VERSION ""

NS_ :

BS_:

BU_: VCU_LE CHUD_LE VKM_LE RCRM_LE VPM_LE EDI_LE V2V_LE TCP_LE CSM_LE UHP_Low_LE TouchPad_LE RSE_LE RSC_LE RSA_LE PDIM_LE OTIM_LE ICS_LE LVMPC_LE LVMNav_LE DVB_T_LE ONSTAR_LE HUD_LE IPC_LE RadioHead_LE CHM_LE Dummy_LE CGM_LE AMP_LE

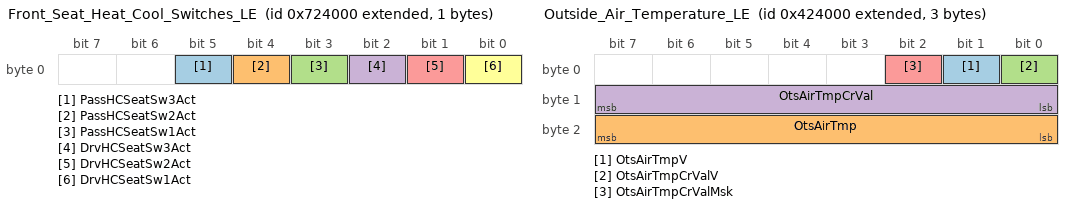
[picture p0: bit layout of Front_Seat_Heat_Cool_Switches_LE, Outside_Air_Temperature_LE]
BO_ 2154971136 Front_Seat_Heat_Cool_Switches_LE: 1 ICS_LE
 SG_ PassHCSeatSw3Act : 5|1@0+ (1,0) [0|1] ""  CGM_LE
 SG_ PassHCSeatSw2Act : 4|1@0+ (1,0) [0|1] ""  CGM_LE
 SG_ PassHCSeatSw1Act : 3|1@0+ (1,0) [0|1] ""  CGM_LE
 SG_ DrvHCSeatSw3Act : 2|1@0+ (1,0) [0|1] ""  CGM_LE
 SG_ DrvHCSeatSw2Act : 1|1@0+ (1,0) [0|1] ""  CGM_LE
 SG_ DrvHCSeatSw1Act : 0|1@0+ (1,0) [0|1] ""  CGM_LE

BO_ 2154962944 Front_Seat_Heat_Cool_Control_LE: 4 CGM_LE
 SG_ PassHCSMInd3 : 8|1@0+ (1,0) [0|1] ""  CSM_LE,ONSTAR_LE,ICS_LE
 SG_ PassHCSMInd2 : 9|1@0+ (1,0) [0|1] ""  CSM_LE,ONSTAR_LE,ICS_LE
 SG_ PassHCSMInd1 : 10|1@0+ (1,0) [0|1] ""  CSM_LE,ONSTAR_LE,ICS_LE
 SG_ PassHCSMIndReq : 12|2@0+ (1,0) [0|3] ""  CSM_LE,ONSTAR_LE,ICS_LE
 SG_ PassHCSLSeatLev5 : 24|1@0+ (1,0) [0|1] ""  CSM_LE,ONSTAR_LE,VCU_LE,IPC_LE,ICS_LE
 SG_ PassHCSLSeatLev4 : 25|1@0+ (1,0) [0|1] ""  CSM_LE,ONSTAR_LE,VCU_LE,IPC_LE,ICS_LE
 SG_ PassHCSLSeatLev3 : 26|1@0+ (1,0) [0|1] ""  CSM_LE,ONSTAR_LE,VCU_LE,IPC_LE,ICS_LE
 SG_ PassHCSLSeatLev2 : 27|1@0+ (1,0) [0|1] ""  CSM_LE,ONSTAR_LE,VCU_LE,IPC_LE,ICS_LE
 SG_ PassHCSLSeatLev1 : 28|1@0+ (1,0) [0|1] ""  CSM_LE,ONSTAR_LE,VCU_LE,IPC_LE,ICS_LE
 SG_ PassHCSLIndReq : 30|2@0+ (1,0) [0|3] ""  CSM_LE,ONSTAR_LE,VCU_LE,IPC_LE,ICS_LE
 SG_ DrvHCSMInd1 : 2|1@0+ (1,0) [0|1] ""  CSM_LE,ONSTAR_LE,ICS_LE
 SG_ DrvHCSMIndReq : 4|2@0+ (1,0) [0|3] ""  CSM_LE,ONSTAR_LE,ICS_LE
 SG_ DrvHCSMInd3 : 0|1@0+ (1,0) [0|1] ""  CSM_LE,ONSTAR_LE,ICS_LE
 SG_ DrvHCSMInd2 : 1|1@0+ (1,0) [0|1] ""  CSM_LE,ONSTAR_LE,ICS_LE
 SG_ DrvHCSLSeatLev5 : 16|1@0+ (1,0) [0|1] ""  CSM_LE,ONSTAR_LE,VCU_LE,IPC_LE,ICS_LE
 SG_ DrvHCSLSeatLev4 : 17|1@0+ (1,0) [0|1] ""  CSM_LE,ONSTAR_LE,VCU_LE,IPC_LE,ICS_LE
 SG_ DrvHCSLSeatLev3 : 18|1@0+ (1,0) [0|1] ""  CSM_LE,ONSTAR_LE,VCU_LE,IPC_LE,ICS_LE
 SG_ DrvHCSLSeatLev2 : 19|1@0+ (1,0) [0|1] ""  CSM_LE,ONSTAR_LE,VCU_LE,IPC_LE,ICS_LE
 SG_ DrvHCSLSeatLev1 : 20|1@0+ (1,0) [0|1] ""  CSM_LE,ONSTAR_LE,VCU_LE,IPC_LE,ICS_LE
 SG_ DrvHCSLIndReq : 22|2@0+ (1,0) [0|3] ""  CSM_LE,ONSTAR_LE,VCU_LE,IPC_LE,ICS_LE

BO_ 2151825408 Outside_Air_Temperature_LE: 3 IPC_LE
 SG_ OtsAirTmpV : 1|1@0+ (1,0) [0|1] ""  LVMPC_LE,RSE_LE,CSM_LE,EDI_LE,LVMNav_LE,VCU_LE,RadioHead_LE,CGM_LE
 SG_ OtsAirTmp : 23|8@0+ (0.5,-40) [-40|87.5] "deg C"  LVMPC_LE,RSE_LE,CSM_LE,EDI_LE,LVMNav_LE,VCU_LE,RadioHead_LE,ICS_LE,CGM_LE
 SG_ OtsAirTmpCrValV : 0|1@0+ (1,0) [0|1] ""  EDI_LE,CSM_LE,LVMNav_LE,RadioHead_LE,VCU_LE,IPC_LE,CGM_LE
 SG_ OtsAirTmpCrVal : 15|8@0+ (0.5,-40) [-40|87.5] "deg C"  TCP_LE,ONSTAR_LE,EDI_LE,CSM_LE,LVMNav_LE,RadioHead_LE,VCU_LE,IPC_LE,CGM_LE
 SG_ OtsAirTmpCrValMsk : 2|1@0+ (1,0) [0|1] ""  EDI_LE,CSM_LE,LVMNav_LE,RadioHead_LE,VCU_LE,IPC_LE,CGM_LE

BO_ 2150760448 Airbag_Impact_Data_LE: 8 CGM_LE
 SG_ NotSndRwRtSeatStat : 13|2@0+ (1,0) [0|3] ""  TCP_LE,ONSTAR_LE
 SG_ NotSndRwMdlSeatStat : 11|2@0+ (1,0) [0|3] ""  TCP_LE,ONSTAR_LE
 SG_ NotSndRwLtSeatStat : 15|2@0+ (1,0) [0|3] ""  TCP_LE,ONSTAR_LE
 SG_ NotPsSeatStat : 5|2@0+ (1,0) [0|3] ""  TCP_LE,ONSTAR_LE
 SG_ NotDrvSeatStat : 7|2@0+ (1,0) [0|3] ""  TCP_LE,ONSTAR_LE
 SG_ NotSecRowRtSeaOccStat : 9|2@0+ (1,0) [0|3] ""  TCP_LE,ONSTAR_LE
 SG_ NotSecRowLeSeaOccStat : 25|2@0+ (1,0) [0|3] ""  TCP_LE,ONSTAR_LE
 SG_ NotSecRowCtSeaOccStat : 27|2@0+ (1,0) [0|3] ""  TCP_LE,ONSTAR_LE
 SG_ NotiFrntPasSeatOccSta : 34|3@0+ (1,0) [0|7] ""  TCP_LE,ONSTAR_LE
 SG_ NotEventStat : 17|2@0+ (1,0) [0|3] ""  VPM_LE,TCP_LE,ONSTAR_LE
 SG_ NotiEventCount : 63|8@0+ (1,0) [0|255] ""  TCP_LE,ONSTAR_LE
 SG_ NESSRoSevSt : 48|1@0+ (1,0) [0|1] ""  TCP_LE,ONSTAR_LE
 SG_ NESSRiSiSevSt : 49|1@0+ (1,0) [0|1] ""  TCP_LE,ONSTAR_LE
 SG_ NESSReImpSevSt : 50|1@0+ (1,0) [0|1] ""  TCP_LE,ONSTAR_LE
 SG_ NESSLeSiSevSt : 51|1@0+ (1,0) [0|1] ""  TCP_LE,ONSTAR_LE
 SG_ NESSFrImpSt2SevSt : 52|1@0+ (1,0) [0|1] ""  TCP_LE,ONSTAR_LE
 SG_ NESSFrImpSt1SevSt : 53|1@0+ (1,0) [0|1] ""  TCP_LE,ONSTAR_LE
 SG_ NESSFrImpPreSevSt : 54|1@0+ (1,0) [0|1] ""  TCP_LE,ONSTAR_LE
 SG_ NEDLSRtSdArbgDld : 41|1@0+ (1,0) [0|1] ""  VCU_LE,CSM_LE,RadioHead_LE,TCP_LE,ONSTAR_LE
 SG_ NEDLSLtSdArbgDld : 42|1@0+ (1,0) [0|1] ""  VCU_LE,CSM_LE,RadioHead_LE,TCP_LE,ONSTAR_LE
 SG_ NEDLSSdCrtnArbgDpld : 40|1@0+ (1,0) [0|1] ""  VCU_LE,CSM_LE,RadioHead_LE,TCP_LE,ONSTAR_LE
 SG_ NEDLSPaFrSt2De : 43|1@0+ (1,0) [0|1] ""  VCU_LE,CSM_LE,RadioHead_LE,TCP_LE,ONSTAR_LE
 SG_ NEDLSPaFrSt1De : 44|1@0+ (1,0) [0|1] ""  VCU_LE,CSM_LE,RadioHead_LE,TCP_LE,ONSTAR_LE
 SG_ NEDLSDrFrSt2De : 45|1@0+ (1,0) [0|1] ""  VCU_LE,CSM_LE,RadioHead_LE,TCP_LE,ONSTAR_LE
 SG_ NEDLSDrFrSt1De : 46|1@0+ (1,0) [0|1] ""  VCU_LE,CSM_LE,RadioHead_LE,TCP_LE,ONSTAR_LE
 SG_ SIRDpl : 1|1@0+ (1,0) [0|1] ""  V2V_LE,TCP_LE,CSM_LE,OTIM_LE,ONSTAR_LE,VCU_LE,RadioHead_LE,ICS_LE

BO_ 1609 USDT_Resp_From_OTIM_LE: 8 OTIM_LE
 SG_ DgnInf : 7|64@0+ (1,0) [0|1.84467440737096E+019] ""  CSM_LE,CGM_LE,TCP_LE,ONSTAR_LE

BO_ 1577 VNMF_LE_629_OTIM: 8 OTIM_LE
 SG_ VectraSpcNWMgtD : 7|64@0+ (1,0) [0|1.84467440737096E+019] ""  RCRM_LE,V2V_LE,TCP_LE,UHP_Low_LE,LVMNav_LE,ONSTAR_LE,VKM_LE,RSC_LE,RSE_LE,RSA_LE,PDIM_LE,CHUD_LE,LVMPC_LE,IPC_LE,ICS_LE,VPM_LE,HUD_LE,TouchPad_LE,DVB_T_LE,VCU_LE,CSM_LE,RadioHead_LE,CHM_LE,AMP_LE,CGM_LE

BO_ 1353 UUDT_Resp_From_OTIM_LE: 8 OTIM_LE
 SG_ DgnInf_LS549 : 7|64@0+ (1,0) [0|1.84467440737096E+019] ""  CSM_LE,CGM_LE,TCP_LE,ONSTAR_LE

BO_ 2159239168 ODI_TEL_2_OTIM_LE: 8 ONSTAR_LE
 SG_ ODI_TEL2OTIM : 7|64@0+ (1,0) [0|1.84467440737096E+019] ""  OTIM_LE

BO_ 2159230976 ODI_OTIM_2_TEL_LE: 8 OTIM_LE
 SG_ ODI_OTIM2TEL : 7|64@0+ (1,0) [0|1.84467440737096E+019] ""  TCP_LE,ONSTAR_LE

BO_ 2159149056 ODI_TEL_2_CenterStack_LE: 8 ONSTAR_LE
 SG_ ODI_TEL2CntrStck : 7|64@0+ (1,0) [0|1.84467440737096E+019] ""  CSM_LE,VCU_LE,RadioHead_LE

BO_ 2159083520 ODI_TEL_2_IPC_LE: 8 ONSTAR_LE
 SG_ ODI_TEL2IPC : 7|64@0+ (1,0) [0|1.84467440737096E+019] ""  VCU_LE,IPC_LE

BO_ 2150227968 Phone_Speech_Rec_Status_LE: 1 ONSTAR_LE
 SG_ PhnSpRcgnApSt : 1|2@0+ (1,0) [0|3] ""  CSM_LE,OTIM_LE,VCU_LE,RadioHead_LE

BO_ 2150219776 Voice_Recognition_Status_LE: 1 RadioHead_LE
 SG_ PhnSpRcgnRq : 1|2@0+ (1,0) [0|3] ""  UHP_Low_LE,ONSTAR_LE
 SG_ VcRecVcFdbckSt : 3|2@0+ (1,0) [0|3] ""  UHP_Low_LE

BO_ 1358 UUDT_Resp_From_RSC_LE: 8 RSC_LE
 SG_ DgnInf_LS54E : 7|64@0+ (1,0) [0|1.84467440737096E+019] ""  CSM_LE,CGM_LE,TCP_LE,ONSTAR_LE

BO_ 1582 VNMF_LE_62E_RSC: 8 RSC_LE
 SG_ VectraSpcNWMgtD : 7|64@0+ (1,0) [0|1.84467440737096E+019] ""  RCRM_LE,V2V_LE,TCP_LE,UHP_Low_LE,LVMNav_LE,ONSTAR_LE,RSE_LE,RSA_LE,PDIM_LE,OTIM_LE,CHUD_LE,LVMPC_LE,IPC_LE,ICS_LE,VPM_LE,HUD_LE,TouchPad_LE,DVB_T_LE,VCU_LE,CSM_LE,RadioHead_LE,CHM_LE,AMP_LE,CGM_LE

BO_ 1614 USDT_Resp_From_RSC_LE: 8 RSC_LE
 SG_ DgnInf : 7|64@0+ (1,0) [0|1.84467440737096E+019] ""  CSM_LE,CGM_LE,TCP_LE,ONSTAR_LE

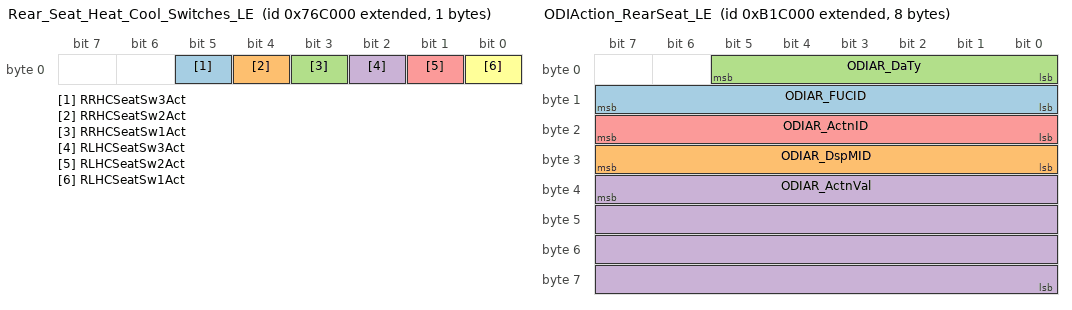
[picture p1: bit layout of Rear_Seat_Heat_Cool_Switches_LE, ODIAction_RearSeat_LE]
BO_ 2155266048 Rear_Seat_Heat_Cool_Switches_LE: 1 RSA_LE
 SG_ RRHCSeatSw3Act : 5|1@0+ (1,0) [0|1] ""  CGM_LE
 SG_ RRHCSeatSw2Act : 4|1@0+ (1,0) [0|1] ""  CGM_LE
 SG_ RRHCSeatSw1Act : 3|1@0+ (1,0) [0|1] ""  CGM_LE
 SG_ RLHCSeatSw3Act : 2|1@0+ (1,0) [0|1] ""  CGM_LE
 SG_ RLHCSeatSw2Act : 1|1@0+ (1,0) [0|1] ""  CGM_LE
 SG_ RLHCSeatSw1Act : 0|1@0+ (1,0) [0|1] ""  CGM_LE

BO_ 2155249664 Rear_Seat_Heat_Cool_Control_LE: 4 CGM_LE
 SG_ RRHCSMInd3 : 8|1@0+ (1,0) [0|1] ""  RSC_LE,RSA_LE
 SG_ RRHCSMInd2 : 9|1@0+ (1,0) [0|1] ""  RSC_LE,RSA_LE
 SG_ RRHCSMInd1 : 10|1@0+ (1,0) [0|1] ""  RSC_LE,RSA_LE
 SG_ RRHCSMIndReq : 12|2@0+ (1,0) [0|3] ""  RSC_LE,RSA_LE
 SG_ RRHCSLSeatLev5 : 24|1@0+ (1,0) [0|1] ""  VCU_LE,IPC_LE,RSC_LE,RSA_LE
 SG_ RRHCSLSeatLev4 : 25|1@0+ (1,0) [0|1] ""  VCU_LE,IPC_LE,RSC_LE,RSA_LE
 SG_ RRHCSLSeatLev3 : 26|1@0+ (1,0) [0|1] ""  VCU_LE,IPC_LE,RSC_LE,RSA_LE
 SG_ RRHCSLSeatLev2 : 27|1@0+ (1,0) [0|1] ""  VCU_LE,IPC_LE,RSC_LE,RSA_LE
 SG_ RRHCSLSeatLev1 : 28|1@0+ (1,0) [0|1] ""  VCU_LE,IPC_LE,RSC_LE,RSA_LE
 SG_ RRHCSLIndReq : 30|2@0+ (1,0) [0|3] ""  VCU_LE,IPC_LE,RSC_LE,RSA_LE
 SG_ RLHCSMInd3 : 0|1@0+ (1,0) [0|1] ""  RSC_LE,RSA_LE
 SG_ RLHCSMInd2 : 1|1@0+ (1,0) [0|1] ""  RSC_LE,RSA_LE
 SG_ RLHCSMInd1 : 2|1@0+ (1,0) [0|1] ""  RSC_LE,RSA_LE
 SG_ RLHCSMIndReq : 4|2@0+ (1,0) [0|3] ""  RSC_LE,RSA_LE
 SG_ RLHCSLSeatLev5 : 16|1@0+ (1,0) [0|1] ""  VCU_LE,IPC_LE,RSC_LE,RSA_LE
 SG_ RLHCSLSeatLev4 : 17|1@0+ (1,0) [0|1] ""  VCU_LE,IPC_LE,RSC_LE,RSA_LE
 SG_ RLHCSLSeatLev3 : 18|1@0+ (1,0) [0|1] ""  VCU_LE,IPC_LE,RSC_LE,RSA_LE
 SG_ RLHCSLSeatLev2 : 19|1@0+ (1,0) [0|1] ""  VCU_LE,IPC_LE,RSC_LE,RSA_LE
 SG_ RLHCSLSeatLev1 : 20|1@0+ (1,0) [0|1] ""  VCU_LE,IPC_LE,RSC_LE,RSA_LE
 SG_ RLHCSLIndReq : 22|2@0+ (1,0) [0|3] ""  VCU_LE,IPC_LE,RSC_LE,RSA_LE

BO_ 2154741760 RSA_Status_LE: 1 RSC_LE
 SG_ RSAPrsnt : 0|1@0+ (1,0) [0|1] ""  CSM_LE,VCU_LE,RadioHead_LE

BO_ 2159132672 ODIAction_RearSeat_LE: 8 RSA_LE
 SG_ ODIAR_FUCID : 15|8@0+ (1,0) [0|255] ""  CGM_LE,VCU_LE,CSM_LE,RadioHead_LE
 SG_ ODIAR_DspMID : 31|8@0+ (1,0) [0|255] ""  CGM_LE,VCU_LE,CSM_LE,RadioHead_LE
 SG_ ODIAR_DaTy : 5|6@0+ (1,0) [0|63] ""  CGM_LE,VCU_LE,CSM_LE,RadioHead_LE
 SG_ ODIAR_ActnVal : 39|32@0+ (1,0) [0|4294967295] ""  CGM_LE,VCU_LE,CSM_LE,RadioHead_LE
 SG_ ODIAR_ActnID : 23|8@0+ (1,0) [0|255] ""  CGM_LE,VCU_LE,CSM_LE,RadioHead_LE

BO_ 2158968832 ODI_RearSeat_2_Centerstack_LE: 8 RSA_LE
 SG_ ODI_RSD2CntrStck : 7|64@0+ (1,0) [0|1.84467440737096E+019] ""  CSM_LE,VCU_LE,RadioHead_LE

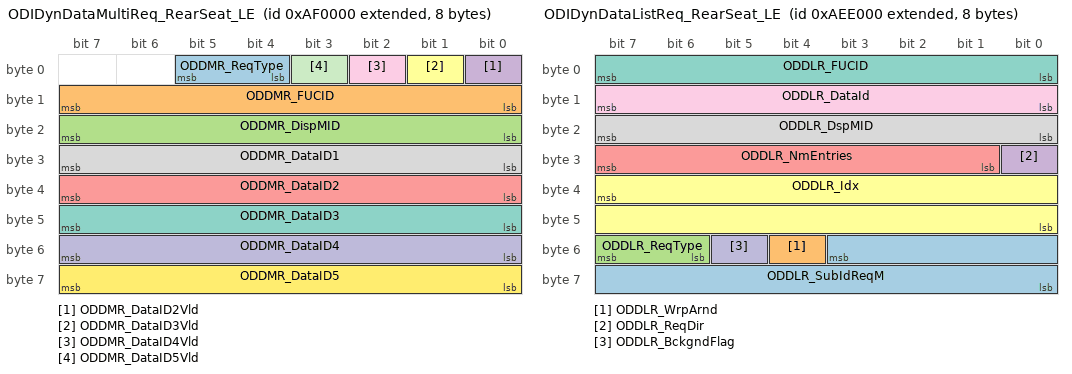
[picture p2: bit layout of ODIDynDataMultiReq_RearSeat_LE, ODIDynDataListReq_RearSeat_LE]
BO_ 2158952448 ODIDynDataMultiReq_RearSeat_LE: 8 RSA_LE
 SG_ ODDMR_ReqType : 5|2@0+ (1,0) [0|3] ""  CGM_LE,VCU_LE,CSM_LE,RadioHead_LE
 SG_ ODDMR_FUCID : 15|8@0+ (1,0) [0|255] ""  CGM_LE,VCU_LE,CSM_LE,RadioHead_LE
 SG_ ODDMR_DispMID : 23|8@0+ (1,0) [0|255] ""  CGM_LE,VCU_LE,CSM_LE,RadioHead_LE
 SG_ ODDMR_DataID2Vld : 0|1@0+ (1,0) [0|1] ""  CGM_LE,VCU_LE,CSM_LE,RadioHead_LE
 SG_ ODDMR_DataID2 : 39|8@0+ (1,0) [0|255] ""  CGM_LE,VCU_LE,CSM_LE,RadioHead_LE
 SG_ ODDMR_DataID3Vld : 1|1@0+ (1,0) [0|1] ""  CGM_LE,VCU_LE,CSM_LE,RadioHead_LE
 SG_ ODDMR_DataID3 : 47|8@0+ (1,0) [0|255] ""  CGM_LE,VCU_LE,CSM_LE,RadioHead_LE
 SG_ ODDMR_DataID1 : 31|8@0+ (1,0) [0|255] ""  CGM_LE,VCU_LE,CSM_LE,RadioHead_LE
 SG_ ODDMR_DataID4Vld : 2|1@0+ (1,0) [0|1] ""  CGM_LE,VCU_LE,CSM_LE,RadioHead_LE
 SG_ ODDMR_DataID4 : 55|8@0+ (1,0) [0|255] ""  CGM_LE,VCU_LE,CSM_LE,RadioHead_LE
 SG_ ODDMR_DataID5Vld : 3|1@0+ (1,0) [0|1] ""  CGM_LE,VCU_LE,CSM_LE,RadioHead_LE
 SG_ ODDMR_DataID5 : 63|8@0+ (1,0) [0|255] ""  CGM_LE,VCU_LE,CSM_LE,RadioHead_LE

BO_ 2158944256 ODIDynDataListReq_RearSeat_LE: 8 RSA_LE
 SG_ ODDLR_SubIdReqM : 51|12@0+ (1,0) [0|4095] ""  VCU_LE,CSM_LE,RadioHead_LE
 SG_ ODDLR_WrpArnd : 52|1@0+ (1,0) [0|1] ""  VCU_LE,CSM_LE,RadioHead_LE
 SG_ ODDLR_ReqType : 55|2@0+ (1,0) [0|3] ""  VCU_LE,CSM_LE,RadioHead_LE
 SG_ ODDLR_ReqDir : 24|1@0+ (1,0) [0|1] ""  VCU_LE,CSM_LE,RadioHead_LE
 SG_ ODDLR_NmEntries : 31|7@0+ (1,0) [0|127] ""  VCU_LE,CSM_LE,RadioHead_LE
 SG_ ODDLR_Idx : 39|16@0+ (1,0) [0|65535] ""  VCU_LE,CSM_LE,RadioHead_LE
 SG_ ODDLR_FUCID : 7|8@0+ (1,0) [0|255] ""  VCU_LE,CSM_LE,RadioHead_LE
 SG_ ODDLR_DspMID : 23|8@0+ (1,0) [0|255] ""  VCU_LE,CSM_LE,RadioHead_LE
 SG_ ODDLR_DataId : 15|8@0+ (1,0) [0|255] ""  VCU_LE,CSM_LE,RadioHead_LE
 SG_ ODDLR_BckgndFlag : 53|1@0+ (1,0) [0|1] ""  VCU_LE,CSM_LE,RadioHead_LE

BO_ 1616 USDT_Resp_From_HUD_LE: 8 HUD_LE
 SG_ DgnInf : 7|64@0+ (1,0) [0|1.84467440737096E+019] ""  CSM_LE,CGM_LE,TCP_LE,ONSTAR_LE

BO_ 1584 VNMF_LE_630_HUD: 8 HUD_LE
 SG_ VectraSpcNWMgtD : 7|64@0+ (1,0) [0|1.84467440737096E+019] ""  RCRM_LE,V2V_LE,TCP_LE,UHP_Low_LE,LVMNav_LE,ONSTAR_LE,VKM_LE,RSC_LE,RSE_LE,RSA_LE,PDIM_LE,OTIM_LE,CHUD_LE,LVMPC_LE,IPC_LE,ICS_LE,TouchPad_LE,DVB_T_LE,VCU_LE,CSM_LE,RadioHead_LE,CHM_LE,AMP_LE,CGM_LE

BO_ 1360 UUDT_Resp_From_HUD_LE: 8 HUD_LE
 SG_ DgnInf_LS550 : 7|64@0+ (1,0) [0|1.84467440737096E+019] ""  CSM_LE,CGM_LE,TCP_LE,ONSTAR_LE

BO_ 2159206400 ODI_AuxIP_2_IPC_LE: 8 HUD_LE
 SG_ ODI_AxIP2IPC : 7|64@0+ (1,0) [0|1.84467440737096E+019] ""  VCU_LE,IPC_LE

BO_ 2159190016 ODI_AuxIP_2_CenterStack_LE: 8 HUD_LE
 SG_ ODI_AxIP2CntrStck : 7|64@0+ (1,0) [0|1.84467440737096E+019] ""  VCU_LE,RadioHead_LE

BO_ 2159124480 ODI_AuxIP_2_TEL_LE: 8 HUD_LE
 SG_ ODI_AxIP2TEL : 7|64@0+ (1,0) [0|1.84467440737096E+019] ""  VCU_LE,RadioHead_LE,UHP_Low_LE,ONSTAR_LE

BO_ 2159108096 ODI_AuxIP_2_DAB_LE: 8 HUD_LE
 SG_ ODI_AxIP2DAB : 7|64@0+ (1,0) [0|1.84467440737096E+019] ""  VCU_LE,RadioHead_LE

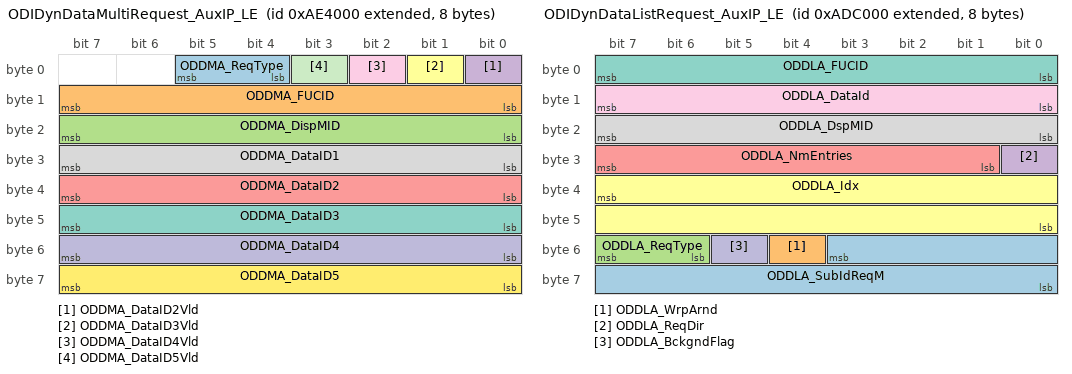
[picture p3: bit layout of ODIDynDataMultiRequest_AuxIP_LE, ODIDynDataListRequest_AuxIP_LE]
BO_ 2158903296 ODIDynDataMultiRequest_AuxIP_LE: 8 HUD_LE
 SG_ ODDMA_ReqType : 5|2@0+ (1,0) [0|3] ""  CGM_LE,IPC_LE,UHP_Low_LE,ONSTAR_LE,VCU_LE,RadioHead_LE
 SG_ ODDMA_FUCID : 15|8@0+ (1,0) [0|255] ""  CGM_LE,IPC_LE,UHP_Low_LE,ONSTAR_LE,VCU_LE,RadioHead_LE
 SG_ ODDMA_DispMID : 23|8@0+ (1,0) [0|255] ""  CGM_LE,IPC_LE,UHP_Low_LE,ONSTAR_LE,VCU_LE,RadioHead_LE
 SG_ ODDMA_DataID2Vld : 0|1@0+ (1,0) [0|1] ""  CGM_LE,IPC_LE,UHP_Low_LE,ONSTAR_LE,VCU_LE,RadioHead_LE
 SG_ ODDMA_DataID2 : 39|8@0+ (1,0) [0|255] ""  CGM_LE,IPC_LE,UHP_Low_LE,ONSTAR_LE,VCU_LE,RadioHead_LE
 SG_ ODDMA_DataID3Vld : 1|1@0+ (1,0) [0|1] ""  CGM_LE,IPC_LE,UHP_Low_LE,ONSTAR_LE,VCU_LE,RadioHead_LE
 SG_ ODDMA_DataID3 : 47|8@0+ (1,0) [0|255] ""  CGM_LE,IPC_LE,UHP_Low_LE,ONSTAR_LE,VCU_LE,RadioHead_LE
 SG_ ODDMA_DataID1 : 31|8@0+ (1,0) [0|255] ""  CGM_LE,IPC_LE,UHP_Low_LE,ONSTAR_LE,VCU_LE,RadioHead_LE
 SG_ ODDMA_DataID4Vld : 2|1@0+ (1,0) [0|1] ""  CGM_LE,IPC_LE,UHP_Low_LE,ONSTAR_LE,VCU_LE,RadioHead_LE
 SG_ ODDMA_DataID4 : 55|8@0+ (1,0) [0|255] ""  CGM_LE,IPC_LE,UHP_Low_LE,ONSTAR_LE,VCU_LE,RadioHead_LE
 SG_ ODDMA_DataID5Vld : 3|1@0+ (1,0) [0|1] ""  CGM_LE,IPC_LE,UHP_Low_LE,ONSTAR_LE,VCU_LE,RadioHead_LE
 SG_ ODDMA_DataID5 : 63|8@0+ (1,0) [0|255] ""  CGM_LE,IPC_LE,UHP_Low_LE,ONSTAR_LE,VCU_LE,RadioHead_LE

BO_ 2158870528 ODIDynDataListRequest_AuxIP_LE: 8 HUD_LE
 SG_ ODDLA_SubIdReqM : 51|12@0+ (1,0) [0|4095] ""  CGM_LE,IPC_LE,UHP_Low_LE,ONSTAR_LE,VCU_LE,RadioHead_LE
 SG_ ODDLA_WrpArnd : 52|1@0+ (1,0) [0|1] ""  CGM_LE,IPC_LE,UHP_Low_LE,ONSTAR_LE,VCU_LE,RadioHead_LE
 SG_ ODDLA_ReqType : 55|2@0+ (1,0) [0|3] ""  CGM_LE,IPC_LE,UHP_Low_LE,ONSTAR_LE,VCU_LE,RadioHead_LE
 SG_ ODDLA_ReqDir : 24|1@0+ (1,0) [0|1] ""  CGM_LE,IPC_LE,UHP_Low_LE,ONSTAR_LE,VCU_LE,RadioHead_LE
 SG_ ODDLA_NmEntries : 31|7@0+ (1,0) [0|127] ""  CGM_LE,IPC_LE,UHP_Low_LE,ONSTAR_LE,VCU_LE,RadioHead_LE
 SG_ ODDLA_Idx : 39|16@0+ (1,0) [0|65535] ""  CGM_LE,IPC_LE,UHP_Low_LE,ONSTAR_LE,VCU_LE,RadioHead_LE
 SG_ ODDLA_FUCID : 7|8@0+ (1,0) [0|255] ""  CGM_LE,IPC_LE,UHP_Low_LE,ONSTAR_LE,VCU_LE,RadioHead_LE
 SG_ ODDLA_DspMID : 23|8@0+ (1,0) [0|255] ""  CGM_LE,IPC_LE,UHP_Low_LE,ONSTAR_LE,VCU_LE,RadioHead_LE
 SG_ ODDLA_DataId : 15|8@0+ (1,0) [0|255] ""  CGM_LE,IPC_LE,UHP_Low_LE,ONSTAR_LE,VCU_LE,RadioHead_LE
 SG_ ODDLA_BckgndFlag : 53|1@0+ (1,0) [0|1] ""  CGM_LE,IPC_LE,UHP_Low_LE,ONSTAR_LE,VCU_LE,RadioHead_LE

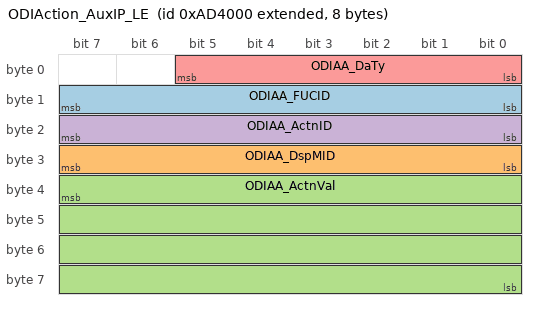
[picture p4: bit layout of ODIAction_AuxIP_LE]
BO_ 2158837760 ODIAction_AuxIP_LE: 8 HUD_LE
 SG_ ODIAA_FUCID : 15|8@0+ (1,0) [0|255] ""  CGM_LE,IPC_LE,UHP_Low_LE,ONSTAR_LE,VCU_LE,RadioHead_LE
 SG_ ODIAA_DspMID : 31|8@0+ (1,0) [0|255] ""  CGM_LE,IPC_LE,UHP_Low_LE,ONSTAR_LE,VCU_LE,RadioHead_LE
 SG_ ODIAA_ActnVal : 39|32@0+ (1,0) [0|4294967295] ""  CGM_LE,IPC_LE,UHP_Low_LE,ONSTAR_LE,VCU_LE,RadioHead_LE
 SG_ ODIAA_ActnID : 23|8@0+ (1,0) [0|255] ""  CGM_LE,IPC_LE,UHP_Low_LE,ONSTAR_LE,VCU_LE,RadioHead_LE
 SG_ ODIAA_DaTy : 5|6@0+ (1,0) [0|63] ""  CGM_LE,IPC_LE,UHP_Low_LE,ONSTAR_LE,VCU_LE,RadioHead_LE

BO_ 2158796800 ODIIndication_LE: 8 ONSTAR_LE
 SG_ ODII_ODIInd55 : 57|1@0+ (1,0) [0|1] ""  CSM_LE,RSC_LE,RSA_LE,TCP_LE,ONSTAR_LE,OTIM_LE,IPC_LE,CHUD_LE,HUD_LE,VCU_LE,RadioHead_LE
 SG_ ODII_ODIInd54 : 58|1@0+ (1,0) [0|1] ""  CSM_LE,RSC_LE,RSA_LE,TCP_LE,ONSTAR_LE,OTIM_LE,IPC_LE,CHUD_LE,HUD_LE,VCU_LE,RadioHead_LE
 SG_ ODII_ODIInd53 : 59|1@0+ (1,0) [0|1] ""  CSM_LE,RSC_LE,RSA_LE,TCP_LE,ONSTAR_LE,OTIM_LE,IPC_LE,CHUD_LE,HUD_LE,VCU_LE,RadioHead_LE
 SG_ ODII_ODIInd52 : 60|1@0+ (1,0) [0|1] ""  CSM_LE,RSC_LE,RSA_LE,TCP_LE,ONSTAR_LE,OTIM_LE,IPC_LE,CHUD_LE,HUD_LE,VCU_LE,RadioHead_LE
 SG_ ODII_ODIInd51 : 61|1@0+ (1,0) [0|1] ""  CSM_LE,RSC_LE,RSA_LE,TCP_LE,ONSTAR_LE,OTIM_LE,IPC_LE,CHUD_LE,HUD_LE,VCU_LE,RadioHead_LE
 SG_ ODII_ODIInd50 : 62|1@0+ (1,0) [0|1] ""  CSM_LE,RSC_LE,RSA_LE,TCP_LE,ONSTAR_LE,OTIM_LE,IPC_LE,CHUD_LE,HUD_LE,VCU_LE,RadioHead_LE
 SG_ ODII_ODIInd27 : 37|1@0+ (1,0) [0|1] ""  CSM_LE,RSC_LE,RSA_LE,TCP_LE,ONSTAR_LE,OTIM_LE,IPC_LE,CHUD_LE,HUD_LE,VCU_LE,RadioHead_LE
 SG_ ODII_ODIInd26 : 38|1@0+ (1,0) [0|1] ""  CSM_LE,RSC_LE,RSA_LE,TCP_LE,ONSTAR_LE,OTIM_LE,IPC_LE,CHUD_LE,HUD_LE,VCU_LE,RadioHead_LE
 SG_ ODII_ODIInd25 : 39|1@0+ (1,0) [0|1] ""  CSM_LE,RSC_LE,RSA_LE,TCP_LE,ONSTAR_LE,OTIM_LE,IPC_LE,CHUD_LE,HUD_LE,VCU_LE,RadioHead_LE
 SG_ ODII_ODIInd24 : 24|1@0+ (1,0) [0|1] ""  CSM_LE,RSC_LE,RSA_LE,TCP_LE,ONSTAR_LE,OTIM_LE,IPC_LE,CHUD_LE,HUD_LE,VCU_LE,RadioHead_LE
 SG_ ODII_ODIInd23 : 25|1@0+ (1,0) [0|1] ""  CSM_LE,RSC_LE,RSA_LE,TCP_LE,ONSTAR_LE,OTIM_LE,IPC_LE,CHUD_LE,HUD_LE,VCU_LE,RadioHead_LE
 SG_ ODII_ODIInd22 : 26|1@0+ (1,0) [0|1] ""  CSM_LE,RSC_LE,RSA_LE,TCP_LE,ONSTAR_LE,OTIM_LE,IPC_LE,CHUD_LE,HUD_LE,VCU_LE,RadioHead_LE
 SG_ ODII_ODIInd21 : 27|1@0+ (1,0) [0|1] ""  CSM_LE,RSC_LE,RSA_LE,TCP_LE,ONSTAR_LE,OTIM_LE,IPC_LE,CHUD_LE,HUD_LE,VCU_LE,RadioHead_LE
 SG_ ODII_ODIInd20 : 28|1@0+ (1,0) [0|1] ""  CSM_LE,RSC_LE,RSA_LE,TCP_LE,ONSTAR_LE,OTIM_LE,IPC_LE,CHUD_LE,HUD_LE,VCU_LE,RadioHead_LE
 SG_ ODII_ODIInd19 : 29|1@0+ (1,0) [0|1] ""  CSM_LE,RSC_LE,RSA_LE,TCP_LE,ONSTAR_LE,OTIM_LE,IPC_LE,CHUD_LE,HUD_LE,VCU_LE,RadioHead_LE
 SG_ ODII_ODIInd18 : 30|1@0+ (1,0) [0|1] ""  CSM_LE,RSC_LE,RSA_LE,TCP_LE,ONSTAR_LE,OTIM_LE,IPC_LE,CHUD_LE,HUD_LE,VCU_LE,RadioHead_LE
 SG_ ODII_ODIInd17 : 31|1@0+ (1,0) [0|1] ""  CSM_LE,RSC_LE,RSA_LE,TCP_LE,ONSTAR_LE,OTIM_LE,IPC_LE,CHUD_LE,HUD_LE,VCU_LE,RadioHead_LE
 SG_ ODII_ODIInd16 : 16|1@0+ (1,0) [0|1] ""  CSM_LE,RSC_LE,RSA_LE,TCP_LE,ONSTAR_LE,OTIM_LE,IPC_LE,CHUD_LE,HUD_LE,VCU_LE,RadioHead_LE
 SG_ ODII_ODIInd15 : 17|1@0+ (1,0) [0|1] ""  CSM_LE,RSC_LE,RSA_LE,TCP_LE,ONSTAR_LE,OTIM_LE,IPC_LE,CHUD_LE,HUD_LE,VCU_LE,RadioHead_LE
 SG_ ODII_ODIInd14 : 18|1@0+ (1,0) [0|1] ""  CSM_LE,RSC_LE,RSA_LE,TCP_LE,ONSTAR_LE,OTIM_LE,IPC_LE,CHUD_LE,HUD_LE,VCU_LE,RadioHead_LE
 SG_ ODII_ODIInd13 : 19|1@0+ (1,0) [0|1] ""  CSM_LE,RSC_LE,RSA_LE,TCP_LE,ONSTAR_LE,OTIM_LE,IPC_LE,CHUD_LE,HUD_LE,VCU_LE,RadioHead_LE
 SG_ ODII_ODIInd12 : 20|1@0+ (1,0) [0|1] ""  CSM_LE,RSC_LE,RSA_LE,TCP_LE,ONSTAR_LE,OTIM_LE,IPC_LE,CHUD_LE,HUD_LE,VCU_LE,RadioHead_LE
 SG_ ODII_ODIInd11 : 21|1@0+ (1,0) [0|1] ""  CSM_LE,RSC_LE,RSA_LE,TCP_LE,ONSTAR_LE,OTIM_LE,IPC_LE,CHUD_LE,HUD_LE,VCU_LE,RadioHead_LE
 SG_ ODII_ODIInd10 : 22|1@0+ (1,0) [0|1] ""  CSM_LE,RSC_LE,RSA_LE,TCP_LE,ONSTAR_LE,OTIM_LE,IPC_LE,CHUD_LE,HUD_LE,VCU_LE,RadioHead_LE
 SG_ ODII_ODIInd9 : 23|1@0+ (1,0) [0|1] ""  CSM_LE,RSC_LE,RSA_LE,TCP_LE,ONSTAR_LE,OTIM_LE,IPC_LE,CHUD_LE,HUD_LE,VCU_LE,RadioHead_LE
 SG_ ODII_ODIInd8 : 8|1@0+ (1,0) [0|1] ""  CSM_LE,RSC_LE,RSA_LE,TCP_LE,ONSTAR_LE,OTIM_LE,IPC_LE,CHUD_LE,HUD_LE,VCU_LE,RadioHead_LE
 SG_ ODII_ODIInd7 : 9|1@0+ (1,0) [0|1] ""  CSM_LE,RSC_LE,RSA_LE,TCP_LE,ONSTAR_LE,OTIM_LE,IPC_LE,CHUD_LE,HUD_LE,VCU_LE,RadioHead_LE
 SG_ ODII_ODIInd6 : 10|1@0+ (1,0) [0|1] ""  CSM_LE,RSC_LE,RSA_LE,TCP_LE,ONSTAR_LE,OTIM_LE,IPC_LE,CHUD_LE,HUD_LE,VCU_LE,RadioHead_LE
 SG_ ODII_ODIInd5 : 11|1@0+ (1,0) [0|1] ""  CSM_LE,RSC_LE,RSA_LE,TCP_LE,ONSTAR_LE,OTIM_LE,IPC_LE,CHUD_LE,HUD_LE,VCU_LE,RadioHead_LE
 SG_ ODII_ODIInd4 : 12|1@0+ (1,0) [0|1] ""  CSM_LE,RSC_LE,RSA_LE,TCP_LE,ONSTAR_LE,OTIM_LE,IPC_LE,CHUD_LE,HUD_LE,VCU_LE,RadioHead_LE
 SG_ ODII_ODIInd3 : 13|1@0+ (1,0) [0|1] ""  CSM_LE,RSC_LE,RSA_LE,TCP_LE,ONSTAR_LE,OTIM_LE,IPC_LE,CHUD_LE,HUD_LE,VCU_LE,RadioHead_LE
 SG_ ODII_ODIInd2 : 14|1@0+ (1,0) [0|1] ""  CSM_LE,RSC_LE,RSA_LE,TCP_LE,ONSTAR_LE,OTIM_LE,IPC_LE,CHUD_LE,HUD_LE,VCU_LE,RadioHead_LE
 SG_ ODII_ODIInd1 : 15|1@0+ (1,0) [0|1] ""  CSM_LE,RSC_LE,RSA_LE,TCP_LE,ONSTAR_LE,OTIM_LE,IPC_LE,CHUD_LE,HUD_LE,VCU_LE,RadioHead_LE
 SG_ ODII_ODIInd56 : 56|1@0+ (1,0) [0|1] ""  CSM_LE,RSC_LE,RSA_LE,TCP_LE,ONSTAR_LE,OTIM_LE,IPC_LE,CHUD_LE,HUD_LE,VCU_LE,RadioHead_LE
 SG_ ODII_ODIInd49 : 63|1@0+ (1,0) [0|1] ""  CSM_LE,RSC_LE,RSA_LE,TCP_LE,ONSTAR_LE,OTIM_LE,IPC_LE,CHUD_LE,HUD_LE,VCU_LE,RadioHead_LE
 SG_ ODII_ODIInd48 : 48|1@0+ (1,0) [0|1] ""  CSM_LE,RSC_LE,RSA_LE,TCP_LE,ONSTAR_LE,OTIM_LE,IPC_LE,CHUD_LE,HUD_LE,VCU_LE,RadioHead_LE
 SG_ ODII_ODIInd47 : 49|1@0+ (1,0) [0|1] ""  CSM_LE,RSC_LE,RSA_LE,TCP_LE,ONSTAR_LE,OTIM_LE,IPC_LE,CHUD_LE,HUD_LE,VCU_LE,RadioHead_LE
 SG_ ODII_ODIInd46 : 50|1@0+ (1,0) [0|1] ""  CSM_LE,RSC_LE,RSA_LE,TCP_LE,ONSTAR_LE,OTIM_LE,IPC_LE,CHUD_LE,HUD_LE,VCU_LE,RadioHead_LE
 SG_ ODII_ODIInd45 : 51|1@0+ (1,0) [0|1] ""  CSM_LE,RSC_LE,RSA_LE,TCP_LE,ONSTAR_LE,OTIM_LE,IPC_LE,CHUD_LE,HUD_LE,VCU_LE,RadioHead_LE
 SG_ ODII_ODIInd44 : 52|1@0+ (1,0) [0|1] ""  CSM_LE,RSC_LE,RSA_LE,TCP_LE,ONSTAR_LE,OTIM_LE,IPC_LE,CHUD_LE,HUD_LE,VCU_LE,RadioHead_LE
 SG_ ODII_ODIInd43 : 53|1@0+ (1,0) [0|1] ""  CSM_LE,RSC_LE,RSA_LE,TCP_LE,ONSTAR_LE,OTIM_LE,IPC_LE,CHUD_LE,HUD_LE,VCU_LE,RadioHead_LE
 SG_ ODII_ODIInd42 : 54|1@0+ (1,0) [0|1] ""  CSM_LE,RSC_LE,RSA_LE,TCP_LE,ONSTAR_LE,OTIM_LE,IPC_LE,CHUD_LE,HUD_LE,VCU_LE,RadioHead_LE
 SG_ ODII_ODIInd41 : 55|1@0+ (1,0) [0|1] ""  CSM_LE,RSC_LE,RSA_LE,TCP_LE,ONSTAR_LE,OTIM_LE,IPC_LE,CHUD_LE,HUD_LE,VCU_LE,RadioHead_LE
 SG_ ODII_ODIInd40 : 40|1@0+ (1,0) [0|1] ""  CSM_LE,RSC_LE,RSA_LE,TCP_LE,ONSTAR_LE,OTIM_LE,IPC_LE,CHUD_LE,HUD_LE,VCU_LE,RadioHead_LE
 SG_ ODII_ODIInd39 : 41|1@0+ (1,0) [0|1] ""  CSM_LE,RSC_LE,RSA_LE,TCP_LE,ONSTAR_LE,OTIM_LE,IPC_LE,CHUD_LE,HUD_LE,VCU_LE,RadioHead_LE
 SG_ ODII_ODIInd38 : 42|1@0+ (1,0) [0|1] ""  CSM_LE,RSC_LE,RSA_LE,TCP_LE,ONSTAR_LE,OTIM_LE,IPC_LE,CHUD_LE,HUD_LE,VCU_LE,RadioHead_LE
 SG_ ODII_ODIInd37 : 43|1@0+ (1,0) [0|1] ""  CSM_LE,RSC_LE,RSA_LE,TCP_LE,ONSTAR_LE,OTIM_LE,IPC_LE,CHUD_LE,HUD_LE,VCU_LE,RadioHead_LE
 SG_ ODII_ODIInd36 : 44|1@0+ (1,0) [0|1] ""  CSM_LE,RSC_LE,RSA_LE,TCP_LE,ONSTAR_LE,OTIM_LE,IPC_LE,CHUD_LE,HUD_LE,VCU_LE,RadioHead_LE
 SG_ ODII_ODIInd35 : 45|1@0+ (1,0) [0|1] ""  CSM_LE,RSC_LE,RSA_LE,TCP_LE,ONSTAR_LE,OTIM_LE,IPC_LE,CHUD_LE,HUD_LE,VCU_LE,RadioHead_LE
 SG_ ODII_ODIInd34 : 46|1@0+ (1,0) [0|1] ""  CSM_LE,RSC_LE,RSA_LE,TCP_LE,ONSTAR_LE,OTIM_LE,IPC_LE,CHUD_LE,HUD_LE,VCU_LE,RadioHead_LE
 SG_ ODII_ODIInd33 : 47|1@0+ (1,0) [0|1] ""  CSM_LE,RSC_LE,RSA_LE,TCP_LE,ONSTAR_LE,OTIM_LE,IPC_LE,CHUD_LE,HUD_LE,VCU_LE,RadioHead_LE
 SG_ ODII_ODIInd32 : 32|1@0+ (1,0) [0|1] ""  CSM_LE,RSC_LE,RSA_LE,TCP_LE,ONSTAR_LE,OTIM_LE,IPC_LE,CHUD_LE,HUD_LE,VCU_LE,RadioHead_LE
 SG_ ODII_ODIInd31 : 33|1@0+ (1,0) [0|1] ""  CSM_LE,RSC_LE,RSA_LE,TCP_LE,ONSTAR_LE,OTIM_LE,IPC_LE,CHUD_LE,HUD_LE,VCU_LE,RadioHead_LE
 SG_ ODII_ODIInd30 : 34|1@0+ (1,0) [0|1] ""  CSM_LE,RSC_LE,RSA_LE,TCP_LE,ONSTAR_LE,OTIM_LE,IPC_LE,CHUD_LE,HUD_LE,VCU_LE,RadioHead_LE
 SG_ ODII_ODIInd29 : 35|1@0+ (1,0) [0|1] ""  CSM_LE,RSC_LE,RSA_LE,TCP_LE,ONSTAR_LE,OTIM_LE,IPC_LE,CHUD_LE,HUD_LE,VCU_LE,RadioHead_LE
 SG_ ODII_ODIInd28 : 36|1@0+ (1,0) [0|1] ""  CSM_LE,RSC_LE,RSA_LE,TCP_LE,ONSTAR_LE,OTIM_LE,IPC_LE,CHUD_LE,HUD_LE,VCU_LE,RadioHead_LE
 SG_ ODII_FUCID : 7|8@0+ (1,0) [0|255] ""  CSM_LE,RSC_LE,RSA_LE,TCP_LE,ONSTAR_LE,OTIM_LE,IPC_LE,CHUD_LE,HUD_LE,VCU_LE,RadioHead_LE

BO_ 2158813184 ODIIndication_IPC_LE: 8 IPC_LE
 SG_ ODIIIPC_ODIInd56 : 56|1@0+ (1,0) [0|1] ""  CSM_LE,TCP_LE,ONSTAR_LE,VCU_LE,RadioHead_LE,CHUD_LE,HUD_LE
 SG_ ODIIIPC_ODIInd55 : 57|1@0+ (1,0) [0|1] ""  CSM_LE,TCP_LE,ONSTAR_LE,VCU_LE,RadioHead_LE,CHUD_LE,HUD_LE
 SG_ ODIIIPC_ODIInd54 : 58|1@0+ (1,0) [0|1] ""  CSM_LE,TCP_LE,ONSTAR_LE,VCU_LE,RadioHead_LE,CHUD_LE,HUD_LE
 SG_ ODIIIPC_ODIInd53 : 59|1@0+ (1,0) [0|1] ""  CSM_LE,TCP_LE,ONSTAR_LE,VCU_LE,RadioHead_LE,CHUD_LE,HUD_LE
 SG_ ODIIIPC_ODIInd52 : 60|1@0+ (1,0) [0|1] ""  CSM_LE,TCP_LE,ONSTAR_LE,VCU_LE,RadioHead_LE,CHUD_LE,HUD_LE
 SG_ ODIIIPC_ODIInd51 : 61|1@0+ (1,0) [0|1] ""  CSM_LE,TCP_LE,ONSTAR_LE,VCU_LE,RadioHead_LE,CHUD_LE,HUD_LE
 SG_ ODIIIPC_ODIInd50 : 62|1@0+ (1,0) [0|1] ""  CSM_LE,TCP_LE,ONSTAR_LE,VCU_LE,RadioHead_LE,CHUD_LE,HUD_LE
 SG_ ODIIIPC_ODIInd49 : 63|1@0+ (1,0) [0|1] ""  CSM_LE,TCP_LE,ONSTAR_LE,VCU_LE,RadioHead_LE,CHUD_LE,HUD_LE
 SG_ ODIIIPC_ODIInd48 : 48|1@0+ (1,0) [0|1] ""  CSM_LE,TCP_LE,ONSTAR_LE,VCU_LE,RadioHead_LE,CHUD_LE,HUD_LE
 SG_ ODIIIPC_ODIInd47 : 49|1@0+ (1,0) [0|1] ""  CSM_LE,TCP_LE,ONSTAR_LE,VCU_LE,RadioHead_LE,CHUD_LE,HUD_LE
 SG_ ODIIIPC_ODIInd46 : 50|1@0+ (1,0) [0|1] ""  CSM_LE,TCP_LE,ONSTAR_LE,VCU_LE,RadioHead_LE,CHUD_LE,HUD_LE
 SG_ ODIIIPC_ODIInd45 : 51|1@0+ (1,0) [0|1] ""  CSM_LE,TCP_LE,ONSTAR_LE,VCU_LE,RadioHead_LE,CHUD_LE,HUD_LE
 SG_ ODIIIPC_ODIInd44 : 52|1@0+ (1,0) [0|1] ""  CSM_LE,TCP_LE,ONSTAR_LE,VCU_LE,RadioHead_LE,CHUD_LE,HUD_LE
 SG_ ODIIIPC_ODIInd43 : 53|1@0+ (1,0) [0|1] ""  CSM_LE,TCP_LE,ONSTAR_LE,VCU_LE,RadioHead_LE,CHUD_LE,HUD_LE
 SG_ ODIIIPC_ODIInd42 : 54|1@0+ (1,0) [0|1] ""  CSM_LE,TCP_LE,ONSTAR_LE,VCU_LE,RadioHead_LE,CHUD_LE,HUD_LE
 SG_ ODIIIPC_ODIInd41 : 55|1@0+ (1,0) [0|1] ""  CSM_LE,TCP_LE,ONSTAR_LE,VCU_LE,RadioHead_LE,CHUD_LE,HUD_LE
 SG_ ODIIIPC_ODIInd40 : 40|1@0+ (1,0) [0|1] ""  CSM_LE,TCP_LE,ONSTAR_LE,VCU_LE,RadioHead_LE,CHUD_LE,HUD_LE
 SG_ ODIIIPC_ODIInd39 : 41|1@0+ (1,0) [0|1] ""  CSM_LE,TCP_LE,ONSTAR_LE,VCU_LE,RadioHead_LE,CHUD_LE,HUD_LE
 SG_ ODIIIPC_ODIInd38 : 42|1@0+ (1,0) [0|1] ""  CSM_LE,TCP_LE,ONSTAR_LE,VCU_LE,RadioHead_LE,CHUD_LE,HUD_LE
 SG_ ODIIIPC_ODIInd9 : 23|1@0+ (1,0) [0|1] ""  CSM_LE,TCP_LE,ONSTAR_LE,VCU_LE,RadioHead_LE,CHUD_LE,HUD_LE
 SG_ ODIIIPC_ODIInd8 : 8|1@0+ (1,0) [0|1] ""  CSM_LE,TCP_LE,ONSTAR_LE,VCU_LE,RadioHead_LE,CHUD_LE,HUD_LE
 SG_ ODIIIPC_ODIInd7 : 9|1@0+ (1,0) [0|1] ""  CSM_LE,TCP_LE,ONSTAR_LE,VCU_LE,RadioHead_LE,CHUD_LE,HUD_LE
 SG_ ODIIIPC_ODIInd6 : 10|1@0+ (1,0) [0|1] ""  CSM_LE,TCP_LE,ONSTAR_LE,VCU_LE,RadioHead_LE,CHUD_LE,HUD_LE
 SG_ ODIIIPC_ODIInd5 : 11|1@0+ (1,0) [0|1] ""  CSM_LE,TCP_LE,ONSTAR_LE,VCU_LE,RadioHead_LE,CHUD_LE,HUD_LE
 SG_ ODIIIPC_ODIInd4 : 12|1@0+ (1,0) [0|1] ""  CSM_LE,TCP_LE,ONSTAR_LE,VCU_LE,RadioHead_LE,CHUD_LE,HUD_LE
 SG_ ODIIIPC_ODIInd3 : 13|1@0+ (1,0) [0|1] ""  CSM_LE,TCP_LE,ONSTAR_LE,VCU_LE,RadioHead_LE,CHUD_LE,HUD_LE
 SG_ ODIIIPC_ODIInd37 : 43|1@0+ (1,0) [0|1] ""  CSM_LE,TCP_LE,ONSTAR_LE,VCU_LE,RadioHead_LE,CHUD_LE,HUD_LE
 SG_ ODIIIPC_ODIInd36 : 44|1@0+ (1,0) [0|1] ""  CSM_LE,TCP_LE,ONSTAR_LE,VCU_LE,RadioHead_LE,CHUD_LE,HUD_LE
 SG_ ODIIIPC_ODIInd35 : 45|1@0+ (1,0) [0|1] ""  CSM_LE,TCP_LE,ONSTAR_LE,VCU_LE,RadioHead_LE,CHUD_LE,HUD_LE
 SG_ ODIIIPC_ODIInd34 : 46|1@0+ (1,0) [0|1] ""  CSM_LE,TCP_LE,ONSTAR_LE,VCU_LE,RadioHead_LE,CHUD_LE,HUD_LE
 SG_ ODIIIPC_ODIInd33 : 47|1@0+ (1,0) [0|1] ""  CSM_LE,TCP_LE,ONSTAR_LE,VCU_LE,RadioHead_LE,CHUD_LE,HUD_LE
 SG_ ODIIIPC_ODIInd32 : 32|1@0+ (1,0) [0|1] ""  CSM_LE,TCP_LE,ONSTAR_LE,VCU_LE,RadioHead_LE,CHUD_LE,HUD_LE
 SG_ ODIIIPC_ODIInd31 : 33|1@0+ (1,0) [0|1] ""  CSM_LE,TCP_LE,ONSTAR_LE,VCU_LE,RadioHead_LE,CHUD_LE,HUD_LE
 SG_ ODIIIPC_ODIInd30 : 34|1@0+ (1,0) [0|1] ""  CSM_LE,TCP_LE,ONSTAR_LE,VCU_LE,RadioHead_LE,CHUD_LE,HUD_LE
 SG_ ODIIIPC_ODIInd29 : 35|1@0+ (1,0) [0|1] ""  CSM_LE,TCP_LE,ONSTAR_LE,VCU_LE,RadioHead_LE,CHUD_LE,HUD_LE
 SG_ ODIIIPC_ODIInd28 : 36|1@0+ (1,0) [0|1] ""  CSM_LE,TCP_LE,ONSTAR_LE,VCU_LE,RadioHead_LE,CHUD_LE,HUD_LE
 SG_ ODIIIPC_ODIInd27 : 37|1@0+ (1,0) [0|1] ""  CSM_LE,TCP_LE,ONSTAR_LE,VCU_LE,RadioHead_LE,CHUD_LE,HUD_LE
 SG_ ODIIIPC_ODIInd26 : 38|1@0+ (1,0) [0|1] ""  CSM_LE,TCP_LE,ONSTAR_LE,VCU_LE,RadioHead_LE,CHUD_LE,HUD_LE
 SG_ ODIIIPC_ODIInd25 : 39|1@0+ (1,0) [0|1] ""  CSM_LE,TCP_LE,ONSTAR_LE,VCU_LE,RadioHead_LE,CHUD_LE,HUD_LE
 SG_ ODIIIPC_ODIInd24 : 24|1@0+ (1,0) [0|1] ""  CSM_LE,TCP_LE,ONSTAR_LE,VCU_LE,RadioHead_LE,CHUD_LE,HUD_LE
 SG_ ODIIIPC_ODIInd23 : 25|1@0+ (1,0) [0|1] ""  CSM_LE,TCP_LE,ONSTAR_LE,VCU_LE,RadioHead_LE,CHUD_LE,HUD_LE
 SG_ ODIIIPC_ODIInd22 : 26|1@0+ (1,0) [0|1] ""  CSM_LE,TCP_LE,ONSTAR_LE,VCU_LE,RadioHead_LE,CHUD_LE,HUD_LE
 SG_ ODIIIPC_ODIInd21 : 27|1@0+ (1,0) [0|1] ""  CSM_LE,TCP_LE,ONSTAR_LE,VCU_LE,RadioHead_LE,CHUD_LE,HUD_LE
 SG_ ODIIIPC_ODIInd20 : 28|1@0+ (1,0) [0|1] ""  CSM_LE,TCP_LE,ONSTAR_LE,VCU_LE,RadioHead_LE,CHUD_LE,HUD_LE
 SG_ ODIIIPC_ODIInd19 : 29|1@0+ (1,0) [0|1] ""  CSM_LE,TCP_LE,ONSTAR_LE,VCU_LE,RadioHead_LE,CHUD_LE,HUD_LE
 SG_ ODIIIPC_ODIInd18 : 30|1@0+ (1,0) [0|1] ""  CSM_LE,TCP_LE,ONSTAR_LE,VCU_LE,RadioHead_LE,CHUD_LE,HUD_LE
 SG_ ODIIIPC_ODIInd17 : 31|1@0+ (1,0) [0|1] ""  CSM_LE,TCP_LE,ONSTAR_LE,VCU_LE,RadioHead_LE,CHUD_LE,HUD_LE
 SG_ ODIIIPC_ODIInd16 : 16|1@0+ (1,0) [0|1] ""  CSM_LE,TCP_LE,ONSTAR_LE,VCU_LE,RadioHead_LE,CHUD_LE,HUD_LE
 SG_ ODIIIPC_ODIInd15 : 17|1@0+ (1,0) [0|1] ""  CSM_LE,TCP_LE,ONSTAR_LE,VCU_LE,RadioHead_LE,CHUD_LE,HUD_LE
 SG_ ODIIIPC_ODIInd14 : 18|1@0+ (1,0) [0|1] ""  CSM_LE,TCP_LE,ONSTAR_LE,VCU_LE,RadioHead_LE,CHUD_LE,HUD_LE
 SG_ ODIIIPC_ODIInd13 : 19|1@0+ (1,0) [0|1] ""  CSM_LE,TCP_LE,ONSTAR_LE,VCU_LE,RadioHead_LE,CHUD_LE,HUD_LE
 SG_ ODIIIPC_ODIInd12 : 20|1@0+ (1,0) [0|1] ""  CSM_LE,TCP_LE,ONSTAR_LE,VCU_LE,RadioHead_LE,CHUD_LE,HUD_LE
 SG_ ODIIIPC_ODIInd11 : 21|1@0+ (1,0) [0|1] ""  CSM_LE,TCP_LE,ONSTAR_LE,VCU_LE,RadioHead_LE,CHUD_LE,HUD_LE
 SG_ ODIIIPC_ODIInd10 : 22|1@0+ (1,0) [0|1] ""  CSM_LE,TCP_LE,ONSTAR_LE,VCU_LE,RadioHead_LE,CHUD_LE,HUD_LE
 SG_ ODIIIPC_ODIInd2 : 14|1@0+ (1,0) [0|1] ""  CSM_LE,TCP_LE,ONSTAR_LE,VCU_LE,RadioHead_LE,CHUD_LE,HUD_LE
 SG_ ODIIIPC_ODIInd1 : 15|1@0+ (1,0) [0|1] ""  CSM_LE,TCP_LE,ONSTAR_LE,VCU_LE,RadioHead_LE,CHUD_LE,HUD_LE
 SG_ ODIIIPC_FUCID : 7|8@0+ (1,0) [0|255] ""  CSM_LE,TCP_LE,ONSTAR_LE,VCU_LE,RadioHead_LE,CHUD_LE,HUD_LE

BO_TX_BU_ 2151825408 : VCU_LE,IPC_LE,CGM_LE;
BO_TX_BU_ 1609 : CGM_LE,OTIM_LE;
BO_TX_BU_ 1577 : CGM_LE,OTIM_LE;
BO_TX_BU_ 1353 : CGM_LE,OTIM_LE;
BO_TX_BU_ 2159239168 : TCP_LE,ONSTAR_LE;
BO_TX_BU_ 2159149056 : TCP_LE,UHP_Low_LE,ONSTAR_LE;
BO_TX_BU_ 2159083520 : TCP_LE,CSM_LE,VCU_LE,RadioHead_LE,UHP_Low_LE,ONSTAR_LE;
BO_TX_BU_ 2150227968 : TCP_LE,UHP_Low_LE,ONSTAR_LE;
BO_TX_BU_ 2150219776 : VCU_LE,RadioHead_LE;
BO_TX_BU_ 1358 : CGM_LE,VKM_LE,RSC_LE;
BO_TX_BU_ 1582 : CGM_LE,VKM_LE,RSC_LE;
BO_TX_BU_ 1614 : CGM_LE,VKM_LE,RSC_LE;
BO_TX_BU_ 2155266048 : RSC_LE,RSA_LE;
BO_TX_BU_ 2154741760 : RSA_LE,RSC_LE;
BO_TX_BU_ 2159132672 : RSC_LE,RSA_LE;
BO_TX_BU_ 2158968832 : RSC_LE,RSA_LE;
BO_TX_BU_ 2158952448 : RSC_LE,RSA_LE;
BO_TX_BU_ 2158944256 : RSC_LE,RSA_LE;
BO_TX_BU_ 1616 : VPM_LE,HUD_LE;
BO_TX_BU_ 1584 : VPM_LE,HUD_LE;
BO_TX_BU_ 1360 : VPM_LE,HUD_LE;
BO_TX_BU_ 2159206400 : CHUD_LE,HUD_LE;
BO_TX_BU_ 2159190016 : CHUD_LE,HUD_LE;
BO_TX_BU_ 2159124480 : CHUD_LE,HUD_LE;
BO_TX_BU_ 2159108096 : CHUD_LE,HUD_LE;
BO_TX_BU_ 2158903296 : CHUD_LE,HUD_LE;
BO_TX_BU_ 2158870528 : CHUD_LE,HUD_LE;
BO_TX_BU_ 2158837760 : CHUD_LE,HUD_LE;
BO_TX_BU_ 2158796800 : TCP_LE,CGM_LE,PDIM_LE,UHP_Low_LE,ONSTAR_LE;
BO_TX_BU_ 2158813184 : VCU_LE,IPC_LE;
CM_ SG_ 2159132672 ODIAR_FUCID "ODI - Primary ID of Functional Unit in FU Database";
CM_ SG_ 2159132672 ODIAR_DspMID "ODI - ID that identifies the display requesting the data.  See detailed requirements in ODI GMLAN Protocol.";
CM_ SG_ 2159132672 ODIAR_ActnVal "ODI-Integer value for Actions with values.
FUDatabase definition of Action includes ActionDataType that defines whether or not Action has a value. 
For Actions without a value, this field is always sent as 0.";
CM_ SG_ 2159132672 ODIAR_ActnID "ODI-ActionId within the FUClass";
CM_ SG_ 2158952448 ODDMR_ReqType "ODI - Type of Request";
CM_ SG_ 2158952448 ODDMR_FUCID "ODI - Primary ID of Functional Unit in FU Database";
CM_ SG_ 2158952448 ODDMR_DispMID "ODI - ID that identifies the display requesting the data.  See detailed requirements in ODI GMLAN Protocol.";
CM_ SG_ 2158952448 ODDMR_DataID2Vld "ODI -DataIDTwo is being requested as a valid ID.";
CM_ SG_ 2158952448 ODDMR_DataID2 "ODI - ID for the second requested data parameter as defined in the FUDatabase";
CM_ SG_ 2158952448 ODDMR_DataID3Vld "ODI -DataIDThree is being requested as a valid ID.";
CM_ SG_ 2158952448 ODDMR_DataID3 "ODI - ID for the third requested data parameter as defined in the FUDatabase";
CM_ SG_ 2158952448 ODDMR_DataID1 "ODI - ID for the first requested data parameter as defined in the FUDatabase";
CM_ SG_ 2158952448 ODDMR_DataID4Vld "ODI -DataIDFour is being requested as a valid ID.";
CM_ SG_ 2158952448 ODDMR_DataID4 "ODI - ID for the fourth requested data parameter as defined in the FUDatabase";
CM_ SG_ 2158952448 ODDMR_DataID5Vld "ODI -DataIDFive is being requested as a valid ID.";
CM_ SG_ 2158952448 ODDMR_DataID5 "ODI - ID for the fifth requested data parameter as defined in the FUDatabase";
CM_ SG_ 2158944256 ODDLR_SubIdReqM "ODI-The number of list entries, starting at the Index, to send";
CM_ SG_ 2158944256 ODDLR_WrpArnd "ODI-Boolean that shall be set to true if the list shall wrap around.";
CM_ SG_ 2158944256 ODDLR_ReqType "ODI - Type of Request";
CM_ SG_ 2158944256 ODDLR_ReqDir "ODI-Boolean that shall be set to true if req down, set to false if set to up";
CM_ SG_ 2158944256 ODDLR_NmEntries "ODI-The number of list entries, starting at the Index, to send";
CM_ SG_ 2158944256 ODDLR_Idx "ODI-The index within the remote FU’s list at which to start sending data";
CM_ SG_ 2158944256 ODDLR_FUCID "ODI - Primary ID of Functional Unit in FU Database";
CM_ SG_ 2158944256 ODDLR_DspMID "ODI - ID that identifies the display requesting the data.  See detailed requirements in ODI GMLAN Protocol.";
CM_ SG_ 2158944256 ODDLR_DataId "ODI-Data Id for the dynamic list";
CM_ SG_ 2158944256 ODDLR_BckgndFlag "ODI-Informs FU as to priority of response.
Applies to all DataIds in the message.
$0=Immediate response required
$1=Background response";
CM_ SG_ 2158903296 ODDMA_ReqType "ODI - Type of Request";
CM_ SG_ 2158903296 ODDMA_FUCID "ODI - Primary ID of Functional Unit in FU Database";
CM_ SG_ 2158903296 ODDMA_DispMID "ODI - ID that identifies the display requesting the data.  See detailed requirements in ODI GMLAN Protocol.";
CM_ SG_ 2158903296 ODDMA_DataID2Vld "ODI -DataIDTwo is being requested as a valid ID.";
CM_ SG_ 2158903296 ODDMA_DataID2 "ODI - ID for the second requested data parameter as defined in the FUDatabase";
CM_ SG_ 2158903296 ODDMA_DataID3Vld "ODI -DataIDThree is being requested as a valid ID.";
CM_ SG_ 2158903296 ODDMA_DataID3 "ODI - ID for the third requested data parameter as defined in the FUDatabase";
CM_ SG_ 2158903296 ODDMA_DataID1 "ODI - ID for the first requested data parameter as defined in the FUDatabase";
CM_ SG_ 2158903296 ODDMA_DataID4Vld "ODI -DataIDFour is being requested as a valid ID.";
CM_ SG_ 2158903296 ODDMA_DataID4 "ODI - ID for the fourth requested data parameter as defined in the FUDatabase";
CM_ SG_ 2158903296 ODDMA_DataID5Vld "ODI -DataIDFive is being requested as a valid ID.";
CM_ SG_ 2158903296 ODDMA_DataID5 "ODI - ID for the fifth requested data parameter as defined in the FUDatabase";
CM_ SG_ 2158870528 ODDLA_SubIdReqM "ODI-The number of list entries, starting at the Index, to send";
CM_ SG_ 2158870528 ODDLA_WrpArnd "ODI-Boolean that shall be set to true if the list shall wrap around.";
CM_ SG_ 2158870528 ODDLA_ReqType "ODI - Type of Request";
CM_ SG_ 2158870528 ODDLA_ReqDir "ODI-Boolean that shall be set to true if req down, set to false if set to up";
CM_ SG_ 2158870528 ODDLA_NmEntries "ODI-The number of list entries, starting at the Index, to send";
CM_ SG_ 2158870528 ODDLA_Idx "ODI-The index within the remote FU’s list at which to start sending data";
CM_ SG_ 2158870528 ODDLA_FUCID "ODI - Primary ID of Functional Unit in FU Database";
CM_ SG_ 2158870528 ODDLA_DspMID "ODI - ID that identifies the display requesting the data.  See detailed requirements in ODI GMLAN Protocol.";
CM_ SG_ 2158870528 ODDLA_DataId "ODI-Data Id for the dynamic list";
CM_ SG_ 2158870528 ODDLA_BckgndFlag "ODI-Informs FU as to priority of response.
Applies to all DataIds in the message.
$0=Immediate response required
$1=Background response";
CM_ BO_ 2158837760 "LAP: Signalerna är inte riktigt kodade!!!        ODI";
CM_ SG_ 2158837760 ODIAA_FUCID "ODI - Primary ID of Functional Unit in FU Database";
CM_ SG_ 2158837760 ODIAA_DspMID "ODI - ID that identifies the display requesting the data.  See detailed requirements in ODI GMLAN Protocol.";
CM_ SG_ 2158837760 ODIAA_ActnVal "ODI-Integer value for Actions with values.
FUDatabase definition of Action includes ActionDataType that defines whether or not Action has a value. 
For Actions without a value, this field is always sent as 0.";
CM_ SG_ 2158837760 ODIAA_ActnID "ODI-ActionId within the FUClass";
CM_ SG_ 2158796800 ODII_FUCID "ODI - Primary ID of Functional Unit in FU Database";
CM_ SG_ 2158813184 ODIIIPC_FUCID "ODI - Primary ID of Functional Unit in FU Database";
BA_DEF_ SG_  "VNSigPrimaryTriggering" ENUM  "No","Yes","DLCLS","DLCHS","DLCCE","DLCFO";
BA_DEF_ SG_  "VNSigRemoteDiagnostics" ENUM  "No","Yes","DLCLS","DLCHS","DLCCE","DLCFO";
BA_DEF_ SG_  "VNSigInfotainment" ENUM  "No","Yes","DLCLS","DLCHS","DLCCE","DLCFO";
BA_DEF_ SG_  "VNSigParkedVehicle" ENUM  "No","Yes","DLCLS","DLCHS","DLCCE","DLCFO";
BA_DEF_ SG_  "VNSigIntermediate" ENUM  "No","Yes","DLCLS","DLCHS","DLCCE","DLCFO";
BA_DEF_ SG_  "VNSigUnused_4" ENUM  "No","Yes","DLCLS","DLCHS","DLCCE","DLCFO";
BA_DEF_ SG_  "SignalType" STRING ;
BA_DEF_ SG_  "PacketOrder" INT 0 65535;
BA_DEF_ SG_  "SignalLongName" STRING ;
BA_DEF_ SG_  "GenSigStartValue" INT 0 65535;
BA_DEF_ SG_  "VNSigDiagnostic" ENUM  "No","Yes","DLCLS","DLCHS","DLCCE","DLCFO";
BA_DEF_ SG_  "VNSigAllNodes" ENUM  "No","Yes","DLCLS","DLCHS","DLCCE","DLCFO";
BA_DEF_ SG_  "GenSigDeltaValue" INT 0 0;
BA_DEF_ SG_  "GenSigSendType" ENUM  "not used","not used","not used","not used","not used","not used","not used","NoSigSendType","not used","not used","OnAnyChange","OnChangeIfActive","OnDelta","DLCLS","DLCHS","DLCCE","DLCFO";
BA_DEF_ SG_  "GenSigSendOnInit" ENUM  "Not Initialized","Application","Handler","DLCLS","DLCHS","DLCCE","DLCFO";
BA_DEF_ BO_  "AppGenMsgCycleTime" INT 0 0;
BA_DEF_ BO_  "TpTxIndex" INT 0 99;
BA_DEF_ BO_  "GenMsgILSupport" ENUM  "No","Yes","DLCLS","DLCHS","DLCCE","DLCFO";
BA_DEF_ BO_  "TpApplType" STRING ;
BA_DEF_ BO_  "Prio" INT 0 7;
BA_DEF_ BO_  "MessageSubnet" ENUM  "LS","MS","HS","CE","PE","HV","FO","S1","HE","LE","HE2","DLCLS","DLCHS","DLCCE","DLCFO";
BA_DEF_ BO_  "GenMsgMandatoryToSupervision" ENUM  "No","Yes","DLCLS","DLCHS","DLCCE","DLCFO";
BA_DEF_ BO_  "DiagState" ENUM  "No","Yes","DLCLS","DLCHS","DLCCE","DLCFO";
BA_DEF_ BO_  "GenMsgStartDelayTime" INT 0 100000;
BA_DEF_ BO_  "GenMsgDelayTime" INT 0 100000;
BA_DEF_ BO_  "GenMsgCycleTime" INT 0 100000;
BA_DEF_ BO_  "GenMsgSendType" ENUM  "cyclicX","spontanX","cyclicIfActiveX","spontanWithDelay","cyclicAndSpontanX","cyclicAndSpontanWithDelay","spontanWithRepitition","cyclicIfActiveAndSpontanWD","DLCLS","DLCHS","DLCCE","DLCFO";
BA_DEF_ BO_  "DiagResponse" ENUM  "No","Yes","DLCLS","DLCHS","DLCCE","DLCFO";
BA_DEF_ BO_  "DiagRequest" ENUM  "No","Yes","DLCLS","DLCHS","DLCCE","DLCFO";
BA_DEF_ BO_  "NmMessage" ENUM  "No","Yes","DLCLS","DLCHS","DLCCE","DLCFO";
BA_DEF_REL_ BU_SG_REL_  "GenSigSuprvRespComment" STRING ;
BA_DEF_REL_ BU_SG_REL_  "GenSigVBitResp" ENUM  "No","Yes","DLCLS","DLCHS","DLCCE","DLCFO";
BA_DEF_REL_ BU_SG_REL_  "GenSigVBitRespComment" STRING ;
BA_DEF_REL_ BU_SG_REL_  "GenSigVDAFailComment" STRING ;
BA_DEF_REL_ BU_SG_REL_  "GenSigVDAFailResp" ENUM  "No","Yes","DLCLS","DLCHS","DLCCE","DLCFO";
BA_DEF_REL_ BU_SG_REL_  "GenSigRxStartValue" STRING ;
BA_DEF_REL_ BU_SG_REL_  "GenSigSuprvRespSubValue" INT 0 65535;
BA_DEF_REL_ BU_SG_REL_  "GenSigSuprvResp" ENUM  "None","Notify App","Substitute Default","DLCLS","DLCHS","DLCCE","DLCFO";
BA_DEF_REL_ BU_SG_REL_  "GenSigTimeoutMsg" HEX -2147483648 268435455;
BA_DEF_DEF_  "VNSigPrimaryTriggering" "No";
BA_DEF_DEF_  "VNSigRemoteDiagnostics" "No";
BA_DEF_DEF_  "VNSigInfotainment" "No";
BA_DEF_DEF_  "VNSigParkedVehicle" "No";
BA_DEF_DEF_  "VNSigIntermediate" "No";
BA_DEF_DEF_  "VNSigUnused_4" "No";
BA_DEF_DEF_  "SignalType" "";
BA_DEF_DEF_  "PacketOrder" 0;
BA_DEF_DEF_  "SignalLongName" "";
BA_DEF_DEF_  "GenSigStartValue" 0;
BA_DEF_DEF_  "VNSigDiagnostic" "No";
BA_DEF_DEF_  "VNSigAllNodes" "No";
BA_DEF_DEF_  "GenSigDeltaValue" 0;
BA_DEF_DEF_  "GenSigSendType" "NoSigSendType";
BA_DEF_DEF_  "GenSigSendOnInit" "Not Initialized";
BA_DEF_DEF_  "AppGenMsgCycleTime" 0;
BA_DEF_DEF_  "TpTxIndex" 0;
BA_DEF_DEF_  "GenMsgILSupport" "Yes";
BA_DEF_DEF_  "TpApplType" "";
BA_DEF_DEF_  "Prio" 4;
BA_DEF_DEF_  "MessageSubnet" "FO";
BA_DEF_DEF_  "GenMsgMandatoryToSupervision" "No";
BA_DEF_DEF_  "DiagState" "No";
BA_DEF_DEF_  "GenMsgStartDelayTime" 0;
BA_DEF_DEF_  "GenMsgDelayTime" 0;
BA_DEF_DEF_  "GenMsgCycleTime" 0;
BA_DEF_DEF_  "GenMsgSendType" "spontanX";
BA_DEF_DEF_  "DiagResponse" "No";
BA_DEF_DEF_  "DiagRequest" "No";
BA_DEF_DEF_  "NmMessage" "No";
BA_DEF_DEF_REL_ "GenSigSuprvRespComment" "";
BA_DEF_DEF_REL_ "GenSigVBitResp" "No";
BA_DEF_DEF_REL_ "GenSigVBitRespComment" "";
BA_DEF_DEF_REL_ "GenSigVDAFailComment" "";
BA_DEF_DEF_REL_ "GenSigVDAFailResp" "No";
BA_DEF_DEF_REL_ "GenSigRxStartValue" "";
BA_DEF_DEF_REL_ "GenSigSuprvRespSubValue" 0;
BA_DEF_DEF_REL_ "GenSigSuprvResp" "None";
BA_DEF_DEF_REL_ "GenSigTimeoutMsg" 0;
BA_ "MessageSubnet" BO_ 2154971136 9;
BA_ "GenMsgDelayTime" BO_ 2154971136 100;
BA_ "MessageSubnet" BO_ 2154962944 9;
BA_ "GenMsgDelayTime" BO_ 2154962944 100;
BA_ "MessageSubnet" BO_ 2151825408 9;
BA_ "GenMsgDelayTime" BO_ 2151825408 100;
BA_ "MessageSubnet" BO_ 2150760448 9;
BA_ "GenMsgDelayTime" BO_ 2150760448 10;
BA_ "GenMsgILSupport" BO_ 1609 0;
BA_ "Prio" BO_ 1609 0;
BA_ "MessageSubnet" BO_ 1609 9;
BA_ "DiagResponse" BO_ 1609 1;
BA_ "Prio" BO_ 1577 0;
BA_ "MessageSubnet" BO_ 1577 9;
BA_ "GenMsgCycleTime" BO_ 1577 3000;
BA_ "GenMsgSendType" BO_ 1577 0;
BA_ "NmMessage" BO_ 1577 1;
BA_ "GenMsgILSupport" BO_ 1353 0;
BA_ "TpApplType" BO_ 1353 "DiagUUDTResponse";
BA_ "Prio" BO_ 1353 0;
BA_ "MessageSubnet" BO_ 1353 9;
BA_ "MessageSubnet" BO_ 2159239168 9;
BA_ "GenMsgDelayTime" BO_ 2159239168 10;
BA_ "MessageSubnet" BO_ 2159230976 9;
BA_ "GenMsgDelayTime" BO_ 2159230976 10;
BA_ "MessageSubnet" BO_ 2159149056 9;
BA_ "GenMsgDelayTime" BO_ 2159149056 10;
BA_ "MessageSubnet" BO_ 2159083520 9;
BA_ "GenMsgDelayTime" BO_ 2159083520 10;
BA_ "MessageSubnet" BO_ 2150227968 9;
BA_ "GenMsgDelayTime" BO_ 2150227968 100;
BA_ "MessageSubnet" BO_ 2150219776 9;
BA_ "GenMsgDelayTime" BO_ 2150219776 10;
BA_ "GenMsgILSupport" BO_ 1358 0;
BA_ "TpApplType" BO_ 1358 "DiagUUDTResponse";
BA_ "Prio" BO_ 1358 0;
BA_ "MessageSubnet" BO_ 1358 9;
BA_ "Prio" BO_ 1582 0;
BA_ "MessageSubnet" BO_ 1582 9;
BA_ "GenMsgCycleTime" BO_ 1582 3000;
BA_ "GenMsgSendType" BO_ 1582 0;
BA_ "NmMessage" BO_ 1582 1;
BA_ "Prio" BO_ 1614 0;
BA_ "MessageSubnet" BO_ 1614 9;
BA_ "DiagResponse" BO_ 1614 1;
BA_ "MessageSubnet" BO_ 2155266048 9;
BA_ "GenMsgDelayTime" BO_ 2155266048 100;
BA_ "MessageSubnet" BO_ 2155249664 9;
BA_ "GenMsgDelayTime" BO_ 2155249664 100;
BA_ "MessageSubnet" BO_ 2154741760 9;
BA_ "GenMsgDelayTime" BO_ 2154741760 100;
BA_ "MessageSubnet" BO_ 2159132672 9;
BA_ "GenMsgDelayTime" BO_ 2159132672 20;
BA_ "MessageSubnet" BO_ 2158968832 9;
BA_ "GenMsgDelayTime" BO_ 2158968832 10;
BA_ "MessageSubnet" BO_ 2158952448 9;
BA_ "GenMsgDelayTime" BO_ 2158952448 20;
BA_ "MessageSubnet" BO_ 2158944256 9;
BA_ "GenMsgDelayTime" BO_ 2158944256 20;
BA_ "Prio" BO_ 1616 0;
BA_ "MessageSubnet" BO_ 1616 9;
BA_ "DiagResponse" BO_ 1616 1;
BA_ "Prio" BO_ 1584 0;
BA_ "MessageSubnet" BO_ 1584 9;
BA_ "GenMsgCycleTime" BO_ 1584 3000;
BA_ "GenMsgSendType" BO_ 1584 0;
BA_ "NmMessage" BO_ 1584 1;
BA_ "GenMsgILSupport" BO_ 1360 0;
BA_ "TpApplType" BO_ 1360 "DiagUUDTResponse";
BA_ "Prio" BO_ 1360 0;
BA_ "MessageSubnet" BO_ 1360 9;
BA_ "MessageSubnet" BO_ 2159206400 9;
BA_ "GenMsgDelayTime" BO_ 2159206400 10;
BA_ "MessageSubnet" BO_ 2159190016 9;
BA_ "GenMsgDelayTime" BO_ 2159190016 10;
BA_ "MessageSubnet" BO_ 2159124480 9;
BA_ "GenMsgDelayTime" BO_ 2159124480 10;
BA_ "MessageSubnet" BO_ 2159108096 9;
BA_ "GenMsgDelayTime" BO_ 2159108096 10;
BA_ "MessageSubnet" BO_ 2158903296 9;
BA_ "GenMsgDelayTime" BO_ 2158903296 20;
BA_ "MessageSubnet" BO_ 2158870528 9;
BA_ "GenMsgDelayTime" BO_ 2158870528 20;
BA_ "MessageSubnet" BO_ 2158837760 9;
BA_ "GenMsgDelayTime" BO_ 2158837760 20;
BA_ "MessageSubnet" BO_ 2158796800 9;
BA_ "GenMsgDelayTime" BO_ 2158796800 100;
BA_ "MessageSubnet" BO_ 2158813184 9;
BA_ "GenMsgDelayTime" BO_ 2158813184 100;
BA_ "GenSigSendType" SG_ 2154971136 PassHCSeatSw3Act 10;
BA_ "GenSigSendOnInit" SG_ 2154971136 PassHCSeatSw3Act 2;
BA_ "SignalType" SG_ 2154971136 PassHCSeatSw3Act "BLN";
BA_ "SignalLongName" SG_ 2154971136 PassHCSeatSw3Act "Passenger Heated/Cooled Seat Switch #3 Active";
BA_ "VNSigAllNodes" SG_ 2154971136 PassHCSeatSw3Act 1;
BA_ "GenSigSendType" SG_ 2154971136 PassHCSeatSw2Act 10;
BA_ "GenSigSendOnInit" SG_ 2154971136 PassHCSeatSw2Act 2;
BA_ "SignalType" SG_ 2154971136 PassHCSeatSw2Act "BLN";
BA_ "SignalLongName" SG_ 2154971136 PassHCSeatSw2Act "Passenger Heated/Cooled Seat Switch #2 Active";
BA_ "VNSigAllNodes" SG_ 2154971136 PassHCSeatSw2Act 1;
BA_ "GenSigSendType" SG_ 2154971136 PassHCSeatSw1Act 10;
BA_ "GenSigSendOnInit" SG_ 2154971136 PassHCSeatSw1Act 2;
BA_ "SignalType" SG_ 2154971136 PassHCSeatSw1Act "BLN";
BA_ "SignalLongName" SG_ 2154971136 PassHCSeatSw1Act "Passenger Heated/Cooled Seat Switch #1 Active";
BA_ "VNSigAllNodes" SG_ 2154971136 PassHCSeatSw1Act 1;
BA_ "GenSigSendType" SG_ 2154971136 DrvHCSeatSw3Act 10;
BA_ "GenSigSendOnInit" SG_ 2154971136 DrvHCSeatSw3Act 2;
BA_ "SignalType" SG_ 2154971136 DrvHCSeatSw3Act "BLN";
BA_ "SignalLongName" SG_ 2154971136 DrvHCSeatSw3Act "Driver Heated/Cooled Seat Switch #3 Active";
BA_ "VNSigAllNodes" SG_ 2154971136 DrvHCSeatSw3Act 1;
BA_ "GenSigSendType" SG_ 2154971136 DrvHCSeatSw2Act 10;
BA_ "GenSigSendOnInit" SG_ 2154971136 DrvHCSeatSw2Act 2;
BA_ "SignalType" SG_ 2154971136 DrvHCSeatSw2Act "BLN";
BA_ "SignalLongName" SG_ 2154971136 DrvHCSeatSw2Act "Driver Heated/Cooled Seat Switch #2 Active";
BA_ "VNSigAllNodes" SG_ 2154971136 DrvHCSeatSw2Act 1;
BA_ "GenSigSendType" SG_ 2154971136 DrvHCSeatSw1Act 10;
BA_ "GenSigSendOnInit" SG_ 2154971136 DrvHCSeatSw1Act 2;
BA_ "SignalType" SG_ 2154971136 DrvHCSeatSw1Act "BLN";
BA_ "SignalLongName" SG_ 2154971136 DrvHCSeatSw1Act "Driver Heated/Cooled Seat Switch #1 Active";
BA_ "VNSigAllNodes" SG_ 2154971136 DrvHCSeatSw1Act 1;
BA_ "GenSigSendType" SG_ 2154962944 PassHCSMInd3 10;
BA_ "GenSigSendOnInit" SG_ 2154962944 PassHCSMInd3 1;
BA_ "SignalType" SG_ 2154962944 PassHCSMInd3 "BLN";
BA_ "PacketOrder" SG_ 2154962944 PassHCSMInd3 4;
BA_ "SignalLongName" SG_ 2154962944 PassHCSMInd3 "Passenger Heated/Cooled Seat Mode Indication Control : Seat Mode Indication 3";
BA_ "VNSigAllNodes" SG_ 2154962944 PassHCSMInd3 1;
BA_ "GenSigSendType" SG_ 2154962944 PassHCSMInd2 10;
BA_ "GenSigSendOnInit" SG_ 2154962944 PassHCSMInd2 1;
BA_ "SignalType" SG_ 2154962944 PassHCSMInd2 "BLN";
BA_ "PacketOrder" SG_ 2154962944 PassHCSMInd2 3;
BA_ "SignalLongName" SG_ 2154962944 PassHCSMInd2 "Passenger Heated/Cooled Seat Mode Indication Control : Seat Mode Indication 2";
BA_ "VNSigAllNodes" SG_ 2154962944 PassHCSMInd2 1;
BA_ "GenSigSendType" SG_ 2154962944 PassHCSMInd1 10;
BA_ "GenSigSendOnInit" SG_ 2154962944 PassHCSMInd1 1;
BA_ "SignalType" SG_ 2154962944 PassHCSMInd1 "BLN";
BA_ "PacketOrder" SG_ 2154962944 PassHCSMInd1 2;
BA_ "SignalLongName" SG_ 2154962944 PassHCSMInd1 "Passenger Heated/Cooled Seat Mode Indication Control : Seat Mode Indication 1";
BA_ "VNSigAllNodes" SG_ 2154962944 PassHCSMInd1 1;
BA_ "GenSigSendType" SG_ 2154962944 PassHCSMIndReq 10;
BA_ "GenSigSendOnInit" SG_ 2154962944 PassHCSMIndReq 1;
BA_ "SignalType" SG_ 2154962944 PassHCSMIndReq "ENM";
BA_ "PacketOrder" SG_ 2154962944 PassHCSMIndReq 1;
BA_ "SignalLongName" SG_ 2154962944 PassHCSMIndReq "Passenger Heated/Cooled Seat Mode Indication Control : Indication Request";
BA_ "VNSigAllNodes" SG_ 2154962944 PassHCSMIndReq 1;
BA_ "GenSigSendType" SG_ 2154962944 PassHCSLSeatLev5 10;
BA_ "GenSigSendOnInit" SG_ 2154962944 PassHCSLSeatLev5 1;
BA_ "SignalType" SG_ 2154962944 PassHCSLSeatLev5 "BLN";
BA_ "PacketOrder" SG_ 2154962944 PassHCSLSeatLev5 6;
BA_ "SignalLongName" SG_ 2154962944 PassHCSLSeatLev5 "Passenger Heated/Cooled Seat Level Indication Control : Seat Level 5";
BA_ "VNSigAllNodes" SG_ 2154962944 PassHCSLSeatLev5 1;
BA_ "GenSigSendType" SG_ 2154962944 PassHCSLSeatLev4 10;
BA_ "GenSigSendOnInit" SG_ 2154962944 PassHCSLSeatLev4 1;
BA_ "SignalType" SG_ 2154962944 PassHCSLSeatLev4 "BLN";
BA_ "PacketOrder" SG_ 2154962944 PassHCSLSeatLev4 5;
BA_ "SignalLongName" SG_ 2154962944 PassHCSLSeatLev4 "Passenger Heated/Cooled Seat Level Indication Control : Seat Level 4";
BA_ "VNSigAllNodes" SG_ 2154962944 PassHCSLSeatLev4 1;
BA_ "GenSigSendType" SG_ 2154962944 PassHCSLSeatLev3 10;
BA_ "GenSigSendOnInit" SG_ 2154962944 PassHCSLSeatLev3 1;
BA_ "SignalType" SG_ 2154962944 PassHCSLSeatLev3 "BLN";
BA_ "PacketOrder" SG_ 2154962944 PassHCSLSeatLev3 4;
BA_ "SignalLongName" SG_ 2154962944 PassHCSLSeatLev3 "Passenger Heated/Cooled Seat Level Indication Control : Seat Level 3";
BA_ "VNSigAllNodes" SG_ 2154962944 PassHCSLSeatLev3 1;
BA_ "GenSigSendType" SG_ 2154962944 PassHCSLSeatLev2 10;
BA_ "GenSigSendOnInit" SG_ 2154962944 PassHCSLSeatLev2 1;
BA_ "SignalType" SG_ 2154962944 PassHCSLSeatLev2 "BLN";
BA_ "PacketOrder" SG_ 2154962944 PassHCSLSeatLev2 3;
BA_ "SignalLongName" SG_ 2154962944 PassHCSLSeatLev2 "Passenger Heated/Cooled Seat Level Indication Control : Seat Level 2";
BA_ "VNSigAllNodes" SG_ 2154962944 PassHCSLSeatLev2 1;
BA_ "GenSigSendType" SG_ 2154962944 PassHCSLSeatLev1 10;
BA_ "GenSigSendOnInit" SG_ 2154962944 PassHCSLSeatLev1 1;
BA_ "SignalType" SG_ 2154962944 PassHCSLSeatLev1 "BLN";
BA_ "PacketOrder" SG_ 2154962944 PassHCSLSeatLev1 2;
BA_ "SignalLongName" SG_ 2154962944 PassHCSLSeatLev1 "Passenger Heated/Cooled Seat Level Indication Control : Seat Level 1";
BA_ "VNSigAllNodes" SG_ 2154962944 PassHCSLSeatLev1 1;
BA_ "GenSigSendType" SG_ 2154962944 PassHCSLIndReq 10;
BA_ "GenSigSendOnInit" SG_ 2154962944 PassHCSLIndReq 1;
BA_ "SignalType" SG_ 2154962944 PassHCSLIndReq "ENM";
BA_ "PacketOrder" SG_ 2154962944 PassHCSLIndReq 1;
BA_ "SignalLongName" SG_ 2154962944 PassHCSLIndReq "Passenger Heated/Cooled Seat Level Indication Control : Indication Request";
BA_ "VNSigAllNodes" SG_ 2154962944 PassHCSLIndReq 1;
BA_ "GenSigSendType" SG_ 2154962944 DrvHCSMInd1 10;
BA_ "GenSigSendOnInit" SG_ 2154962944 DrvHCSMInd1 1;
BA_ "SignalType" SG_ 2154962944 DrvHCSMInd1 "BLN";
BA_ "PacketOrder" SG_ 2154962944 DrvHCSMInd1 2;
BA_ "SignalLongName" SG_ 2154962944 DrvHCSMInd1 "Driver Heated/Cooled Seat Mode Indication Control : Seat Mode Indication 1";
BA_ "VNSigAllNodes" SG_ 2154962944 DrvHCSMInd1 1;
BA_ "GenSigSendType" SG_ 2154962944 DrvHCSMIndReq 10;
BA_ "GenSigSendOnInit" SG_ 2154962944 DrvHCSMIndReq 1;
BA_ "SignalType" SG_ 2154962944 DrvHCSMIndReq "ENM";
BA_ "PacketOrder" SG_ 2154962944 DrvHCSMIndReq 1;
BA_ "SignalLongName" SG_ 2154962944 DrvHCSMIndReq "Driver Heated/Cooled Seat Mode Indication Control : Indication Request";
BA_ "VNSigAllNodes" SG_ 2154962944 DrvHCSMIndReq 1;
BA_ "GenSigSendType" SG_ 2154962944 DrvHCSMInd3 10;
BA_ "GenSigSendOnInit" SG_ 2154962944 DrvHCSMInd3 1;
BA_ "SignalType" SG_ 2154962944 DrvHCSMInd3 "BLN";
BA_ "PacketOrder" SG_ 2154962944 DrvHCSMInd3 4;
BA_ "SignalLongName" SG_ 2154962944 DrvHCSMInd3 "Driver Heated/Cooled Seat Mode Indication Control : Seat Mode Indication 3";
BA_ "VNSigAllNodes" SG_ 2154962944 DrvHCSMInd3 1;
BA_ "GenSigSendType" SG_ 2154962944 DrvHCSMInd2 10;
BA_ "GenSigSendOnInit" SG_ 2154962944 DrvHCSMInd2 1;
BA_ "SignalType" SG_ 2154962944 DrvHCSMInd2 "BLN";
BA_ "PacketOrder" SG_ 2154962944 DrvHCSMInd2 3;
BA_ "SignalLongName" SG_ 2154962944 DrvHCSMInd2 "Driver Heated/Cooled Seat Mode Indication Control : Seat Mode Indication 2";
BA_ "VNSigAllNodes" SG_ 2154962944 DrvHCSMInd2 1;
BA_ "GenSigSendType" SG_ 2154962944 DrvHCSLSeatLev5 10;
BA_ "GenSigSendOnInit" SG_ 2154962944 DrvHCSLSeatLev5 1;
BA_ "SignalType" SG_ 2154962944 DrvHCSLSeatLev5 "BLN";
BA_ "PacketOrder" SG_ 2154962944 DrvHCSLSeatLev5 6;
BA_ "SignalLongName" SG_ 2154962944 DrvHCSLSeatLev5 "Driver Heated/Cooled Seat Level Indication Control : Seat Level 5";
BA_ "VNSigAllNodes" SG_ 2154962944 DrvHCSLSeatLev5 1;
BA_ "GenSigSendType" SG_ 2154962944 DrvHCSLSeatLev4 10;
BA_ "GenSigSendOnInit" SG_ 2154962944 DrvHCSLSeatLev4 1;
BA_ "SignalType" SG_ 2154962944 DrvHCSLSeatLev4 "BLN";
BA_ "PacketOrder" SG_ 2154962944 DrvHCSLSeatLev4 5;
BA_ "SignalLongName" SG_ 2154962944 DrvHCSLSeatLev4 "Driver Heated/Cooled Seat Level Indication Control : Seat Level 4";
BA_ "VNSigAllNodes" SG_ 2154962944 DrvHCSLSeatLev4 1;
BA_ "GenSigSendType" SG_ 2154962944 DrvHCSLSeatLev3 10;
BA_ "GenSigSendOnInit" SG_ 2154962944 DrvHCSLSeatLev3 1;
BA_ "SignalType" SG_ 2154962944 DrvHCSLSeatLev3 "BLN";
BA_ "PacketOrder" SG_ 2154962944 DrvHCSLSeatLev3 4;
BA_ "SignalLongName" SG_ 2154962944 DrvHCSLSeatLev3 "Driver Heated/Cooled Seat Level Indication Control : Seat Level 3";
BA_ "VNSigAllNodes" SG_ 2154962944 DrvHCSLSeatLev3 1;
BA_ "GenSigSendType" SG_ 2154962944 DrvHCSLSeatLev2 10;
BA_ "GenSigSendOnInit" SG_ 2154962944 DrvHCSLSeatLev2 1;
BA_ "SignalType" SG_ 2154962944 DrvHCSLSeatLev2 "BLN";
BA_ "PacketOrder" SG_ 2154962944 DrvHCSLSeatLev2 3;
BA_ "SignalLongName" SG_ 2154962944 DrvHCSLSeatLev2 "Driver Heated/Cooled Seat Level Indication Control : Seat Level 2";
BA_ "VNSigAllNodes" SG_ 2154962944 DrvHCSLSeatLev2 1;
BA_ "GenSigSendType" SG_ 2154962944 DrvHCSLSeatLev1 10;
BA_ "GenSigSendOnInit" SG_ 2154962944 DrvHCSLSeatLev1 1;
BA_ "SignalType" SG_ 2154962944 DrvHCSLSeatLev1 "BLN";
BA_ "PacketOrder" SG_ 2154962944 DrvHCSLSeatLev1 2;
BA_ "SignalLongName" SG_ 2154962944 DrvHCSLSeatLev1 "Driver Heated/Cooled Seat Level Indication Control : Seat Level 1";
BA_ "VNSigAllNodes" SG_ 2154962944 DrvHCSLSeatLev1 1;
BA_ "GenSigSendType" SG_ 2154962944 DrvHCSLIndReq 10;
BA_ "GenSigSendOnInit" SG_ 2154962944 DrvHCSLIndReq 1;
BA_ "SignalType" SG_ 2154962944 DrvHCSLIndReq "ENM";
BA_ "PacketOrder" SG_ 2154962944 DrvHCSLIndReq 1;
BA_ "SignalLongName" SG_ 2154962944 DrvHCSLIndReq "Driver Heated/Cooled Seat Level Indication Control : Indication Request";
BA_ "VNSigAllNodes" SG_ 2154962944 DrvHCSLIndReq 1;
BA_ "GenSigSendType" SG_ 2151825408 OtsAirTmpV 10;
BA_ "SignalType" SG_ 2151825408 OtsAirTmpV "ENM";
BA_ "SignalLongName" SG_ 2151825408 OtsAirTmpV "Outside Air Temperature Validity";
BA_ "VNSigAllNodes" SG_ 2151825408 OtsAirTmpV 1;
BA_ "GenSigDeltaValue" SG_ 2151825408 OtsAirTmp 1;
BA_ "GenSigSendType" SG_ 2151825408 OtsAirTmp 12;
BA_ "GenSigSendOnInit" SG_ 2151825408 OtsAirTmp 1;
BA_ "SignalType" SG_ 2151825408 OtsAirTmp "UNM";
BA_ "SignalLongName" SG_ 2151825408 OtsAirTmp "Outside Air Temperature";
BA_ "VNSigAllNodes" SG_ 2151825408 OtsAirTmp 1;
BA_ "GenSigSendType" SG_ 2151825408 OtsAirTmpCrValV 10;
BA_ "VNSigInfotainment" SG_ 2151825408 OtsAirTmpCrValV 1;
BA_ "SignalType" SG_ 2151825408 OtsAirTmpCrValV "ENM";
BA_ "SignalLongName" SG_ 2151825408 OtsAirTmpCrValV "Outside Air Temperature Corrected Value Validity";
BA_ "VNSigAllNodes" SG_ 2151825408 OtsAirTmpCrValV 1;
BA_ "GenSigDeltaValue" SG_ 2151825408 OtsAirTmpCrVal 1;
BA_ "GenSigSendType" SG_ 2151825408 OtsAirTmpCrVal 12;
BA_ "GenSigSendOnInit" SG_ 2151825408 OtsAirTmpCrVal 1;
BA_ "VNSigInfotainment" SG_ 2151825408 OtsAirTmpCrVal 1;
BA_ "SignalType" SG_ 2151825408 OtsAirTmpCrVal "UNM";
BA_ "SignalLongName" SG_ 2151825408 OtsAirTmpCrVal "Outside Air Temperature Corrected Value";
BA_ "VNSigAllNodes" SG_ 2151825408 OtsAirTmpCrVal 1;
BA_ "GenSigSendType" SG_ 2151825408 OtsAirTmpCrValMsk 10;
BA_ "SignalType" SG_ 2151825408 OtsAirTmpCrValMsk "ENM";
BA_ "SignalLongName" SG_ 2151825408 OtsAirTmpCrValMsk "Outside Air Temperature Corrected Value Mask";
BA_ "VNSigAllNodes" SG_ 2151825408 OtsAirTmpCrValMsk 1;
BA_ "GenSigSendType" SG_ 2150760448 NotSndRwRtSeatStat 10;
BA_ "SignalType" SG_ 2150760448 NotSndRwRtSeatStat "ENM";
BA_ "SignalLongName" SG_ 2150760448 NotSndRwRtSeatStat "Notification Second Row Right Seatbelt Status";
BA_ "VNSigAllNodes" SG_ 2150760448 NotSndRwRtSeatStat 1;
BA_ "GenSigSendType" SG_ 2150760448 NotSndRwMdlSeatStat 10;
BA_ "SignalType" SG_ 2150760448 NotSndRwMdlSeatStat "ENM";
BA_ "SignalLongName" SG_ 2150760448 NotSndRwMdlSeatStat "Notification Second Row Middle Seatbelt Status";
BA_ "VNSigAllNodes" SG_ 2150760448 NotSndRwMdlSeatStat 1;
BA_ "GenSigSendType" SG_ 2150760448 NotSndRwLtSeatStat 10;
BA_ "SignalType" SG_ 2150760448 NotSndRwLtSeatStat "ENM";
BA_ "SignalLongName" SG_ 2150760448 NotSndRwLtSeatStat "Notification Second Row Left Seatbelt Status";
BA_ "VNSigAllNodes" SG_ 2150760448 NotSndRwLtSeatStat 1;
BA_ "GenSigSendType" SG_ 2150760448 NotPsSeatStat 10;
BA_ "SignalType" SG_ 2150760448 NotPsSeatStat "ENM";
BA_ "SignalLongName" SG_ 2150760448 NotPsSeatStat "Notification Passenger Seatbelt Status";
BA_ "VNSigAllNodes" SG_ 2150760448 NotPsSeatStat 1;
BA_ "GenSigSendType" SG_ 2150760448 NotDrvSeatStat 10;
BA_ "SignalType" SG_ 2150760448 NotDrvSeatStat "ENM";
BA_ "SignalLongName" SG_ 2150760448 NotDrvSeatStat "Notification Driver Seatbelt Status";
BA_ "VNSigAllNodes" SG_ 2150760448 NotDrvSeatStat 1;
BA_ "GenSigSendType" SG_ 2150760448 NotSecRowRtSeaOccStat 10;
BA_ "VNSigPrimaryTriggering" SG_ 2150760448 NotSecRowRtSeaOccStat 1;
BA_ "SignalType" SG_ 2150760448 NotSecRowRtSeaOccStat "ENM";
BA_ "SignalLongName" SG_ 2150760448 NotSecRowRtSeaOccStat "Notification Second Row Right Seat Occupancy Status";
BA_ "VNSigAllNodes" SG_ 2150760448 NotSecRowRtSeaOccStat 1;
BA_ "GenSigSendType" SG_ 2150760448 NotSecRowLeSeaOccStat 10;
BA_ "VNSigPrimaryTriggering" SG_ 2150760448 NotSecRowLeSeaOccStat 1;
BA_ "SignalType" SG_ 2150760448 NotSecRowLeSeaOccStat "ENM";
BA_ "SignalLongName" SG_ 2150760448 NotSecRowLeSeaOccStat "Notification Second Row Left Seat Occupancy Status";
BA_ "VNSigAllNodes" SG_ 2150760448 NotSecRowLeSeaOccStat 1;
BA_ "GenSigSendType" SG_ 2150760448 NotSecRowCtSeaOccStat 10;
BA_ "VNSigPrimaryTriggering" SG_ 2150760448 NotSecRowCtSeaOccStat 1;
BA_ "SignalType" SG_ 2150760448 NotSecRowCtSeaOccStat "ENM";
BA_ "SignalLongName" SG_ 2150760448 NotSecRowCtSeaOccStat "Notification Second Row Center Seat Occupancy Status";
BA_ "VNSigAllNodes" SG_ 2150760448 NotSecRowCtSeaOccStat 1;
BA_ "GenSigSendType" SG_ 2150760448 NotiFrntPasSeatOccSta 10;
BA_ "VNSigPrimaryTriggering" SG_ 2150760448 NotiFrntPasSeatOccSta 1;
BA_ "SignalType" SG_ 2150760448 NotiFrntPasSeatOccSta "ENM";
BA_ "SignalLongName" SG_ 2150760448 NotiFrntPasSeatOccSta "Notification Front Passenger Seat Occupancy Status";
BA_ "VNSigAllNodes" SG_ 2150760448 NotiFrntPasSeatOccSta 1;
BA_ "GenSigSendType" SG_ 2150760448 NotEventStat 10;
BA_ "VNSigPrimaryTriggering" SG_ 2150760448 NotEventStat 1;
BA_ "SignalType" SG_ 2150760448 NotEventStat "ENM";
BA_ "SignalLongName" SG_ 2150760448 NotEventStat "Notification Event Status";
BA_ "VNSigAllNodes" SG_ 2150760448 NotEventStat 1;
BA_ "GenSigDeltaValue" SG_ 2150760448 NotiEventCount 1;
BA_ "GenSigSendType" SG_ 2150760448 NotiEventCount 12;
BA_ "VNSigPrimaryTriggering" SG_ 2150760448 NotiEventCount 1;
BA_ "SignalType" SG_ 2150760448 NotiEventCount "UNM";
BA_ "SignalLongName" SG_ 2150760448 NotiEventCount "Notification Event Counter";
BA_ "VNSigAllNodes" SG_ 2150760448 NotiEventCount 1;
BA_ "GenSigSendType" SG_ 2150760448 NESSRoSevSt 10;
BA_ "VNSigPrimaryTriggering" SG_ 2150760448 NESSRoSevSt 1;
BA_ "SignalType" SG_ 2150760448 NESSRoSevSt "BLN";
BA_ "PacketOrder" SG_ 2150760448 NESSRoSevSt 7;
BA_ "SignalLongName" SG_ 2150760448 NESSRoSevSt "Notification Event Severity Status : Rollover Severity Achieved";
BA_ "VNSigAllNodes" SG_ 2150760448 NESSRoSevSt 1;
BA_ "GenSigSendType" SG_ 2150760448 NESSRiSiSevSt 10;
BA_ "VNSigPrimaryTriggering" SG_ 2150760448 NESSRiSiSevSt 1;
BA_ "SignalType" SG_ 2150760448 NESSRiSiSevSt "BLN";
BA_ "PacketOrder" SG_ 2150760448 NESSRiSiSevSt 6;
BA_ "SignalLongName" SG_ 2150760448 NESSRiSiSevSt "Notification Event Severity Status : Right Side Severity Achieved";
BA_ "VNSigAllNodes" SG_ 2150760448 NESSRiSiSevSt 1;
BA_ "GenSigSendType" SG_ 2150760448 NESSReImpSevSt 10;
BA_ "VNSigPrimaryTriggering" SG_ 2150760448 NESSReImpSevSt 1;
BA_ "SignalType" SG_ 2150760448 NESSReImpSevSt "BLN";
BA_ "PacketOrder" SG_ 2150760448 NESSReImpSevSt 5;
BA_ "SignalLongName" SG_ 2150760448 NESSReImpSevSt "Notification Event Severity Status : Rear Impact Severity Achieved";
BA_ "VNSigAllNodes" SG_ 2150760448 NESSReImpSevSt 1;
BA_ "GenSigSendType" SG_ 2150760448 NESSLeSiSevSt 10;
BA_ "VNSigPrimaryTriggering" SG_ 2150760448 NESSLeSiSevSt 1;
BA_ "SignalType" SG_ 2150760448 NESSLeSiSevSt "BLN";
BA_ "PacketOrder" SG_ 2150760448 NESSLeSiSevSt 4;
BA_ "SignalLongName" SG_ 2150760448 NESSLeSiSevSt "Notification Event Severity Status : Left Side Severity Achieved";
BA_ "VNSigAllNodes" SG_ 2150760448 NESSLeSiSevSt 1;
BA_ "GenSigSendType" SG_ 2150760448 NESSFrImpSt2SevSt 10;
BA_ "VNSigPrimaryTriggering" SG_ 2150760448 NESSFrImpSt2SevSt 1;
BA_ "SignalType" SG_ 2150760448 NESSFrImpSt2SevSt "BLN";
BA_ "PacketOrder" SG_ 2150760448 NESSFrImpSt2SevSt 3;
BA_ "SignalLongName" SG_ 2150760448 NESSFrImpSt2SevSt "Notification Event Severity Status : Frontal Impact Stage 2 Severity Achieved";
BA_ "VNSigAllNodes" SG_ 2150760448 NESSFrImpSt2SevSt 1;
BA_ "GenSigSendType" SG_ 2150760448 NESSFrImpSt1SevSt 10;
BA_ "VNSigPrimaryTriggering" SG_ 2150760448 NESSFrImpSt1SevSt 1;
BA_ "SignalType" SG_ 2150760448 NESSFrImpSt1SevSt "BLN";
BA_ "PacketOrder" SG_ 2150760448 NESSFrImpSt1SevSt 2;
BA_ "SignalLongName" SG_ 2150760448 NESSFrImpSt1SevSt "Notification Event Severity Status : Frontal Impact Stage 1 Severity Achieved";
BA_ "VNSigAllNodes" SG_ 2150760448 NESSFrImpSt1SevSt 1;
BA_ "GenSigSendType" SG_ 2150760448 NESSFrImpPreSevSt 10;
BA_ "VNSigPrimaryTriggering" SG_ 2150760448 NESSFrImpPreSevSt 1;
BA_ "SignalType" SG_ 2150760448 NESSFrImpPreSevSt "BLN";
BA_ "PacketOrder" SG_ 2150760448 NESSFrImpPreSevSt 1;
BA_ "SignalLongName" SG_ 2150760448 NESSFrImpPreSevSt "Notification Event Severity Status : Frontal Impact Pretensioner Severity Achieved";
BA_ "VNSigAllNodes" SG_ 2150760448 NESSFrImpPreSevSt 1;
BA_ "GenSigSendType" SG_ 2150760448 NEDLSRtSdArbgDld 10;
BA_ "VNSigPrimaryTriggering" SG_ 2150760448 NEDLSRtSdArbgDld 1;
BA_ "SignalType" SG_ 2150760448 NEDLSRtSdArbgDld "BLN";
BA_ "PacketOrder" SG_ 2150760448 NEDLSRtSdArbgDld 6;
BA_ "SignalLongName" SG_ 2150760448 NEDLSRtSdArbgDld "Notification Event Deployed Loop Status : Right Side Airbag Deployed";
BA_ "VNSigAllNodes" SG_ 2150760448 NEDLSRtSdArbgDld 1;
BA_ "GenSigSendType" SG_ 2150760448 NEDLSLtSdArbgDld 10;
BA_ "VNSigPrimaryTriggering" SG_ 2150760448 NEDLSLtSdArbgDld 1;
BA_ "SignalType" SG_ 2150760448 NEDLSLtSdArbgDld "BLN";
BA_ "PacketOrder" SG_ 2150760448 NEDLSLtSdArbgDld 5;
BA_ "SignalLongName" SG_ 2150760448 NEDLSLtSdArbgDld "Notification Event Deployed Loop Status : Left Side Airbag Deployed";
BA_ "VNSigAllNodes" SG_ 2150760448 NEDLSLtSdArbgDld 1;
BA_ "GenSigSendType" SG_ 2150760448 NEDLSSdCrtnArbgDpld 10;
BA_ "VNSigPrimaryTriggering" SG_ 2150760448 NEDLSSdCrtnArbgDpld 1;
BA_ "SignalType" SG_ 2150760448 NEDLSSdCrtnArbgDpld "BLN";
BA_ "PacketOrder" SG_ 2150760448 NEDLSSdCrtnArbgDpld 7;
BA_ "SignalLongName" SG_ 2150760448 NEDLSSdCrtnArbgDpld "Notification Event Deployed Loop Status : Side Curtain Airbag Deployed";
BA_ "VNSigAllNodes" SG_ 2150760448 NEDLSSdCrtnArbgDpld 1;
BA_ "GenSigSendType" SG_ 2150760448 NEDLSPaFrSt2De 10;
BA_ "VNSigPrimaryTriggering" SG_ 2150760448 NEDLSPaFrSt2De 1;
BA_ "SignalType" SG_ 2150760448 NEDLSPaFrSt2De "BLN";
BA_ "PacketOrder" SG_ 2150760448 NEDLSPaFrSt2De 4;
BA_ "SignalLongName" SG_ 2150760448 NEDLSPaFrSt2De "Notification Event Deployed Loop Status : Passenger Front Stage 2 Deployed";
BA_ "VNSigAllNodes" SG_ 2150760448 NEDLSPaFrSt2De 1;
BA_ "GenSigSendType" SG_ 2150760448 NEDLSPaFrSt1De 10;
BA_ "VNSigPrimaryTriggering" SG_ 2150760448 NEDLSPaFrSt1De 1;
BA_ "SignalType" SG_ 2150760448 NEDLSPaFrSt1De "BLN";
BA_ "PacketOrder" SG_ 2150760448 NEDLSPaFrSt1De 3;
BA_ "SignalLongName" SG_ 2150760448 NEDLSPaFrSt1De "Notification Event Deployed Loop Status : Passenger Front Stage 1 Deployed";
BA_ "VNSigAllNodes" SG_ 2150760448 NEDLSPaFrSt1De 1;
BA_ "GenSigSendType" SG_ 2150760448 NEDLSDrFrSt2De 10;
BA_ "VNSigPrimaryTriggering" SG_ 2150760448 NEDLSDrFrSt2De 1;
BA_ "SignalType" SG_ 2150760448 NEDLSDrFrSt2De "BLN";
BA_ "PacketOrder" SG_ 2150760448 NEDLSDrFrSt2De 2;
BA_ "SignalLongName" SG_ 2150760448 NEDLSDrFrSt2De "Notification Event Deployed Loop Status : Driver Front Stage 2 Deployed";
BA_ "VNSigAllNodes" SG_ 2150760448 NEDLSDrFrSt2De 1;
BA_ "GenSigSendType" SG_ 2150760448 NEDLSDrFrSt1De 10;
BA_ "VNSigPrimaryTriggering" SG_ 2150760448 NEDLSDrFrSt1De 1;
BA_ "SignalType" SG_ 2150760448 NEDLSDrFrSt1De "BLN";
BA_ "PacketOrder" SG_ 2150760448 NEDLSDrFrSt1De 1;
BA_ "SignalLongName" SG_ 2150760448 NEDLSDrFrSt1De "Notification Event Deployed Loop Status : Driver Front Stage 1 Deployed";
BA_ "VNSigAllNodes" SG_ 2150760448 NEDLSDrFrSt1De 1;
BA_ "GenSigSendType" SG_ 2150760448 SIRDpl 10;
BA_ "GenSigSendOnInit" SG_ 2150760448 SIRDpl 2;
BA_ "VNSigPrimaryTriggering" SG_ 2150760448 SIRDpl 1;
BA_ "SignalType" SG_ 2150760448 SIRDpl "BLN";
BA_ "SignalLongName" SG_ 2150760448 SIRDpl "Airbag Deployed";
BA_ "VNSigAllNodes" SG_ 2150760448 SIRDpl 1;
BA_ "SignalType" SG_ 1609 DgnInf "UNM";
BA_ "SignalLongName" SG_ 1609 DgnInf "Diagnostic Information";
BA_ "VNSigDiagnostic" SG_ 1609 DgnInf 1;
BA_ "VNSigAllNodes" SG_ 1609 DgnInf 1;
BA_ "VNSigPrimaryTriggering" SG_ 1577 VectraSpcNWMgtD 1;
BA_ "VNSigRemoteDiagnostics" SG_ 1577 VectraSpcNWMgtD 1;
BA_ "VNSigInfotainment" SG_ 1577 VectraSpcNWMgtD 1;
BA_ "VNSigParkedVehicle" SG_ 1577 VectraSpcNWMgtD 1;
BA_ "VNSigIntermediate" SG_ 1577 VectraSpcNWMgtD 1;
BA_ "VNSigUnused_4" SG_ 1577 VectraSpcNWMgtD 1;
BA_ "SignalType" SG_ 1577 VectraSpcNWMgtD "UNM";
BA_ "SignalLongName" SG_ 1577 VectraSpcNWMgtD "Vectra Specific Network Management Data";
BA_ "VNSigDiagnostic" SG_ 1577 VectraSpcNWMgtD 1;
BA_ "VNSigAllNodes" SG_ 1577 VectraSpcNWMgtD 1;
BA_ "GenSigDeltaValue" SG_ 1353 DgnInf_LS549 1;
BA_ "GenSigSendType" SG_ 1353 DgnInf_LS549 12;
BA_ "SignalType" SG_ 1353 DgnInf_LS549 "UNM";
BA_ "SignalLongName" SG_ 1353 DgnInf_LS549 "Diagnostic Information LS549";
BA_ "VNSigDiagnostic" SG_ 1353 DgnInf_LS549 1;
BA_ "VNSigAllNodes" SG_ 1353 DgnInf_LS549 1;
BA_ "GenSigDeltaValue" SG_ 2159239168 ODI_TEL2OTIM 1;
BA_ "GenSigSendType" SG_ 2159239168 ODI_TEL2OTIM 12;
BA_ "VNSigInfotainment" SG_ 2159239168 ODI_TEL2OTIM 1;
BA_ "SignalType" SG_ 2159239168 ODI_TEL2OTIM "UNM";
BA_ "SignalLongName" SG_ 2159239168 ODI_TEL2OTIM "Open Display Interface TEL 2 OTIM";
BA_ "VNSigAllNodes" SG_ 2159239168 ODI_TEL2OTIM 1;
BA_ "GenSigDeltaValue" SG_ 2159230976 ODI_OTIM2TEL 1;
BA_ "GenSigSendType" SG_ 2159230976 ODI_OTIM2TEL 12;
BA_ "VNSigInfotainment" SG_ 2159230976 ODI_OTIM2TEL 1;
BA_ "SignalType" SG_ 2159230976 ODI_OTIM2TEL "UNM";
BA_ "SignalLongName" SG_ 2159230976 ODI_OTIM2TEL "Open Display Interface OTIM 2 TEL";
BA_ "VNSigAllNodes" SG_ 2159230976 ODI_OTIM2TEL 1;
BA_ "GenSigDeltaValue" SG_ 2159149056 ODI_TEL2CntrStck 1;
BA_ "GenSigSendType" SG_ 2159149056 ODI_TEL2CntrStck 12;
BA_ "VNSigInfotainment" SG_ 2159149056 ODI_TEL2CntrStck 1;
BA_ "SignalType" SG_ 2159149056 ODI_TEL2CntrStck "UNM";
BA_ "SignalLongName" SG_ 2159149056 ODI_TEL2CntrStck "Open Display Interface TEL 2 CenterStack";
BA_ "VNSigAllNodes" SG_ 2159149056 ODI_TEL2CntrStck 1;
BA_ "GenSigDeltaValue" SG_ 2159083520 ODI_TEL2IPC 1;
BA_ "GenSigSendType" SG_ 2159083520 ODI_TEL2IPC 12;
BA_ "VNSigInfotainment" SG_ 2159083520 ODI_TEL2IPC 1;
BA_ "SignalType" SG_ 2159083520 ODI_TEL2IPC "UNM";
BA_ "SignalLongName" SG_ 2159083520 ODI_TEL2IPC "Open Display Interface TEL 2 IPC";
BA_ "VNSigAllNodes" SG_ 2159083520 ODI_TEL2IPC 1;
BA_ "GenSigSendType" SG_ 2150227968 PhnSpRcgnApSt 10;
BA_ "GenSigSendOnInit" SG_ 2150227968 PhnSpRcgnApSt 2;
BA_ "VNSigInfotainment" SG_ 2150227968 PhnSpRcgnApSt 1;
BA_ "SignalType" SG_ 2150227968 PhnSpRcgnApSt "ENM";
BA_ "SignalLongName" SG_ 2150227968 PhnSpRcgnApSt "Phone Speech Recognition/Audio Prompt Status";
BA_ "VNSigAllNodes" SG_ 2150227968 PhnSpRcgnApSt 1;
BA_ "GenSigSendType" SG_ 2150219776 PhnSpRcgnRq 10;
BA_ "VNSigInfotainment" SG_ 2150219776 PhnSpRcgnRq 1;
BA_ "SignalType" SG_ 2150219776 PhnSpRcgnRq "ENM";
BA_ "SignalLongName" SG_ 2150219776 PhnSpRcgnRq "Phone Speech Recognition Request";
BA_ "VNSigAllNodes" SG_ 2150219776 PhnSpRcgnRq 1;
BA_ "GenSigSendType" SG_ 2150219776 VcRecVcFdbckSt 10;
BA_ "GenSigSendOnInit" SG_ 2150219776 VcRecVcFdbckSt 1;
BA_ "VNSigInfotainment" SG_ 2150219776 VcRecVcFdbckSt 1;
BA_ "SignalType" SG_ 2150219776 VcRecVcFdbckSt "ENM";
BA_ "SignalLongName" SG_ 2150219776 VcRecVcFdbckSt "Voice Recognition Voice Feedback Status";
BA_ "VNSigAllNodes" SG_ 2150219776 VcRecVcFdbckSt 1;
BA_ "GenSigDeltaValue" SG_ 1358 DgnInf_LS54E 1;
BA_ "GenSigSendType" SG_ 1358 DgnInf_LS54E 12;
BA_ "SignalType" SG_ 1358 DgnInf_LS54E "UNM";
BA_ "SignalLongName" SG_ 1358 DgnInf_LS54E "Diagnostic Information LS54E";
BA_ "VNSigDiagnostic" SG_ 1358 DgnInf_LS54E 1;
BA_ "VNSigAllNodes" SG_ 1358 DgnInf_LS54E 1;
BA_ "VNSigPrimaryTriggering" SG_ 1582 VectraSpcNWMgtD 1;
BA_ "VNSigRemoteDiagnostics" SG_ 1582 VectraSpcNWMgtD 1;
BA_ "VNSigInfotainment" SG_ 1582 VectraSpcNWMgtD 1;
BA_ "VNSigParkedVehicle" SG_ 1582 VectraSpcNWMgtD 1;
BA_ "VNSigIntermediate" SG_ 1582 VectraSpcNWMgtD 1;
BA_ "VNSigUnused_4" SG_ 1582 VectraSpcNWMgtD 1;
BA_ "SignalType" SG_ 1582 VectraSpcNWMgtD "UNM";
BA_ "SignalLongName" SG_ 1582 VectraSpcNWMgtD "Vectra Specific Network Management Data";
BA_ "VNSigDiagnostic" SG_ 1582 VectraSpcNWMgtD 1;
BA_ "VNSigAllNodes" SG_ 1582 VectraSpcNWMgtD 1;
BA_ "SignalType" SG_ 1614 DgnInf "UNM";
BA_ "SignalLongName" SG_ 1614 DgnInf "Diagnostic Information";
BA_ "VNSigDiagnostic" SG_ 1614 DgnInf 1;
BA_ "VNSigAllNodes" SG_ 1614 DgnInf 1;
BA_ "GenSigSendType" SG_ 2155266048 RRHCSeatSw3Act 10;
BA_ "GenSigSendOnInit" SG_ 2155266048 RRHCSeatSw3Act 2;
BA_ "SignalType" SG_ 2155266048 RRHCSeatSw3Act "BLN";
BA_ "SignalLongName" SG_ 2155266048 RRHCSeatSw3Act "Rear Right Heated/Cooled Seat Switch #3 Active";
BA_ "VNSigAllNodes" SG_ 2155266048 RRHCSeatSw3Act 1;
BA_ "GenSigSendType" SG_ 2155266048 RRHCSeatSw2Act 10;
BA_ "GenSigSendOnInit" SG_ 2155266048 RRHCSeatSw2Act 2;
BA_ "SignalType" SG_ 2155266048 RRHCSeatSw2Act "BLN";
BA_ "SignalLongName" SG_ 2155266048 RRHCSeatSw2Act "Rear Right Heated/Cooled Seat Switch #2 Active";
BA_ "VNSigAllNodes" SG_ 2155266048 RRHCSeatSw2Act 1;
BA_ "GenSigSendType" SG_ 2155266048 RRHCSeatSw1Act 10;
BA_ "GenSigSendOnInit" SG_ 2155266048 RRHCSeatSw1Act 2;
BA_ "SignalType" SG_ 2155266048 RRHCSeatSw1Act "BLN";
BA_ "SignalLongName" SG_ 2155266048 RRHCSeatSw1Act "Rear Right Heated/Cooled Seat Switch #1 Active";
BA_ "VNSigAllNodes" SG_ 2155266048 RRHCSeatSw1Act 1;
BA_ "GenSigSendType" SG_ 2155266048 RLHCSeatSw3Act 10;
BA_ "GenSigSendOnInit" SG_ 2155266048 RLHCSeatSw3Act 2;
BA_ "SignalType" SG_ 2155266048 RLHCSeatSw3Act "BLN";
BA_ "SignalLongName" SG_ 2155266048 RLHCSeatSw3Act "Rear Left Heated/Cooled Seat Switch #3 Active";
BA_ "VNSigAllNodes" SG_ 2155266048 RLHCSeatSw3Act 1;
BA_ "GenSigSendType" SG_ 2155266048 RLHCSeatSw2Act 10;
BA_ "GenSigSendOnInit" SG_ 2155266048 RLHCSeatSw2Act 2;
BA_ "SignalType" SG_ 2155266048 RLHCSeatSw2Act "BLN";
BA_ "SignalLongName" SG_ 2155266048 RLHCSeatSw2Act "Rear Left Heated/Cooled Seat Switch #2 Active";
BA_ "VNSigAllNodes" SG_ 2155266048 RLHCSeatSw2Act 1;
BA_ "GenSigSendType" SG_ 2155266048 RLHCSeatSw1Act 10;
BA_ "GenSigSendOnInit" SG_ 2155266048 RLHCSeatSw1Act 2;
BA_ "SignalType" SG_ 2155266048 RLHCSeatSw1Act "BLN";
BA_ "SignalLongName" SG_ 2155266048 RLHCSeatSw1Act "Rear Left Heated/Cooled Seat Switch #1 Active";
BA_ "VNSigAllNodes" SG_ 2155266048 RLHCSeatSw1Act 1;
BA_ "GenSigSendType" SG_ 2155249664 RRHCSMInd3 10;
BA_ "GenSigSendOnInit" SG_ 2155249664 RRHCSMInd3 1;
BA_ "SignalType" SG_ 2155249664 RRHCSMInd3 "BLN";
BA_ "PacketOrder" SG_ 2155249664 RRHCSMInd3 4;
BA_ "SignalLongName" SG_ 2155249664 RRHCSMInd3 "Rear Right Heated/Cooled Seat Mode Indication Control : Seat Mode Indication 3";
BA_ "VNSigAllNodes" SG_ 2155249664 RRHCSMInd3 1;
BA_ "GenSigSendType" SG_ 2155249664 RRHCSMInd2 10;
BA_ "GenSigSendOnInit" SG_ 2155249664 RRHCSMInd2 1;
BA_ "SignalType" SG_ 2155249664 RRHCSMInd2 "BLN";
BA_ "PacketOrder" SG_ 2155249664 RRHCSMInd2 3;
BA_ "SignalLongName" SG_ 2155249664 RRHCSMInd2 "Rear Right Heated/Cooled Seat Mode Indication Control : Seat Mode Indication 2";
BA_ "VNSigAllNodes" SG_ 2155249664 RRHCSMInd2 1;
BA_ "GenSigSendType" SG_ 2155249664 RRHCSMInd1 10;
BA_ "GenSigSendOnInit" SG_ 2155249664 RRHCSMInd1 1;
BA_ "SignalType" SG_ 2155249664 RRHCSMInd1 "BLN";
BA_ "PacketOrder" SG_ 2155249664 RRHCSMInd1 2;
BA_ "SignalLongName" SG_ 2155249664 RRHCSMInd1 "Rear Right Heated/Cooled Seat Mode Indication Control : Seat Mode Indication 1";
BA_ "VNSigAllNodes" SG_ 2155249664 RRHCSMInd1 1;
BA_ "GenSigSendType" SG_ 2155249664 RRHCSMIndReq 10;
BA_ "GenSigSendOnInit" SG_ 2155249664 RRHCSMIndReq 1;
BA_ "SignalType" SG_ 2155249664 RRHCSMIndReq "ENM";
BA_ "PacketOrder" SG_ 2155249664 RRHCSMIndReq 1;
BA_ "SignalLongName" SG_ 2155249664 RRHCSMIndReq "Rear Right Heated/Cooled Seat Mode Indication Control : Indication Request";
BA_ "VNSigAllNodes" SG_ 2155249664 RRHCSMIndReq 1;
BA_ "GenSigSendType" SG_ 2155249664 RRHCSLSeatLev5 10;
BA_ "GenSigSendOnInit" SG_ 2155249664 RRHCSLSeatLev5 1;
BA_ "SignalType" SG_ 2155249664 RRHCSLSeatLev5 "BLN";
BA_ "PacketOrder" SG_ 2155249664 RRHCSLSeatLev5 6;
BA_ "SignalLongName" SG_ 2155249664 RRHCSLSeatLev5 "Rear Right Heated/Cooled Seat Level Indication Control : Seat Level 5";
BA_ "VNSigAllNodes" SG_ 2155249664 RRHCSLSeatLev5 1;
BA_ "GenSigSendType" SG_ 2155249664 RRHCSLSeatLev4 10;
BA_ "GenSigSendOnInit" SG_ 2155249664 RRHCSLSeatLev4 1;
BA_ "SignalType" SG_ 2155249664 RRHCSLSeatLev4 "BLN";
BA_ "PacketOrder" SG_ 2155249664 RRHCSLSeatLev4 5;
BA_ "SignalLongName" SG_ 2155249664 RRHCSLSeatLev4 "Rear Right Heated/Cooled Seat Level Indication Control : Seat Level 4";
BA_ "VNSigAllNodes" SG_ 2155249664 RRHCSLSeatLev4 1;
BA_ "GenSigSendType" SG_ 2155249664 RRHCSLSeatLev3 10;
BA_ "GenSigSendOnInit" SG_ 2155249664 RRHCSLSeatLev3 1;
BA_ "SignalType" SG_ 2155249664 RRHCSLSeatLev3 "BLN";
BA_ "PacketOrder" SG_ 2155249664 RRHCSLSeatLev3 4;
BA_ "SignalLongName" SG_ 2155249664 RRHCSLSeatLev3 "Rear Right Heated/Cooled Seat Level Indication Control : Seat Level 3";
BA_ "VNSigAllNodes" SG_ 2155249664 RRHCSLSeatLev3 1;
BA_ "GenSigSendType" SG_ 2155249664 RRHCSLSeatLev2 10;
BA_ "GenSigSendOnInit" SG_ 2155249664 RRHCSLSeatLev2 1;
BA_ "SignalType" SG_ 2155249664 RRHCSLSeatLev2 "BLN";
BA_ "PacketOrder" SG_ 2155249664 RRHCSLSeatLev2 3;
BA_ "SignalLongName" SG_ 2155249664 RRHCSLSeatLev2 "Rear Right Heated/Cooled Seat Level Indication Control : Seat Level 2";
BA_ "VNSigAllNodes" SG_ 2155249664 RRHCSLSeatLev2 1;
BA_ "GenSigSendType" SG_ 2155249664 RRHCSLSeatLev1 10;
BA_ "GenSigSendOnInit" SG_ 2155249664 RRHCSLSeatLev1 1;
BA_ "SignalType" SG_ 2155249664 RRHCSLSeatLev1 "BLN";
BA_ "PacketOrder" SG_ 2155249664 RRHCSLSeatLev1 2;
BA_ "SignalLongName" SG_ 2155249664 RRHCSLSeatLev1 "Rear Right Heated/Cooled Seat Level Indication Control : Seat Level 1";
BA_ "VNSigAllNodes" SG_ 2155249664 RRHCSLSeatLev1 1;
BA_ "GenSigSendType" SG_ 2155249664 RRHCSLIndReq 10;
BA_ "GenSigSendOnInit" SG_ 2155249664 RRHCSLIndReq 1;
BA_ "SignalType" SG_ 2155249664 RRHCSLIndReq "ENM";
BA_ "PacketOrder" SG_ 2155249664 RRHCSLIndReq 1;
BA_ "SignalLongName" SG_ 2155249664 RRHCSLIndReq "Rear Right Heated/Cooled Seat Level Indication Control : Indication Request";
BA_ "VNSigAllNodes" SG_ 2155249664 RRHCSLIndReq 1;
BA_ "GenSigSendType" SG_ 2155249664 RLHCSMInd3 10;
BA_ "GenSigSendOnInit" SG_ 2155249664 RLHCSMInd3 1;
BA_ "SignalType" SG_ 2155249664 RLHCSMInd3 "BLN";
BA_ "PacketOrder" SG_ 2155249664 RLHCSMInd3 4;
BA_ "SignalLongName" SG_ 2155249664 RLHCSMInd3 "Rear Left Heated/Cooled Seat Mode Indication Control : Seat Mode Indication 3";
BA_ "VNSigAllNodes" SG_ 2155249664 RLHCSMInd3 1;
BA_ "GenSigSendType" SG_ 2155249664 RLHCSMInd2 10;
BA_ "GenSigSendOnInit" SG_ 2155249664 RLHCSMInd2 1;
BA_ "SignalType" SG_ 2155249664 RLHCSMInd2 "BLN";
BA_ "PacketOrder" SG_ 2155249664 RLHCSMInd2 3;
BA_ "SignalLongName" SG_ 2155249664 RLHCSMInd2 "Rear Left Heated/Cooled Seat Mode Indication Control : Seat Mode Indication 2";
BA_ "VNSigAllNodes" SG_ 2155249664 RLHCSMInd2 1;
BA_ "GenSigSendType" SG_ 2155249664 RLHCSMInd1 10;
BA_ "GenSigSendOnInit" SG_ 2155249664 RLHCSMInd1 1;
BA_ "SignalType" SG_ 2155249664 RLHCSMInd1 "BLN";
BA_ "PacketOrder" SG_ 2155249664 RLHCSMInd1 2;
BA_ "SignalLongName" SG_ 2155249664 RLHCSMInd1 "Rear Left Heated/Cooled Seat Mode Indication Control : Seat Mode Indication 1";
BA_ "VNSigAllNodes" SG_ 2155249664 RLHCSMInd1 1;
BA_ "GenSigSendType" SG_ 2155249664 RLHCSMIndReq 10;
BA_ "GenSigSendOnInit" SG_ 2155249664 RLHCSMIndReq 1;
BA_ "SignalType" SG_ 2155249664 RLHCSMIndReq "ENM";
BA_ "PacketOrder" SG_ 2155249664 RLHCSMIndReq 1;
BA_ "SignalLongName" SG_ 2155249664 RLHCSMIndReq "Rear Left Heated/Cooled Seat Mode Indication Control : Indication Request";
BA_ "VNSigAllNodes" SG_ 2155249664 RLHCSMIndReq 1;
BA_ "GenSigSendType" SG_ 2155249664 RLHCSLSeatLev5 10;
BA_ "GenSigSendOnInit" SG_ 2155249664 RLHCSLSeatLev5 1;
BA_ "SignalType" SG_ 2155249664 RLHCSLSeatLev5 "BLN";
BA_ "PacketOrder" SG_ 2155249664 RLHCSLSeatLev5 6;
BA_ "SignalLongName" SG_ 2155249664 RLHCSLSeatLev5 "Rear Left Heated/Cooled Seat Level Indication Control : Seat Level 5";
BA_ "VNSigAllNodes" SG_ 2155249664 RLHCSLSeatLev5 1;
BA_ "GenSigSendType" SG_ 2155249664 RLHCSLSeatLev4 10;
BA_ "GenSigSendOnInit" SG_ 2155249664 RLHCSLSeatLev4 1;
BA_ "SignalType" SG_ 2155249664 RLHCSLSeatLev4 "BLN";
BA_ "PacketOrder" SG_ 2155249664 RLHCSLSeatLev4 5;
BA_ "SignalLongName" SG_ 2155249664 RLHCSLSeatLev4 "Rear Left Heated/Cooled Seat Level Indication Control : Seat Level 4";
BA_ "VNSigAllNodes" SG_ 2155249664 RLHCSLSeatLev4 1;
BA_ "GenSigSendType" SG_ 2155249664 RLHCSLSeatLev3 10;
BA_ "GenSigSendOnInit" SG_ 2155249664 RLHCSLSeatLev3 1;
BA_ "SignalType" SG_ 2155249664 RLHCSLSeatLev3 "BLN";
BA_ "PacketOrder" SG_ 2155249664 RLHCSLSeatLev3 4;
BA_ "SignalLongName" SG_ 2155249664 RLHCSLSeatLev3 "Rear Left Heated/Cooled Seat Level Indication Control : Seat Level 3";
BA_ "VNSigAllNodes" SG_ 2155249664 RLHCSLSeatLev3 1;
BA_ "GenSigSendType" SG_ 2155249664 RLHCSLSeatLev2 10;
BA_ "GenSigSendOnInit" SG_ 2155249664 RLHCSLSeatLev2 1;
BA_ "SignalType" SG_ 2155249664 RLHCSLSeatLev2 "BLN";
BA_ "PacketOrder" SG_ 2155249664 RLHCSLSeatLev2 3;
BA_ "SignalLongName" SG_ 2155249664 RLHCSLSeatLev2 "Rear Left Heated/Cooled Seat Level Indication Control : Seat Level 2";
BA_ "VNSigAllNodes" SG_ 2155249664 RLHCSLSeatLev2 1;
BA_ "GenSigSendType" SG_ 2155249664 RLHCSLSeatLev1 10;
BA_ "GenSigSendOnInit" SG_ 2155249664 RLHCSLSeatLev1 1;
BA_ "SignalType" SG_ 2155249664 RLHCSLSeatLev1 "BLN";
BA_ "PacketOrder" SG_ 2155249664 RLHCSLSeatLev1 2;
BA_ "SignalLongName" SG_ 2155249664 RLHCSLSeatLev1 "Rear Left Heated/Cooled Seat Level Indication Control : Seat Level 1";
BA_ "VNSigAllNodes" SG_ 2155249664 RLHCSLSeatLev1 1;
BA_ "GenSigSendType" SG_ 2155249664 RLHCSLIndReq 10;
BA_ "GenSigSendOnInit" SG_ 2155249664 RLHCSLIndReq 1;
BA_ "SignalType" SG_ 2155249664 RLHCSLIndReq "ENM";
BA_ "PacketOrder" SG_ 2155249664 RLHCSLIndReq 1;
BA_ "SignalLongName" SG_ 2155249664 RLHCSLIndReq "Rear Left Heated/Cooled Seat Level Indication Control : Indication Request";
BA_ "VNSigAllNodes" SG_ 2155249664 RLHCSLIndReq 1;
BA_ "GenSigSendType" SG_ 2154741760 RSAPrsnt 10;
BA_ "GenSigSendOnInit" SG_ 2154741760 RSAPrsnt 2;
BA_ "VNSigInfotainment" SG_ 2154741760 RSAPrsnt 1;
BA_ "SignalType" SG_ 2154741760 RSAPrsnt "BLN";
BA_ "SignalLongName" SG_ 2154741760 RSAPrsnt "Rear Seat Audio Present";
BA_ "VNSigAllNodes" SG_ 2154741760 RSAPrsnt 1;
BA_ "GenSigDeltaValue" SG_ 2159132672 ODIAR_FUCID 1;
BA_ "GenSigSendType" SG_ 2159132672 ODIAR_FUCID 12;
BA_ "VNSigInfotainment" SG_ 2159132672 ODIAR_FUCID 1;
BA_ "SignalType" SG_ 2159132672 ODIAR_FUCID "UNM";
BA_ "PacketOrder" SG_ 2159132672 ODIAR_FUCID 2;
BA_ "SignalLongName" SG_ 2159132672 ODIAR_FUCID "Open Display Interface Action Rear Seat Display : FU Class ID";
BA_ "VNSigAllNodes" SG_ 2159132672 ODIAR_FUCID 1;
BA_ "GenSigSendType" SG_ 2159132672 ODIAR_DspMID 10;
BA_ "VNSigInfotainment" SG_ 2159132672 ODIAR_DspMID 1;
BA_ "SignalType" SG_ 2159132672 ODIAR_DspMID "ENM";
BA_ "PacketOrder" SG_ 2159132672 ODIAR_DspMID 4;
BA_ "SignalLongName" SG_ 2159132672 ODIAR_DspMID "Open Display Interface Action Rear Seat Display : Display Mask ID";
BA_ "VNSigAllNodes" SG_ 2159132672 ODIAR_DspMID 1;
BA_ "GenSigSendType" SG_ 2159132672 ODIAR_DaTy 10;
BA_ "VNSigInfotainment" SG_ 2159132672 ODIAR_DaTy 1;
BA_ "SignalType" SG_ 2159132672 ODIAR_DaTy "ENM";
BA_ "PacketOrder" SG_ 2159132672 ODIAR_DaTy 1;
BA_ "SignalLongName" SG_ 2159132672 ODIAR_DaTy "Open Display Interface Action Rear Seat Display : DataType";
BA_ "VNSigAllNodes" SG_ 2159132672 ODIAR_DaTy 1;
BA_ "GenSigDeltaValue" SG_ 2159132672 ODIAR_ActnVal 1;
BA_ "GenSigSendType" SG_ 2159132672 ODIAR_ActnVal 12;
BA_ "VNSigInfotainment" SG_ 2159132672 ODIAR_ActnVal 1;
BA_ "SignalType" SG_ 2159132672 ODIAR_ActnVal "UNM";
BA_ "PacketOrder" SG_ 2159132672 ODIAR_ActnVal 5;
BA_ "SignalLongName" SG_ 2159132672 ODIAR_ActnVal "Open Display Interface Action Rear Seat Display : Action Value";
BA_ "VNSigAllNodes" SG_ 2159132672 ODIAR_ActnVal 1;
BA_ "GenSigDeltaValue" SG_ 2159132672 ODIAR_ActnID 1;
BA_ "GenSigSendType" SG_ 2159132672 ODIAR_ActnID 12;
BA_ "VNSigInfotainment" SG_ 2159132672 ODIAR_ActnID 1;
BA_ "SignalType" SG_ 2159132672 ODIAR_ActnID "UNM";
BA_ "PacketOrder" SG_ 2159132672 ODIAR_ActnID 3;
BA_ "SignalLongName" SG_ 2159132672 ODIAR_ActnID "Open Display Interface Action Rear Seat Display : Action ID";
BA_ "VNSigAllNodes" SG_ 2159132672 ODIAR_ActnID 1;
BA_ "GenSigDeltaValue" SG_ 2158968832 ODI_RSD2CntrStck 1;
BA_ "GenSigSendType" SG_ 2158968832 ODI_RSD2CntrStck 12;
BA_ "VNSigInfotainment" SG_ 2158968832 ODI_RSD2CntrStck 1;
BA_ "SignalType" SG_ 2158968832 ODI_RSD2CntrStck "UNM";
BA_ "SignalLongName" SG_ 2158968832 ODI_RSD2CntrStck "Open Display Interface Rear Seat Display 2 Centerstack";
BA_ "VNSigAllNodes" SG_ 2158968832 ODI_RSD2CntrStck 1;
BA_ "GenSigSendType" SG_ 2158952448 ODDMR_ReqType 10;
BA_ "VNSigInfotainment" SG_ 2158952448 ODDMR_ReqType 1;
BA_ "SignalType" SG_ 2158952448 ODDMR_ReqType "ENM";
BA_ "PacketOrder" SG_ 2158952448 ODDMR_ReqType 1;
BA_ "SignalLongName" SG_ 2158952448 ODDMR_ReqType "Open Display Interface Dynamic Data Multi Request Rear Seat Display : Request Type";
BA_ "VNSigAllNodes" SG_ 2158952448 ODDMR_ReqType 1;
BA_ "GenSigDeltaValue" SG_ 2158952448 ODDMR_FUCID 1;
BA_ "GenSigSendType" SG_ 2158952448 ODDMR_FUCID 12;
BA_ "VNSigInfotainment" SG_ 2158952448 ODDMR_FUCID 1;
BA_ "SignalType" SG_ 2158952448 ODDMR_FUCID "UNM";
BA_ "PacketOrder" SG_ 2158952448 ODDMR_FUCID 6;
BA_ "SignalLongName" SG_ 2158952448 ODDMR_FUCID "Open Display Interface Dynamic Data Multi Request Rear Seat Display : Functional Unit Class ID";
BA_ "VNSigAllNodes" SG_ 2158952448 ODDMR_FUCID 1;
BA_ "GenSigSendType" SG_ 2158952448 ODDMR_DispMID 10;
BA_ "VNSigInfotainment" SG_ 2158952448 ODDMR_DispMID 1;
BA_ "SignalType" SG_ 2158952448 ODDMR_DispMID "ENM";
BA_ "PacketOrder" SG_ 2158952448 ODDMR_DispMID 7;
BA_ "SignalLongName" SG_ 2158952448 ODDMR_DispMID "Open Display Interface Dynamic Data Multi Request Rear Seat Display : Display Mask Id";
BA_ "VNSigAllNodes" SG_ 2158952448 ODDMR_DispMID 1;
BA_ "GenSigSendType" SG_ 2158952448 ODDMR_DataID2Vld 10;
BA_ "VNSigInfotainment" SG_ 2158952448 ODDMR_DataID2Vld 1;
BA_ "SignalType" SG_ 2158952448 ODDMR_DataID2Vld "BLN";
BA_ "PacketOrder" SG_ 2158952448 ODDMR_DataID2Vld 5;
BA_ "SignalLongName" SG_ 2158952448 ODDMR_DataID2Vld "Open Display Interface Dynamic Data Multi Request Rear Seat Display : Data ID Two Valid";
BA_ "VNSigAllNodes" SG_ 2158952448 ODDMR_DataID2Vld 1;
BA_ "GenSigDeltaValue" SG_ 2158952448 ODDMR_DataID2 1;
BA_ "GenSigSendType" SG_ 2158952448 ODDMR_DataID2 12;
BA_ "VNSigInfotainment" SG_ 2158952448 ODDMR_DataID2 1;
BA_ "SignalType" SG_ 2158952448 ODDMR_DataID2 "UNM";
BA_ "PacketOrder" SG_ 2158952448 ODDMR_DataID2 9;
BA_ "SignalLongName" SG_ 2158952448 ODDMR_DataID2 "Open Display Interface Dynamic Data Multi Request Rear Seat Display : Data ID Two";
BA_ "VNSigAllNodes" SG_ 2158952448 ODDMR_DataID2 1;
BA_ "GenSigSendType" SG_ 2158952448 ODDMR_DataID3Vld 10;
BA_ "VNSigInfotainment" SG_ 2158952448 ODDMR_DataID3Vld 1;
BA_ "SignalType" SG_ 2158952448 ODDMR_DataID3Vld "BLN";
BA_ "PacketOrder" SG_ 2158952448 ODDMR_DataID3Vld 4;
BA_ "SignalLongName" SG_ 2158952448 ODDMR_DataID3Vld "Open Display Interface Dynamic Data Multi Request Rear Seat Display : Data ID Three Valid";
BA_ "VNSigAllNodes" SG_ 2158952448 ODDMR_DataID3Vld 1;
BA_ "GenSigDeltaValue" SG_ 2158952448 ODDMR_DataID3 1;
BA_ "GenSigSendType" SG_ 2158952448 ODDMR_DataID3 12;
BA_ "VNSigInfotainment" SG_ 2158952448 ODDMR_DataID3 1;
BA_ "SignalType" SG_ 2158952448 ODDMR_DataID3 "UNM";
BA_ "PacketOrder" SG_ 2158952448 ODDMR_DataID3 10;
BA_ "SignalLongName" SG_ 2158952448 ODDMR_DataID3 "Open Display Interface Dynamic Data Multi Request Rear Seat Display : Data ID Three";
BA_ "VNSigAllNodes" SG_ 2158952448 ODDMR_DataID3 1;
BA_ "GenSigDeltaValue" SG_ 2158952448 ODDMR_DataID1 1;
BA_ "GenSigSendType" SG_ 2158952448 ODDMR_DataID1 12;
BA_ "VNSigInfotainment" SG_ 2158952448 ODDMR_DataID1 1;
BA_ "SignalType" SG_ 2158952448 ODDMR_DataID1 "UNM";
BA_ "PacketOrder" SG_ 2158952448 ODDMR_DataID1 8;
BA_ "SignalLongName" SG_ 2158952448 ODDMR_DataID1 "Open Display Interface Dynamic Data Multi Request Rear Seat Display : Data ID One";
BA_ "VNSigAllNodes" SG_ 2158952448 ODDMR_DataID1 1;
BA_ "GenSigSendType" SG_ 2158952448 ODDMR_DataID4Vld 10;
BA_ "VNSigInfotainment" SG_ 2158952448 ODDMR_DataID4Vld 1;
BA_ "SignalType" SG_ 2158952448 ODDMR_DataID4Vld "BLN";
BA_ "PacketOrder" SG_ 2158952448 ODDMR_DataID4Vld 3;
BA_ "SignalLongName" SG_ 2158952448 ODDMR_DataID4Vld "Open Display Interface Dynamic Data Multi Request Rear Seat Display : Data ID Four Valid";
BA_ "VNSigAllNodes" SG_ 2158952448 ODDMR_DataID4Vld 1;
BA_ "GenSigDeltaValue" SG_ 2158952448 ODDMR_DataID4 1;
BA_ "GenSigSendType" SG_ 2158952448 ODDMR_DataID4 12;
BA_ "VNSigInfotainment" SG_ 2158952448 ODDMR_DataID4 1;
BA_ "SignalType" SG_ 2158952448 ODDMR_DataID4 "UNM";
BA_ "PacketOrder" SG_ 2158952448 ODDMR_DataID4 11;
BA_ "SignalLongName" SG_ 2158952448 ODDMR_DataID4 "Open Display Interface Dynamic Data Multi Request Rear Seat Display : Data ID Four";
BA_ "VNSigAllNodes" SG_ 2158952448 ODDMR_DataID4 1;
BA_ "GenSigSendType" SG_ 2158952448 ODDMR_DataID5Vld 10;
BA_ "VNSigInfotainment" SG_ 2158952448 ODDMR_DataID5Vld 1;
BA_ "SignalType" SG_ 2158952448 ODDMR_DataID5Vld "BLN";
BA_ "PacketOrder" SG_ 2158952448 ODDMR_DataID5Vld 2;
BA_ "SignalLongName" SG_ 2158952448 ODDMR_DataID5Vld "Open Display Interface Dynamic Data Multi Request Rear Seat Display : Data ID Five Valid";
BA_ "VNSigAllNodes" SG_ 2158952448 ODDMR_DataID5Vld 1;
BA_ "GenSigDeltaValue" SG_ 2158952448 ODDMR_DataID5 1;
BA_ "GenSigSendType" SG_ 2158952448 ODDMR_DataID5 12;
BA_ "VNSigInfotainment" SG_ 2158952448 ODDMR_DataID5 1;
BA_ "SignalType" SG_ 2158952448 ODDMR_DataID5 "UNM";
BA_ "PacketOrder" SG_ 2158952448 ODDMR_DataID5 12;
BA_ "SignalLongName" SG_ 2158952448 ODDMR_DataID5 "Open Display Interface Dynamic Data Multi Request Rear Seat Display : Data ID Five";
BA_ "VNSigAllNodes" SG_ 2158952448 ODDMR_DataID5 1;
BA_ "GenSigDeltaValue" SG_ 2158944256 ODDLR_SubIdReqM 1;
BA_ "GenSigSendType" SG_ 2158944256 ODDLR_SubIdReqM 12;
BA_ "VNSigInfotainment" SG_ 2158944256 ODDLR_SubIdReqM 1;
BA_ "SignalType" SG_ 2158944256 ODDLR_SubIdReqM "UNM";
BA_ "PacketOrder" SG_ 2158944256 ODDLR_SubIdReqM 10;
BA_ "SignalLongName" SG_ 2158944256 ODDLR_SubIdReqM "Open Display Interface Dynamic Data List Request Rear Seat Display : Sub Id Request Mask";
BA_ "VNSigAllNodes" SG_ 2158944256 ODDLR_SubIdReqM 1;
BA_ "GenSigSendType" SG_ 2158944256 ODDLR_WrpArnd 10;
BA_ "VNSigInfotainment" SG_ 2158944256 ODDLR_WrpArnd 1;
BA_ "SignalType" SG_ 2158944256 ODDLR_WrpArnd "BLN";
BA_ "PacketOrder" SG_ 2158944256 ODDLR_WrpArnd 9;
BA_ "SignalLongName" SG_ 2158944256 ODDLR_WrpArnd "Open Display Interface Dynamic Data List Request Rear Seat Display : Wrap Around";
BA_ "VNSigAllNodes" SG_ 2158944256 ODDLR_WrpArnd 1;
BA_ "GenSigSendType" SG_ 2158944256 ODDLR_ReqType 10;
BA_ "VNSigInfotainment" SG_ 2158944256 ODDLR_ReqType 1;
BA_ "SignalType" SG_ 2158944256 ODDLR_ReqType "ENM";
BA_ "PacketOrder" SG_ 2158944256 ODDLR_ReqType 7;
BA_ "SignalLongName" SG_ 2158944256 ODDLR_ReqType "Open Display Interface Dynamic Data List Request Rear Seat Display : Request Type";
BA_ "VNSigAllNodes" SG_ 2158944256 ODDLR_ReqType 1;
BA_ "GenSigSendType" SG_ 2158944256 ODDLR_ReqDir 10;
BA_ "VNSigInfotainment" SG_ 2158944256 ODDLR_ReqDir 1;
BA_ "SignalType" SG_ 2158944256 ODDLR_ReqDir "BLN";
BA_ "PacketOrder" SG_ 2158944256 ODDLR_ReqDir 5;
BA_ "SignalLongName" SG_ 2158944256 ODDLR_ReqDir "Open Display Interface Dynamic Data List Request Rear Seat Display : Req Direction";
BA_ "VNSigAllNodes" SG_ 2158944256 ODDLR_ReqDir 1;
BA_ "GenSigDeltaValue" SG_ 2158944256 ODDLR_NmEntries 1;
BA_ "GenSigSendType" SG_ 2158944256 ODDLR_NmEntries 12;
BA_ "VNSigInfotainment" SG_ 2158944256 ODDLR_NmEntries 1;
BA_ "SignalType" SG_ 2158944256 ODDLR_NmEntries "UNM";
BA_ "PacketOrder" SG_ 2158944256 ODDLR_NmEntries 4;
BA_ "SignalLongName" SG_ 2158944256 ODDLR_NmEntries "Open Display Interface Dynamic Data List Request Rear Seat Display : Num Entries";
BA_ "VNSigAllNodes" SG_ 2158944256 ODDLR_NmEntries 1;
BA_ "GenSigDeltaValue" SG_ 2158944256 ODDLR_Idx 1;
BA_ "GenSigSendType" SG_ 2158944256 ODDLR_Idx 12;
BA_ "VNSigInfotainment" SG_ 2158944256 ODDLR_Idx 1;
BA_ "SignalType" SG_ 2158944256 ODDLR_Idx "UNM";
BA_ "PacketOrder" SG_ 2158944256 ODDLR_Idx 6;
BA_ "SignalLongName" SG_ 2158944256 ODDLR_Idx "Open Display Interface Dynamic Data List Request Rear Seat Display : Index";
BA_ "VNSigAllNodes" SG_ 2158944256 ODDLR_Idx 1;
BA_ "GenSigDeltaValue" SG_ 2158944256 ODDLR_FUCID 1;
BA_ "GenSigSendType" SG_ 2158944256 ODDLR_FUCID 12;
BA_ "VNSigInfotainment" SG_ 2158944256 ODDLR_FUCID 1;
BA_ "SignalType" SG_ 2158944256 ODDLR_FUCID "UNM";
BA_ "PacketOrder" SG_ 2158944256 ODDLR_FUCID 1;
BA_ "SignalLongName" SG_ 2158944256 ODDLR_FUCID "Open Display Interface Dynamic Data List Request Rear Seat Display : Functional Unit Class ID";
BA_ "VNSigAllNodes" SG_ 2158944256 ODDLR_FUCID 1;
BA_ "GenSigSendType" SG_ 2158944256 ODDLR_DspMID 10;
BA_ "VNSigInfotainment" SG_ 2158944256 ODDLR_DspMID 1;
BA_ "SignalType" SG_ 2158944256 ODDLR_DspMID "ENM";
BA_ "PacketOrder" SG_ 2158944256 ODDLR_DspMID 3;
BA_ "SignalLongName" SG_ 2158944256 ODDLR_DspMID "Open Display Interface Dynamic Data List Request Rear Seat Display : Display Mask Id";
BA_ "VNSigAllNodes" SG_ 2158944256 ODDLR_DspMID 1;
BA_ "GenSigDeltaValue" SG_ 2158944256 ODDLR_DataId 1;
BA_ "GenSigSendType" SG_ 2158944256 ODDLR_DataId 12;
BA_ "VNSigInfotainment" SG_ 2158944256 ODDLR_DataId 1;
BA_ "SignalType" SG_ 2158944256 ODDLR_DataId "UNM";
BA_ "PacketOrder" SG_ 2158944256 ODDLR_DataId 2;
BA_ "SignalLongName" SG_ 2158944256 ODDLR_DataId "Open Display Interface Dynamic Data List Request Rear Seat Display : Data Id";
BA_ "VNSigAllNodes" SG_ 2158944256 ODDLR_DataId 1;
BA_ "GenSigSendType" SG_ 2158944256 ODDLR_BckgndFlag 10;
BA_ "VNSigInfotainment" SG_ 2158944256 ODDLR_BckgndFlag 1;
BA_ "SignalType" SG_ 2158944256 ODDLR_BckgndFlag "ENM";
BA_ "PacketOrder" SG_ 2158944256 ODDLR_BckgndFlag 8;
BA_ "SignalLongName" SG_ 2158944256 ODDLR_BckgndFlag "Open Display Interface Dynamic Data List Request Rear Seat Display : Background Flag";
BA_ "VNSigAllNodes" SG_ 2158944256 ODDLR_BckgndFlag 1;
BA_ "SignalType" SG_ 1616 DgnInf "UNM";
BA_ "SignalLongName" SG_ 1616 DgnInf "Diagnostic Information";
BA_ "VNSigDiagnostic" SG_ 1616 DgnInf 1;
BA_ "VNSigAllNodes" SG_ 1616 DgnInf 1;
BA_ "VNSigPrimaryTriggering" SG_ 1584 VectraSpcNWMgtD 1;
BA_ "VNSigRemoteDiagnostics" SG_ 1584 VectraSpcNWMgtD 1;
BA_ "VNSigInfotainment" SG_ 1584 VectraSpcNWMgtD 1;
BA_ "VNSigParkedVehicle" SG_ 1584 VectraSpcNWMgtD 1;
BA_ "VNSigIntermediate" SG_ 1584 VectraSpcNWMgtD 1;
BA_ "VNSigUnused_4" SG_ 1584 VectraSpcNWMgtD 1;
BA_ "SignalType" SG_ 1584 VectraSpcNWMgtD "UNM";
BA_ "SignalLongName" SG_ 1584 VectraSpcNWMgtD "Vectra Specific Network Management Data";
BA_ "VNSigDiagnostic" SG_ 1584 VectraSpcNWMgtD 1;
BA_ "VNSigAllNodes" SG_ 1584 VectraSpcNWMgtD 1;
BA_ "GenSigDeltaValue" SG_ 1360 DgnInf_LS550 1;
BA_ "GenSigSendType" SG_ 1360 DgnInf_LS550 12;
BA_ "SignalType" SG_ 1360 DgnInf_LS550 "UNM";
BA_ "SignalLongName" SG_ 1360 DgnInf_LS550 "Diagnostic Information LS550";
BA_ "VNSigDiagnostic" SG_ 1360 DgnInf_LS550 1;
BA_ "VNSigAllNodes" SG_ 1360 DgnInf_LS550 1;
BA_ "GenSigDeltaValue" SG_ 2159206400 ODI_AxIP2IPC 1;
BA_ "GenSigSendType" SG_ 2159206400 ODI_AxIP2IPC 12;
BA_ "VNSigInfotainment" SG_ 2159206400 ODI_AxIP2IPC 1;
BA_ "SignalType" SG_ 2159206400 ODI_AxIP2IPC "UNM";
BA_ "SignalLongName" SG_ 2159206400 ODI_AxIP2IPC "Open Display Interface AuxIP 2 IPC";
BA_ "VNSigAllNodes" SG_ 2159206400 ODI_AxIP2IPC 1;
BA_ "GenSigDeltaValue" SG_ 2159190016 ODI_AxIP2CntrStck 1;
BA_ "GenSigSendType" SG_ 2159190016 ODI_AxIP2CntrStck 12;
BA_ "VNSigInfotainment" SG_ 2159190016 ODI_AxIP2CntrStck 1;
BA_ "SignalType" SG_ 2159190016 ODI_AxIP2CntrStck "UNM";
BA_ "SignalLongName" SG_ 2159190016 ODI_AxIP2CntrStck "Open Display Interface AuxIP 2 CenterStack";
BA_ "VNSigAllNodes" SG_ 2159190016 ODI_AxIP2CntrStck 1;
BA_ "GenSigDeltaValue" SG_ 2159124480 ODI_AxIP2TEL 1;
BA_ "GenSigSendType" SG_ 2159124480 ODI_AxIP2TEL 12;
BA_ "VNSigInfotainment" SG_ 2159124480 ODI_AxIP2TEL 1;
BA_ "SignalType" SG_ 2159124480 ODI_AxIP2TEL "UNM";
BA_ "SignalLongName" SG_ 2159124480 ODI_AxIP2TEL "Open Display Interface AuxIP 2 TEL";
BA_ "VNSigAllNodes" SG_ 2159124480 ODI_AxIP2TEL 1;
BA_ "GenSigDeltaValue" SG_ 2159108096 ODI_AxIP2DAB 1;
BA_ "GenSigSendType" SG_ 2159108096 ODI_AxIP2DAB 12;
BA_ "VNSigInfotainment" SG_ 2159108096 ODI_AxIP2DAB 1;
BA_ "SignalType" SG_ 2159108096 ODI_AxIP2DAB "UNM";
BA_ "SignalLongName" SG_ 2159108096 ODI_AxIP2DAB "Open Display Interface AuxIP 2 DAB";
BA_ "VNSigAllNodes" SG_ 2159108096 ODI_AxIP2DAB 1;
BA_ "GenSigSendType" SG_ 2158903296 ODDMA_ReqType 10;
BA_ "VNSigInfotainment" SG_ 2158903296 ODDMA_ReqType 1;
BA_ "SignalType" SG_ 2158903296 ODDMA_ReqType "ENM";
BA_ "PacketOrder" SG_ 2158903296 ODDMA_ReqType 1;
BA_ "SignalLongName" SG_ 2158903296 ODDMA_ReqType "Open Display Interface Dynamic Data Multi Request Auxiliary IP : Request Type";
BA_ "VNSigAllNodes" SG_ 2158903296 ODDMA_ReqType 1;
BA_ "GenSigSendType" SG_ 2158903296 ODDMA_FUCID 12;
BA_ "VNSigInfotainment" SG_ 2158903296 ODDMA_FUCID 1;
BA_ "SignalType" SG_ 2158903296 ODDMA_FUCID "UNM";
BA_ "PacketOrder" SG_ 2158903296 ODDMA_FUCID 6;
BA_ "SignalLongName" SG_ 2158903296 ODDMA_FUCID "Open Display Interface Dynamic Data Multi Request Auxiliary IP : Functional Unit Class ID";
BA_ "VNSigAllNodes" SG_ 2158903296 ODDMA_FUCID 1;
BA_ "GenSigSendType" SG_ 2158903296 ODDMA_DispMID 10;
BA_ "VNSigInfotainment" SG_ 2158903296 ODDMA_DispMID 1;
BA_ "SignalType" SG_ 2158903296 ODDMA_DispMID "ENM";
BA_ "PacketOrder" SG_ 2158903296 ODDMA_DispMID 7;
BA_ "SignalLongName" SG_ 2158903296 ODDMA_DispMID "Open Display Interface Dynamic Data Multi Request Auxiliary IP : Display Mask Id";
BA_ "VNSigAllNodes" SG_ 2158903296 ODDMA_DispMID 1;
BA_ "GenSigSendType" SG_ 2158903296 ODDMA_DataID2Vld 10;
BA_ "VNSigInfotainment" SG_ 2158903296 ODDMA_DataID2Vld 1;
BA_ "SignalType" SG_ 2158903296 ODDMA_DataID2Vld "BLN";
BA_ "PacketOrder" SG_ 2158903296 ODDMA_DataID2Vld 5;
BA_ "SignalLongName" SG_ 2158903296 ODDMA_DataID2Vld "Open Display Interface Dynamic Data Multi Request Auxiliary IP : Data ID Two Valid";
BA_ "VNSigAllNodes" SG_ 2158903296 ODDMA_DataID2Vld 1;
BA_ "GenSigDeltaValue" SG_ 2158903296 ODDMA_DataID2 1;
BA_ "GenSigSendType" SG_ 2158903296 ODDMA_DataID2 12;
BA_ "VNSigInfotainment" SG_ 2158903296 ODDMA_DataID2 1;
BA_ "SignalType" SG_ 2158903296 ODDMA_DataID2 "UNM";
BA_ "PacketOrder" SG_ 2158903296 ODDMA_DataID2 9;
BA_ "SignalLongName" SG_ 2158903296 ODDMA_DataID2 "Open Display Interface Dynamic Data Multi Request Auxiliary IP : Data ID Two";
BA_ "VNSigAllNodes" SG_ 2158903296 ODDMA_DataID2 1;
BA_ "GenSigSendType" SG_ 2158903296 ODDMA_DataID3Vld 10;
BA_ "VNSigInfotainment" SG_ 2158903296 ODDMA_DataID3Vld 1;
BA_ "SignalType" SG_ 2158903296 ODDMA_DataID3Vld "BLN";
BA_ "PacketOrder" SG_ 2158903296 ODDMA_DataID3Vld 4;
BA_ "SignalLongName" SG_ 2158903296 ODDMA_DataID3Vld "Open Display Interface Dynamic Data Multi Request Auxiliary IP : Data ID Three Valid";
BA_ "VNSigAllNodes" SG_ 2158903296 ODDMA_DataID3Vld 1;
BA_ "GenSigSendType" SG_ 2158903296 ODDMA_DataID3 12;
BA_ "VNSigInfotainment" SG_ 2158903296 ODDMA_DataID3 1;
BA_ "SignalType" SG_ 2158903296 ODDMA_DataID3 "UNM";
BA_ "PacketOrder" SG_ 2158903296 ODDMA_DataID3 10;
BA_ "SignalLongName" SG_ 2158903296 ODDMA_DataID3 "Open Display Interface Dynamic Data Multi Request Auxiliary IP : Data ID Three";
BA_ "VNSigAllNodes" SG_ 2158903296 ODDMA_DataID3 1;
BA_ "GenSigSendType" SG_ 2158903296 ODDMA_DataID1 12;
BA_ "VNSigInfotainment" SG_ 2158903296 ODDMA_DataID1 1;
BA_ "SignalType" SG_ 2158903296 ODDMA_DataID1 "UNM";
BA_ "PacketOrder" SG_ 2158903296 ODDMA_DataID1 8;
BA_ "SignalLongName" SG_ 2158903296 ODDMA_DataID1 "Open Display Interface Dynamic Data Multi Request Auxiliary IP : Data ID One";
BA_ "VNSigAllNodes" SG_ 2158903296 ODDMA_DataID1 1;
BA_ "GenSigSendType" SG_ 2158903296 ODDMA_DataID4Vld 10;
BA_ "VNSigInfotainment" SG_ 2158903296 ODDMA_DataID4Vld 1;
BA_ "SignalType" SG_ 2158903296 ODDMA_DataID4Vld "BLN";
BA_ "PacketOrder" SG_ 2158903296 ODDMA_DataID4Vld 3;
BA_ "SignalLongName" SG_ 2158903296 ODDMA_DataID4Vld "Open Display Interface Dynamic Data Multi Request Auxiliary IP : Data ID Four Valid";
BA_ "VNSigAllNodes" SG_ 2158903296 ODDMA_DataID4Vld 1;
BA_ "GenSigDeltaValue" SG_ 2158903296 ODDMA_DataID4 1;
BA_ "GenSigSendType" SG_ 2158903296 ODDMA_DataID4 12;
BA_ "VNSigInfotainment" SG_ 2158903296 ODDMA_DataID4 1;
BA_ "SignalType" SG_ 2158903296 ODDMA_DataID4 "UNM";
BA_ "PacketOrder" SG_ 2158903296 ODDMA_DataID4 11;
BA_ "SignalLongName" SG_ 2158903296 ODDMA_DataID4 "Open Display Interface Dynamic Data Multi Request Auxiliary IP : Data ID Four";
BA_ "VNSigAllNodes" SG_ 2158903296 ODDMA_DataID4 1;
BA_ "GenSigSendType" SG_ 2158903296 ODDMA_DataID5Vld 10;
BA_ "VNSigInfotainment" SG_ 2158903296 ODDMA_DataID5Vld 1;
BA_ "SignalType" SG_ 2158903296 ODDMA_DataID5Vld "BLN";
BA_ "PacketOrder" SG_ 2158903296 ODDMA_DataID5Vld 2;
BA_ "SignalLongName" SG_ 2158903296 ODDMA_DataID5Vld "Open Display Interface Dynamic Data Multi Request Auxiliary IP : Data ID Five Valid";
BA_ "VNSigAllNodes" SG_ 2158903296 ODDMA_DataID5Vld 1;
BA_ "GenSigDeltaValue" SG_ 2158903296 ODDMA_DataID5 1;
BA_ "GenSigSendType" SG_ 2158903296 ODDMA_DataID5 12;
BA_ "VNSigInfotainment" SG_ 2158903296 ODDMA_DataID5 1;
BA_ "SignalType" SG_ 2158903296 ODDMA_DataID5 "UNM";
BA_ "PacketOrder" SG_ 2158903296 ODDMA_DataID5 12;
BA_ "SignalLongName" SG_ 2158903296 ODDMA_DataID5 "Open Display Interface Dynamic Data Multi Request Auxiliary IP : Data ID Five";
BA_ "VNSigAllNodes" SG_ 2158903296 ODDMA_DataID5 1;
BA_ "GenSigDeltaValue" SG_ 2158870528 ODDLA_SubIdReqM 1;
BA_ "GenSigSendType" SG_ 2158870528 ODDLA_SubIdReqM 12;
BA_ "VNSigInfotainment" SG_ 2158870528 ODDLA_SubIdReqM 1;
BA_ "SignalType" SG_ 2158870528 ODDLA_SubIdReqM "UNM";
BA_ "PacketOrder" SG_ 2158870528 ODDLA_SubIdReqM 10;
BA_ "SignalLongName" SG_ 2158870528 ODDLA_SubIdReqM "Open Display Interface Dynamic Data List Request Auxiliary IP : Sub Id Request Mask";
BA_ "VNSigAllNodes" SG_ 2158870528 ODDLA_SubIdReqM 1;
BA_ "GenSigSendType" SG_ 2158870528 ODDLA_WrpArnd 10;
BA_ "VNSigInfotainment" SG_ 2158870528 ODDLA_WrpArnd 1;
BA_ "SignalType" SG_ 2158870528 ODDLA_WrpArnd "BLN";
BA_ "PacketOrder" SG_ 2158870528 ODDLA_WrpArnd 9;
BA_ "SignalLongName" SG_ 2158870528 ODDLA_WrpArnd "Open Display Interface Dynamic Data List Request Auxiliary IP : Wrap Around";
BA_ "VNSigAllNodes" SG_ 2158870528 ODDLA_WrpArnd 1;
BA_ "GenSigSendType" SG_ 2158870528 ODDLA_ReqType 10;
BA_ "VNSigInfotainment" SG_ 2158870528 ODDLA_ReqType 1;
BA_ "SignalType" SG_ 2158870528 ODDLA_ReqType "ENM";
BA_ "PacketOrder" SG_ 2158870528 ODDLA_ReqType 7;
BA_ "SignalLongName" SG_ 2158870528 ODDLA_ReqType "Open Display Interface Dynamic Data List Request Auxiliary IP : Request Type";
BA_ "VNSigAllNodes" SG_ 2158870528 ODDLA_ReqType 1;
BA_ "GenSigSendType" SG_ 2158870528 ODDLA_ReqDir 10;
BA_ "VNSigInfotainment" SG_ 2158870528 ODDLA_ReqDir 1;
BA_ "SignalType" SG_ 2158870528 ODDLA_ReqDir "BLN";
BA_ "PacketOrder" SG_ 2158870528 ODDLA_ReqDir 5;
BA_ "SignalLongName" SG_ 2158870528 ODDLA_ReqDir "Open Display Interface Dynamic Data List Request Auxiliary IP : Req Direction";
BA_ "VNSigAllNodes" SG_ 2158870528 ODDLA_ReqDir 1;
BA_ "GenSigDeltaValue" SG_ 2158870528 ODDLA_NmEntries 1;
BA_ "GenSigSendType" SG_ 2158870528 ODDLA_NmEntries 12;
BA_ "VNSigInfotainment" SG_ 2158870528 ODDLA_NmEntries 1;
BA_ "SignalType" SG_ 2158870528 ODDLA_NmEntries "UNM";
BA_ "PacketOrder" SG_ 2158870528 ODDLA_NmEntries 4;
BA_ "SignalLongName" SG_ 2158870528 ODDLA_NmEntries "Open Display Interface Dynamic Data List Request Auxiliary IP : Num Entries";
BA_ "VNSigAllNodes" SG_ 2158870528 ODDLA_NmEntries 1;
BA_ "GenSigDeltaValue" SG_ 2158870528 ODDLA_Idx 1;
BA_ "GenSigSendType" SG_ 2158870528 ODDLA_Idx 12;
BA_ "VNSigInfotainment" SG_ 2158870528 ODDLA_Idx 1;
BA_ "SignalType" SG_ 2158870528 ODDLA_Idx "UNM";
BA_ "PacketOrder" SG_ 2158870528 ODDLA_Idx 6;
BA_ "SignalLongName" SG_ 2158870528 ODDLA_Idx "Open Display Interface Dynamic Data List Request Auxiliary IP : Index";
BA_ "VNSigAllNodes" SG_ 2158870528 ODDLA_Idx 1;
BA_ "GenSigDeltaValue" SG_ 2158870528 ODDLA_FUCID 1;
BA_ "GenSigSendType" SG_ 2158870528 ODDLA_FUCID 12;
BA_ "VNSigInfotainment" SG_ 2158870528 ODDLA_FUCID 1;
BA_ "SignalType" SG_ 2158870528 ODDLA_FUCID "UNM";
BA_ "PacketOrder" SG_ 2158870528 ODDLA_FUCID 1;
BA_ "SignalLongName" SG_ 2158870528 ODDLA_FUCID "Open Display Interface Dynamic Data List Request Auxiliary IP : Functional Unit Class ID";
BA_ "VNSigAllNodes" SG_ 2158870528 ODDLA_FUCID 1;
BA_ "GenSigSendType" SG_ 2158870528 ODDLA_DspMID 10;
BA_ "VNSigInfotainment" SG_ 2158870528 ODDLA_DspMID 1;
BA_ "SignalType" SG_ 2158870528 ODDLA_DspMID "ENM";
BA_ "PacketOrder" SG_ 2158870528 ODDLA_DspMID 3;
BA_ "SignalLongName" SG_ 2158870528 ODDLA_DspMID "Open Display Interface Dynamic Data List Request Auxiliary IP : Display Mask Id";
BA_ "VNSigAllNodes" SG_ 2158870528 ODDLA_DspMID 1;
BA_ "GenSigDeltaValue" SG_ 2158870528 ODDLA_DataId 1;
BA_ "GenSigSendType" SG_ 2158870528 ODDLA_DataId 12;
BA_ "VNSigInfotainment" SG_ 2158870528 ODDLA_DataId 1;
BA_ "SignalType" SG_ 2158870528 ODDLA_DataId "UNM";
BA_ "PacketOrder" SG_ 2158870528 ODDLA_DataId 2;
BA_ "SignalLongName" SG_ 2158870528 ODDLA_DataId "Open Display Interface Dynamic Data List Request Auxiliary IP : Data Id";
BA_ "VNSigAllNodes" SG_ 2158870528 ODDLA_DataId 1;
BA_ "GenSigSendType" SG_ 2158870528 ODDLA_BckgndFlag 10;
BA_ "VNSigInfotainment" SG_ 2158870528 ODDLA_BckgndFlag 1;
BA_ "SignalType" SG_ 2158870528 ODDLA_BckgndFlag "ENM";
BA_ "PacketOrder" SG_ 2158870528 ODDLA_BckgndFlag 8;
BA_ "SignalLongName" SG_ 2158870528 ODDLA_BckgndFlag "Open Display Interface Dynamic Data List Request Auxiliary IP : Background Flag";
BA_ "VNSigAllNodes" SG_ 2158870528 ODDLA_BckgndFlag 1;
BA_ "GenSigDeltaValue" SG_ 2158837760 ODIAA_FUCID 1;
BA_ "GenSigSendType" SG_ 2158837760 ODIAA_FUCID 12;
BA_ "VNSigInfotainment" SG_ 2158837760 ODIAA_FUCID 1;
BA_ "SignalType" SG_ 2158837760 ODIAA_FUCID "UNM";
BA_ "PacketOrder" SG_ 2158837760 ODIAA_FUCID 2;
BA_ "SignalLongName" SG_ 2158837760 ODIAA_FUCID "Open Display Interface Action Auxiliary IP : FU Class ID";
BA_ "VNSigAllNodes" SG_ 2158837760 ODIAA_FUCID 1;
BA_ "GenSigSendType" SG_ 2158837760 ODIAA_DspMID 10;
BA_ "VNSigInfotainment" SG_ 2158837760 ODIAA_DspMID 1;
BA_ "SignalType" SG_ 2158837760 ODIAA_DspMID "ENM";
BA_ "PacketOrder" SG_ 2158837760 ODIAA_DspMID 4;
BA_ "SignalLongName" SG_ 2158837760 ODIAA_DspMID "Open Display Interface Action Auxiliary IP : Display Mask ID";
BA_ "VNSigAllNodes" SG_ 2158837760 ODIAA_DspMID 1;
BA_ "GenSigDeltaValue" SG_ 2158837760 ODIAA_ActnVal 1;
BA_ "GenSigSendType" SG_ 2158837760 ODIAA_ActnVal 12;
BA_ "VNSigInfotainment" SG_ 2158837760 ODIAA_ActnVal 1;
BA_ "SignalType" SG_ 2158837760 ODIAA_ActnVal "UNM";
BA_ "PacketOrder" SG_ 2158837760 ODIAA_ActnVal 5;
BA_ "SignalLongName" SG_ 2158837760 ODIAA_ActnVal "Open Display Interface Action Auxiliary IP : Action Value";
BA_ "VNSigAllNodes" SG_ 2158837760 ODIAA_ActnVal 1;
BA_ "GenSigDeltaValue" SG_ 2158837760 ODIAA_ActnID 1;
BA_ "GenSigSendType" SG_ 2158837760 ODIAA_ActnID 12;
BA_ "VNSigInfotainment" SG_ 2158837760 ODIAA_ActnID 1;
BA_ "SignalType" SG_ 2158837760 ODIAA_ActnID "UNM";
BA_ "PacketOrder" SG_ 2158837760 ODIAA_ActnID 3;
BA_ "SignalLongName" SG_ 2158837760 ODIAA_ActnID "Open Display Interface Action Auxiliary IP : Action ID";
BA_ "VNSigAllNodes" SG_ 2158837760 ODIAA_ActnID 1;
BA_ "GenSigSendType" SG_ 2158837760 ODIAA_DaTy 10;
BA_ "VNSigInfotainment" SG_ 2158837760 ODIAA_DaTy 1;
BA_ "SignalType" SG_ 2158837760 ODIAA_DaTy "ENM";
BA_ "PacketOrder" SG_ 2158837760 ODIAA_DaTy 1;
BA_ "SignalLongName" SG_ 2158837760 ODIAA_DaTy "Open Display Interface Action Auxiliary IP : DataType";
BA_ "VNSigAllNodes" SG_ 2158837760 ODIAA_DaTy 1;
BA_ "GenSigSendType" SG_ 2158796800 ODII_ODIInd55 10;
BA_ "GenSigSendOnInit" SG_ 2158796800 ODII_ODIInd55 1;
BA_ "VNSigInfotainment" SG_ 2158796800 ODII_ODIInd55 1;
BA_ "SignalType" SG_ 2158796800 ODII_ODIInd55 "BLN";
BA_ "PacketOrder" SG_ 2158796800 ODII_ODIInd55 56;
BA_ "SignalLongName" SG_ 2158796800 ODII_ODIInd55 "Open Display Interface Indication : Open Display Interface Indication 55";
BA_ "VNSigAllNodes" SG_ 2158796800 ODII_ODIInd55 1;
BA_ "GenSigSendType" SG_ 2158796800 ODII_ODIInd54 10;
BA_ "GenSigSendOnInit" SG_ 2158796800 ODII_ODIInd54 1;
BA_ "VNSigInfotainment" SG_ 2158796800 ODII_ODIInd54 1;
BA_ "SignalType" SG_ 2158796800 ODII_ODIInd54 "BLN";
BA_ "PacketOrder" SG_ 2158796800 ODII_ODIInd54 55;
BA_ "SignalLongName" SG_ 2158796800 ODII_ODIInd54 "Open Display Interface Indication : Open Display Interface Indication 54";
BA_ "VNSigAllNodes" SG_ 2158796800 ODII_ODIInd54 1;
BA_ "GenSigSendType" SG_ 2158796800 ODII_ODIInd53 10;
BA_ "GenSigSendOnInit" SG_ 2158796800 ODII_ODIInd53 1;
BA_ "VNSigInfotainment" SG_ 2158796800 ODII_ODIInd53 1;
BA_ "SignalType" SG_ 2158796800 ODII_ODIInd53 "BLN";
BA_ "PacketOrder" SG_ 2158796800 ODII_ODIInd53 54;
BA_ "SignalLongName" SG_ 2158796800 ODII_ODIInd53 "Open Display Interface Indication : Open Display Interface Indication 53";
BA_ "VNSigAllNodes" SG_ 2158796800 ODII_ODIInd53 1;
BA_ "GenSigSendType" SG_ 2158796800 ODII_ODIInd52 10;
BA_ "GenSigSendOnInit" SG_ 2158796800 ODII_ODIInd52 1;
BA_ "VNSigInfotainment" SG_ 2158796800 ODII_ODIInd52 1;
BA_ "SignalType" SG_ 2158796800 ODII_ODIInd52 "BLN";
BA_ "PacketOrder" SG_ 2158796800 ODII_ODIInd52 53;
BA_ "SignalLongName" SG_ 2158796800 ODII_ODIInd52 "Open Display Interface Indication : Open Display Interface Indication 52";
BA_ "VNSigAllNodes" SG_ 2158796800 ODII_ODIInd52 1;
BA_ "GenSigSendType" SG_ 2158796800 ODII_ODIInd51 10;
BA_ "GenSigSendOnInit" SG_ 2158796800 ODII_ODIInd51 1;
BA_ "VNSigInfotainment" SG_ 2158796800 ODII_ODIInd51 1;
BA_ "SignalType" SG_ 2158796800 ODII_ODIInd51 "BLN";
BA_ "PacketOrder" SG_ 2158796800 ODII_ODIInd51 52;
BA_ "SignalLongName" SG_ 2158796800 ODII_ODIInd51 "Open Display Interface Indication : Open Display Interface Indication 51";
BA_ "VNSigAllNodes" SG_ 2158796800 ODII_ODIInd51 1;
BA_ "GenSigSendType" SG_ 2158796800 ODII_ODIInd50 10;
BA_ "GenSigSendOnInit" SG_ 2158796800 ODII_ODIInd50 1;
BA_ "VNSigInfotainment" SG_ 2158796800 ODII_ODIInd50 1;
BA_ "SignalType" SG_ 2158796800 ODII_ODIInd50 "BLN";
BA_ "PacketOrder" SG_ 2158796800 ODII_ODIInd50 51;
BA_ "SignalLongName" SG_ 2158796800 ODII_ODIInd50 "Open Display Interface Indication : Open Display Interface Indication 50";
BA_ "VNSigAllNodes" SG_ 2158796800 ODII_ODIInd50 1;
BA_ "GenSigSendType" SG_ 2158796800 ODII_ODIInd27 10;
BA_ "GenSigSendOnInit" SG_ 2158796800 ODII_ODIInd27 1;
BA_ "VNSigInfotainment" SG_ 2158796800 ODII_ODIInd27 1;
BA_ "SignalType" SG_ 2158796800 ODII_ODIInd27 "BLN";
BA_ "PacketOrder" SG_ 2158796800 ODII_ODIInd27 28;
BA_ "SignalLongName" SG_ 2158796800 ODII_ODIInd27 "Open Display Interface Indication : Open Display Interface Indication 27";
BA_ "VNSigAllNodes" SG_ 2158796800 ODII_ODIInd27 1;
BA_ "GenSigSendType" SG_ 2158796800 ODII_ODIInd26 10;
BA_ "GenSigSendOnInit" SG_ 2158796800 ODII_ODIInd26 1;
BA_ "VNSigInfotainment" SG_ 2158796800 ODII_ODIInd26 1;
BA_ "SignalType" SG_ 2158796800 ODII_ODIInd26 "BLN";
BA_ "PacketOrder" SG_ 2158796800 ODII_ODIInd26 27;
BA_ "SignalLongName" SG_ 2158796800 ODII_ODIInd26 "Open Display Interface Indication : Open Display Interface Indication 26";
BA_ "VNSigAllNodes" SG_ 2158796800 ODII_ODIInd26 1;
BA_ "GenSigSendType" SG_ 2158796800 ODII_ODIInd25 10;
BA_ "GenSigSendOnInit" SG_ 2158796800 ODII_ODIInd25 1;
BA_ "VNSigInfotainment" SG_ 2158796800 ODII_ODIInd25 1;
BA_ "SignalType" SG_ 2158796800 ODII_ODIInd25 "BLN";
BA_ "PacketOrder" SG_ 2158796800 ODII_ODIInd25 26;
BA_ "SignalLongName" SG_ 2158796800 ODII_ODIInd25 "Open Display Interface Indication : Open Display Interface Indication 25";
BA_ "VNSigAllNodes" SG_ 2158796800 ODII_ODIInd25 1;
BA_ "GenSigSendType" SG_ 2158796800 ODII_ODIInd24 10;
BA_ "GenSigSendOnInit" SG_ 2158796800 ODII_ODIInd24 1;
BA_ "VNSigInfotainment" SG_ 2158796800 ODII_ODIInd24 1;
BA_ "SignalType" SG_ 2158796800 ODII_ODIInd24 "BLN";
BA_ "PacketOrder" SG_ 2158796800 ODII_ODIInd24 25;
BA_ "SignalLongName" SG_ 2158796800 ODII_ODIInd24 "Open Display Interface Indication : Open Display Interface Indication 24";
BA_ "VNSigAllNodes" SG_ 2158796800 ODII_ODIInd24 1;
BA_ "GenSigSendType" SG_ 2158796800 ODII_ODIInd23 10;
BA_ "GenSigSendOnInit" SG_ 2158796800 ODII_ODIInd23 1;
BA_ "VNSigInfotainment" SG_ 2158796800 ODII_ODIInd23 1;
BA_ "SignalType" SG_ 2158796800 ODII_ODIInd23 "BLN";
BA_ "PacketOrder" SG_ 2158796800 ODII_ODIInd23 24;
BA_ "SignalLongName" SG_ 2158796800 ODII_ODIInd23 "Open Display Interface Indication : Open Display Interface Indication 23";
BA_ "VNSigAllNodes" SG_ 2158796800 ODII_ODIInd23 1;
BA_ "GenSigSendType" SG_ 2158796800 ODII_ODIInd22 10;
BA_ "GenSigSendOnInit" SG_ 2158796800 ODII_ODIInd22 1;
BA_ "VNSigInfotainment" SG_ 2158796800 ODII_ODIInd22 1;
BA_ "SignalType" SG_ 2158796800 ODII_ODIInd22 "BLN";
BA_ "PacketOrder" SG_ 2158796800 ODII_ODIInd22 23;
BA_ "SignalLongName" SG_ 2158796800 ODII_ODIInd22 "Open Display Interface Indication : Open Display Interface Indication 22";
BA_ "VNSigAllNodes" SG_ 2158796800 ODII_ODIInd22 1;
BA_ "GenSigSendType" SG_ 2158796800 ODII_ODIInd21 10;
BA_ "GenSigSendOnInit" SG_ 2158796800 ODII_ODIInd21 1;
BA_ "VNSigInfotainment" SG_ 2158796800 ODII_ODIInd21 1;
BA_ "SignalType" SG_ 2158796800 ODII_ODIInd21 "BLN";
BA_ "PacketOrder" SG_ 2158796800 ODII_ODIInd21 22;
BA_ "SignalLongName" SG_ 2158796800 ODII_ODIInd21 "Open Display Interface Indication : Open Display Interface Indication 21";
BA_ "VNSigAllNodes" SG_ 2158796800 ODII_ODIInd21 1;
BA_ "GenSigSendType" SG_ 2158796800 ODII_ODIInd20 10;
BA_ "GenSigSendOnInit" SG_ 2158796800 ODII_ODIInd20 1;
BA_ "VNSigInfotainment" SG_ 2158796800 ODII_ODIInd20 1;
BA_ "SignalType" SG_ 2158796800 ODII_ODIInd20 "BLN";
BA_ "PacketOrder" SG_ 2158796800 ODII_ODIInd20 21;
BA_ "SignalLongName" SG_ 2158796800 ODII_ODIInd20 "Open Display Interface Indication : Open Display Interface Indication 20";
BA_ "VNSigAllNodes" SG_ 2158796800 ODII_ODIInd20 1;
BA_ "GenSigSendType" SG_ 2158796800 ODII_ODIInd19 10;
BA_ "GenSigSendOnInit" SG_ 2158796800 ODII_ODIInd19 1;
BA_ "VNSigInfotainment" SG_ 2158796800 ODII_ODIInd19 1;
BA_ "SignalType" SG_ 2158796800 ODII_ODIInd19 "BLN";
BA_ "PacketOrder" SG_ 2158796800 ODII_ODIInd19 20;
BA_ "SignalLongName" SG_ 2158796800 ODII_ODIInd19 "Open Display Interface Indication : Open Display Interface Indication 19";
BA_ "VNSigAllNodes" SG_ 2158796800 ODII_ODIInd19 1;
BA_ "GenSigSendType" SG_ 2158796800 ODII_ODIInd18 10;
BA_ "GenSigSendOnInit" SG_ 2158796800 ODII_ODIInd18 1;
BA_ "VNSigInfotainment" SG_ 2158796800 ODII_ODIInd18 1;
BA_ "SignalType" SG_ 2158796800 ODII_ODIInd18 "BLN";
BA_ "PacketOrder" SG_ 2158796800 ODII_ODIInd18 19;
BA_ "SignalLongName" SG_ 2158796800 ODII_ODIInd18 "Open Display Interface Indication : Open Display Interface Indication 18";
BA_ "VNSigAllNodes" SG_ 2158796800 ODII_ODIInd18 1;
BA_ "GenSigSendType" SG_ 2158796800 ODII_ODIInd17 10;
BA_ "GenSigSendOnInit" SG_ 2158796800 ODII_ODIInd17 1;
BA_ "VNSigInfotainment" SG_ 2158796800 ODII_ODIInd17 1;
BA_ "SignalType" SG_ 2158796800 ODII_ODIInd17 "BLN";
BA_ "PacketOrder" SG_ 2158796800 ODII_ODIInd17 18;
BA_ "SignalLongName" SG_ 2158796800 ODII_ODIInd17 "Open Display Interface Indication : Open Display Interface Indication 17";
BA_ "VNSigAllNodes" SG_ 2158796800 ODII_ODIInd17 1;
BA_ "GenSigSendType" SG_ 2158796800 ODII_ODIInd16 10;
BA_ "GenSigSendOnInit" SG_ 2158796800 ODII_ODIInd16 1;
BA_ "VNSigInfotainment" SG_ 2158796800 ODII_ODIInd16 1;
BA_ "SignalType" SG_ 2158796800 ODII_ODIInd16 "BLN";
BA_ "PacketOrder" SG_ 2158796800 ODII_ODIInd16 17;
BA_ "SignalLongName" SG_ 2158796800 ODII_ODIInd16 "Open Display Interface Indication : Open Display Interface Indication 16";
BA_ "VNSigAllNodes" SG_ 2158796800 ODII_ODIInd16 1;
BA_ "GenSigSendType" SG_ 2158796800 ODII_ODIInd15 10;
BA_ "GenSigSendOnInit" SG_ 2158796800 ODII_ODIInd15 1;
BA_ "VNSigInfotainment" SG_ 2158796800 ODII_ODIInd15 1;
BA_ "SignalType" SG_ 2158796800 ODII_ODIInd15 "BLN";
BA_ "PacketOrder" SG_ 2158796800 ODII_ODIInd15 16;
BA_ "SignalLongName" SG_ 2158796800 ODII_ODIInd15 "Open Display Interface Indication : Open Display Interface Indication 15";
BA_ "VNSigAllNodes" SG_ 2158796800 ODII_ODIInd15 1;
BA_ "GenSigSendType" SG_ 2158796800 ODII_ODIInd14 10;
BA_ "GenSigSendOnInit" SG_ 2158796800 ODII_ODIInd14 1;
BA_ "VNSigInfotainment" SG_ 2158796800 ODII_ODIInd14 1;
BA_ "SignalType" SG_ 2158796800 ODII_ODIInd14 "BLN";
BA_ "PacketOrder" SG_ 2158796800 ODII_ODIInd14 15;
BA_ "SignalLongName" SG_ 2158796800 ODII_ODIInd14 "Open Display Interface Indication : Open Display Interface Indication 14";
BA_ "VNSigAllNodes" SG_ 2158796800 ODII_ODIInd14 1;
BA_ "GenSigSendType" SG_ 2158796800 ODII_ODIInd13 10;
BA_ "GenSigSendOnInit" SG_ 2158796800 ODII_ODIInd13 1;
BA_ "VNSigInfotainment" SG_ 2158796800 ODII_ODIInd13 1;
BA_ "SignalType" SG_ 2158796800 ODII_ODIInd13 "BLN";
BA_ "PacketOrder" SG_ 2158796800 ODII_ODIInd13 14;
BA_ "SignalLongName" SG_ 2158796800 ODII_ODIInd13 "Open Display Interface Indication : Open Display Interface Indication 13";
BA_ "VNSigAllNodes" SG_ 2158796800 ODII_ODIInd13 1;
BA_ "GenSigSendType" SG_ 2158796800 ODII_ODIInd12 10;
BA_ "GenSigSendOnInit" SG_ 2158796800 ODII_ODIInd12 1;
BA_ "VNSigInfotainment" SG_ 2158796800 ODII_ODIInd12 1;
BA_ "SignalType" SG_ 2158796800 ODII_ODIInd12 "BLN";
BA_ "PacketOrder" SG_ 2158796800 ODII_ODIInd12 13;
BA_ "SignalLongName" SG_ 2158796800 ODII_ODIInd12 "Open Display Interface Indication : Open Display Interface Indication 12";
BA_ "VNSigAllNodes" SG_ 2158796800 ODII_ODIInd12 1;
BA_ "GenSigSendType" SG_ 2158796800 ODII_ODIInd11 10;
BA_ "GenSigSendOnInit" SG_ 2158796800 ODII_ODIInd11 1;
BA_ "VNSigInfotainment" SG_ 2158796800 ODII_ODIInd11 1;
BA_ "SignalType" SG_ 2158796800 ODII_ODIInd11 "BLN";
BA_ "PacketOrder" SG_ 2158796800 ODII_ODIInd11 12;
BA_ "SignalLongName" SG_ 2158796800 ODII_ODIInd11 "Open Display Interface Indication : Open Display Interface Indication 11";
BA_ "VNSigAllNodes" SG_ 2158796800 ODII_ODIInd11 1;
BA_ "GenSigSendType" SG_ 2158796800 ODII_ODIInd10 10;
BA_ "GenSigSendOnInit" SG_ 2158796800 ODII_ODIInd10 1;
BA_ "VNSigInfotainment" SG_ 2158796800 ODII_ODIInd10 1;
BA_ "SignalType" SG_ 2158796800 ODII_ODIInd10 "BLN";
BA_ "PacketOrder" SG_ 2158796800 ODII_ODIInd10 11;
BA_ "SignalLongName" SG_ 2158796800 ODII_ODIInd10 "Open Display Interface Indication : Open Display Interface Indication 10";
BA_ "VNSigAllNodes" SG_ 2158796800 ODII_ODIInd10 1;
BA_ "GenSigSendType" SG_ 2158796800 ODII_ODIInd9 10;
BA_ "GenSigSendOnInit" SG_ 2158796800 ODII_ODIInd9 1;
BA_ "VNSigInfotainment" SG_ 2158796800 ODII_ODIInd9 1;
BA_ "SignalType" SG_ 2158796800 ODII_ODIInd9 "BLN";
BA_ "PacketOrder" SG_ 2158796800 ODII_ODIInd9 10;
BA_ "SignalLongName" SG_ 2158796800 ODII_ODIInd9 "Open Display Interface Indication : Open Display Interface Indication 9";
BA_ "VNSigAllNodes" SG_ 2158796800 ODII_ODIInd9 1;
BA_ "GenSigSendType" SG_ 2158796800 ODII_ODIInd8 10;
BA_ "GenSigSendOnInit" SG_ 2158796800 ODII_ODIInd8 1;
BA_ "VNSigInfotainment" SG_ 2158796800 ODII_ODIInd8 1;
BA_ "SignalType" SG_ 2158796800 ODII_ODIInd8 "BLN";
BA_ "PacketOrder" SG_ 2158796800 ODII_ODIInd8 9;
BA_ "SignalLongName" SG_ 2158796800 ODII_ODIInd8 "Open Display Interface Indication : Open Display Interface Indication 8";
BA_ "VNSigAllNodes" SG_ 2158796800 ODII_ODIInd8 1;
BA_ "GenSigSendType" SG_ 2158796800 ODII_ODIInd7 10;
BA_ "GenSigSendOnInit" SG_ 2158796800 ODII_ODIInd7 1;
BA_ "VNSigInfotainment" SG_ 2158796800 ODII_ODIInd7 1;
BA_ "SignalType" SG_ 2158796800 ODII_ODIInd7 "BLN";
BA_ "PacketOrder" SG_ 2158796800 ODII_ODIInd7 8;
BA_ "SignalLongName" SG_ 2158796800 ODII_ODIInd7 "Open Display Interface Indication : Open Display Interface Indication 7";
BA_ "VNSigAllNodes" SG_ 2158796800 ODII_ODIInd7 1;
BA_ "GenSigSendType" SG_ 2158796800 ODII_ODIInd6 10;
BA_ "GenSigSendOnInit" SG_ 2158796800 ODII_ODIInd6 1;
BA_ "VNSigInfotainment" SG_ 2158796800 ODII_ODIInd6 1;
BA_ "SignalType" SG_ 2158796800 ODII_ODIInd6 "BLN";
BA_ "PacketOrder" SG_ 2158796800 ODII_ODIInd6 7;
BA_ "SignalLongName" SG_ 2158796800 ODII_ODIInd6 "Open Display Interface Indication : Open Display Interface Indication 6";
BA_ "VNSigAllNodes" SG_ 2158796800 ODII_ODIInd6 1;
BA_ "GenSigSendType" SG_ 2158796800 ODII_ODIInd5 10;
BA_ "GenSigSendOnInit" SG_ 2158796800 ODII_ODIInd5 1;
BA_ "VNSigInfotainment" SG_ 2158796800 ODII_ODIInd5 1;
BA_ "SignalType" SG_ 2158796800 ODII_ODIInd5 "BLN";
BA_ "PacketOrder" SG_ 2158796800 ODII_ODIInd5 6;
BA_ "SignalLongName" SG_ 2158796800 ODII_ODIInd5 "Open Display Interface Indication : Open Display Interface Indication 5";
BA_ "VNSigAllNodes" SG_ 2158796800 ODII_ODIInd5 1;
BA_ "GenSigSendType" SG_ 2158796800 ODII_ODIInd4 10;
BA_ "GenSigSendOnInit" SG_ 2158796800 ODII_ODIInd4 1;
BA_ "VNSigInfotainment" SG_ 2158796800 ODII_ODIInd4 1;
BA_ "SignalType" SG_ 2158796800 ODII_ODIInd4 "BLN";
BA_ "PacketOrder" SG_ 2158796800 ODII_ODIInd4 5;
BA_ "SignalLongName" SG_ 2158796800 ODII_ODIInd4 "Open Display Interface Indication : Open Display Interface Indication 4";
BA_ "VNSigAllNodes" SG_ 2158796800 ODII_ODIInd4 1;
BA_ "GenSigSendType" SG_ 2158796800 ODII_ODIInd3 10;
BA_ "GenSigSendOnInit" SG_ 2158796800 ODII_ODIInd3 1;
BA_ "VNSigInfotainment" SG_ 2158796800 ODII_ODIInd3 1;
BA_ "SignalType" SG_ 2158796800 ODII_ODIInd3 "BLN";
BA_ "PacketOrder" SG_ 2158796800 ODII_ODIInd3 4;
BA_ "SignalLongName" SG_ 2158796800 ODII_ODIInd3 "Open Display Interface Indication : Open Display Interface Indication 3";
BA_ "VNSigAllNodes" SG_ 2158796800 ODII_ODIInd3 1;
BA_ "GenSigSendType" SG_ 2158796800 ODII_ODIInd2 10;
BA_ "GenSigSendOnInit" SG_ 2158796800 ODII_ODIInd2 1;
BA_ "VNSigInfotainment" SG_ 2158796800 ODII_ODIInd2 1;
BA_ "SignalType" SG_ 2158796800 ODII_ODIInd2 "BLN";
BA_ "PacketOrder" SG_ 2158796800 ODII_ODIInd2 3;
BA_ "SignalLongName" SG_ 2158796800 ODII_ODIInd2 "Open Display Interface Indication : Open Display Interface Indication 2";
BA_ "VNSigAllNodes" SG_ 2158796800 ODII_ODIInd2 1;
BA_ "GenSigSendType" SG_ 2158796800 ODII_ODIInd1 10;
BA_ "GenSigSendOnInit" SG_ 2158796800 ODII_ODIInd1 1;
BA_ "VNSigInfotainment" SG_ 2158796800 ODII_ODIInd1 1;
BA_ "SignalType" SG_ 2158796800 ODII_ODIInd1 "BLN";
BA_ "PacketOrder" SG_ 2158796800 ODII_ODIInd1 2;
BA_ "SignalLongName" SG_ 2158796800 ODII_ODIInd1 "Open Display Interface Indication : Open Display Interface Indication 1";
BA_ "VNSigAllNodes" SG_ 2158796800 ODII_ODIInd1 1;
BA_ "GenSigSendType" SG_ 2158796800 ODII_ODIInd56 10;
BA_ "GenSigSendOnInit" SG_ 2158796800 ODII_ODIInd56 1;
BA_ "VNSigInfotainment" SG_ 2158796800 ODII_ODIInd56 1;
BA_ "SignalType" SG_ 2158796800 ODII_ODIInd56 "BLN";
BA_ "PacketOrder" SG_ 2158796800 ODII_ODIInd56 57;
BA_ "SignalLongName" SG_ 2158796800 ODII_ODIInd56 "Open Display Interface Indication : Open Display Interface Indication 56";
BA_ "VNSigAllNodes" SG_ 2158796800 ODII_ODIInd56 1;
BA_ "GenSigSendType" SG_ 2158796800 ODII_ODIInd49 10;
BA_ "GenSigSendOnInit" SG_ 2158796800 ODII_ODIInd49 1;
BA_ "VNSigInfotainment" SG_ 2158796800 ODII_ODIInd49 1;
BA_ "SignalType" SG_ 2158796800 ODII_ODIInd49 "BLN";
BA_ "PacketOrder" SG_ 2158796800 ODII_ODIInd49 50;
BA_ "SignalLongName" SG_ 2158796800 ODII_ODIInd49 "Open Display Interface Indication : Open Display Interface Indication 49";
BA_ "VNSigAllNodes" SG_ 2158796800 ODII_ODIInd49 1;
BA_ "GenSigSendType" SG_ 2158796800 ODII_ODIInd48 10;
BA_ "GenSigSendOnInit" SG_ 2158796800 ODII_ODIInd48 1;
BA_ "VNSigInfotainment" SG_ 2158796800 ODII_ODIInd48 1;
BA_ "SignalType" SG_ 2158796800 ODII_ODIInd48 "BLN";
BA_ "PacketOrder" SG_ 2158796800 ODII_ODIInd48 49;
BA_ "SignalLongName" SG_ 2158796800 ODII_ODIInd48 "Open Display Interface Indication : Open Display Interface Indication 48";
BA_ "VNSigAllNodes" SG_ 2158796800 ODII_ODIInd48 1;
BA_ "GenSigSendType" SG_ 2158796800 ODII_ODIInd47 10;
BA_ "GenSigSendOnInit" SG_ 2158796800 ODII_ODIInd47 1;
BA_ "VNSigInfotainment" SG_ 2158796800 ODII_ODIInd47 1;
BA_ "SignalType" SG_ 2158796800 ODII_ODIInd47 "BLN";
BA_ "PacketOrder" SG_ 2158796800 ODII_ODIInd47 48;
BA_ "SignalLongName" SG_ 2158796800 ODII_ODIInd47 "Open Display Interface Indication : Open Display Interface Indication 47";
BA_ "VNSigAllNodes" SG_ 2158796800 ODII_ODIInd47 1;
BA_ "GenSigSendType" SG_ 2158796800 ODII_ODIInd46 10;
BA_ "GenSigSendOnInit" SG_ 2158796800 ODII_ODIInd46 1;
BA_ "VNSigInfotainment" SG_ 2158796800 ODII_ODIInd46 1;
BA_ "SignalType" SG_ 2158796800 ODII_ODIInd46 "BLN";
BA_ "PacketOrder" SG_ 2158796800 ODII_ODIInd46 47;
BA_ "SignalLongName" SG_ 2158796800 ODII_ODIInd46 "Open Display Interface Indication : Open Display Interface Indication 46";
BA_ "VNSigAllNodes" SG_ 2158796800 ODII_ODIInd46 1;
BA_ "GenSigSendType" SG_ 2158796800 ODII_ODIInd45 10;
BA_ "GenSigSendOnInit" SG_ 2158796800 ODII_ODIInd45 1;
BA_ "VNSigInfotainment" SG_ 2158796800 ODII_ODIInd45 1;
BA_ "SignalType" SG_ 2158796800 ODII_ODIInd45 "BLN";
BA_ "PacketOrder" SG_ 2158796800 ODII_ODIInd45 46;
BA_ "SignalLongName" SG_ 2158796800 ODII_ODIInd45 "Open Display Interface Indication : Open Display Interface Indication 45";
BA_ "VNSigAllNodes" SG_ 2158796800 ODII_ODIInd45 1;
BA_ "GenSigSendType" SG_ 2158796800 ODII_ODIInd44 10;
BA_ "GenSigSendOnInit" SG_ 2158796800 ODII_ODIInd44 1;
BA_ "VNSigInfotainment" SG_ 2158796800 ODII_ODIInd44 1;
BA_ "SignalType" SG_ 2158796800 ODII_ODIInd44 "BLN";
BA_ "PacketOrder" SG_ 2158796800 ODII_ODIInd44 45;
BA_ "SignalLongName" SG_ 2158796800 ODII_ODIInd44 "Open Display Interface Indication : Open Display Interface Indication 44";
BA_ "VNSigAllNodes" SG_ 2158796800 ODII_ODIInd44 1;
BA_ "GenSigSendType" SG_ 2158796800 ODII_ODIInd43 10;
BA_ "GenSigSendOnInit" SG_ 2158796800 ODII_ODIInd43 1;
BA_ "VNSigInfotainment" SG_ 2158796800 ODII_ODIInd43 1;
BA_ "SignalType" SG_ 2158796800 ODII_ODIInd43 "BLN";
BA_ "PacketOrder" SG_ 2158796800 ODII_ODIInd43 44;
BA_ "SignalLongName" SG_ 2158796800 ODII_ODIInd43 "Open Display Interface Indication : Open Display Interface Indication 43";
BA_ "VNSigAllNodes" SG_ 2158796800 ODII_ODIInd43 1;
BA_ "GenSigSendType" SG_ 2158796800 ODII_ODIInd42 10;
BA_ "GenSigSendOnInit" SG_ 2158796800 ODII_ODIInd42 1;
BA_ "VNSigInfotainment" SG_ 2158796800 ODII_ODIInd42 1;
BA_ "SignalType" SG_ 2158796800 ODII_ODIInd42 "BLN";
BA_ "PacketOrder" SG_ 2158796800 ODII_ODIInd42 43;
BA_ "SignalLongName" SG_ 2158796800 ODII_ODIInd42 "Open Display Interface Indication : Open Display Interface Indication 42";
BA_ "VNSigAllNodes" SG_ 2158796800 ODII_ODIInd42 1;
BA_ "GenSigSendType" SG_ 2158796800 ODII_ODIInd41 10;
BA_ "GenSigSendOnInit" SG_ 2158796800 ODII_ODIInd41 1;
BA_ "VNSigInfotainment" SG_ 2158796800 ODII_ODIInd41 1;
BA_ "SignalType" SG_ 2158796800 ODII_ODIInd41 "BLN";
BA_ "PacketOrder" SG_ 2158796800 ODII_ODIInd41 42;
BA_ "SignalLongName" SG_ 2158796800 ODII_ODIInd41 "Open Display Interface Indication : Open Display Interface Indication 41";
BA_ "VNSigAllNodes" SG_ 2158796800 ODII_ODIInd41 1;
BA_ "GenSigSendType" SG_ 2158796800 ODII_ODIInd40 10;
BA_ "GenSigSendOnInit" SG_ 2158796800 ODII_ODIInd40 1;
BA_ "VNSigInfotainment" SG_ 2158796800 ODII_ODIInd40 1;
BA_ "SignalType" SG_ 2158796800 ODII_ODIInd40 "BLN";
BA_ "PacketOrder" SG_ 2158796800 ODII_ODIInd40 41;
BA_ "SignalLongName" SG_ 2158796800 ODII_ODIInd40 "Open Display Interface Indication : Open Display Interface Indication 40";
BA_ "VNSigAllNodes" SG_ 2158796800 ODII_ODIInd40 1;
BA_ "GenSigSendType" SG_ 2158796800 ODII_ODIInd39 10;
BA_ "GenSigSendOnInit" SG_ 2158796800 ODII_ODIInd39 1;
BA_ "VNSigInfotainment" SG_ 2158796800 ODII_ODIInd39 1;
BA_ "SignalType" SG_ 2158796800 ODII_ODIInd39 "BLN";
BA_ "PacketOrder" SG_ 2158796800 ODII_ODIInd39 40;
BA_ "SignalLongName" SG_ 2158796800 ODII_ODIInd39 "Open Display Interface Indication : Open Display Interface Indication 39";
BA_ "VNSigAllNodes" SG_ 2158796800 ODII_ODIInd39 1;
BA_ "GenSigSendType" SG_ 2158796800 ODII_ODIInd38 10;
BA_ "GenSigSendOnInit" SG_ 2158796800 ODII_ODIInd38 1;
BA_ "VNSigInfotainment" SG_ 2158796800 ODII_ODIInd38 1;
BA_ "SignalType" SG_ 2158796800 ODII_ODIInd38 "BLN";
BA_ "PacketOrder" SG_ 2158796800 ODII_ODIInd38 39;
BA_ "SignalLongName" SG_ 2158796800 ODII_ODIInd38 "Open Display Interface Indication : Open Display Interface Indication 38";
BA_ "VNSigAllNodes" SG_ 2158796800 ODII_ODIInd38 1;
BA_ "GenSigSendType" SG_ 2158796800 ODII_ODIInd37 10;
BA_ "GenSigSendOnInit" SG_ 2158796800 ODII_ODIInd37 1;
BA_ "VNSigInfotainment" SG_ 2158796800 ODII_ODIInd37 1;
BA_ "SignalType" SG_ 2158796800 ODII_ODIInd37 "BLN";
BA_ "PacketOrder" SG_ 2158796800 ODII_ODIInd37 38;
BA_ "SignalLongName" SG_ 2158796800 ODII_ODIInd37 "Open Display Interface Indication : Open Display Interface Indication 37";
BA_ "VNSigAllNodes" SG_ 2158796800 ODII_ODIInd37 1;
BA_ "GenSigSendType" SG_ 2158796800 ODII_ODIInd36 10;
BA_ "GenSigSendOnInit" SG_ 2158796800 ODII_ODIInd36 1;
BA_ "VNSigInfotainment" SG_ 2158796800 ODII_ODIInd36 1;
BA_ "SignalType" SG_ 2158796800 ODII_ODIInd36 "BLN";
BA_ "PacketOrder" SG_ 2158796800 ODII_ODIInd36 37;
BA_ "SignalLongName" SG_ 2158796800 ODII_ODIInd36 "Open Display Interface Indication : Open Display Interface Indication 36";
BA_ "VNSigAllNodes" SG_ 2158796800 ODII_ODIInd36 1;
BA_ "GenSigSendType" SG_ 2158796800 ODII_ODIInd35 10;
BA_ "GenSigSendOnInit" SG_ 2158796800 ODII_ODIInd35 1;
BA_ "VNSigInfotainment" SG_ 2158796800 ODII_ODIInd35 1;
BA_ "SignalType" SG_ 2158796800 ODII_ODIInd35 "BLN";
BA_ "PacketOrder" SG_ 2158796800 ODII_ODIInd35 36;
BA_ "SignalLongName" SG_ 2158796800 ODII_ODIInd35 "Open Display Interface Indication : Open Display Interface Indication 35";
BA_ "VNSigAllNodes" SG_ 2158796800 ODII_ODIInd35 1;
BA_ "GenSigSendType" SG_ 2158796800 ODII_ODIInd34 10;
BA_ "GenSigSendOnInit" SG_ 2158796800 ODII_ODIInd34 1;
BA_ "VNSigInfotainment" SG_ 2158796800 ODII_ODIInd34 1;
BA_ "SignalType" SG_ 2158796800 ODII_ODIInd34 "BLN";
BA_ "PacketOrder" SG_ 2158796800 ODII_ODIInd34 35;
BA_ "SignalLongName" SG_ 2158796800 ODII_ODIInd34 "Open Display Interface Indication : Open Display Interface Indication 34";
BA_ "VNSigAllNodes" SG_ 2158796800 ODII_ODIInd34 1;
BA_ "GenSigSendType" SG_ 2158796800 ODII_ODIInd33 10;
BA_ "GenSigSendOnInit" SG_ 2158796800 ODII_ODIInd33 1;
BA_ "VNSigInfotainment" SG_ 2158796800 ODII_ODIInd33 1;
BA_ "SignalType" SG_ 2158796800 ODII_ODIInd33 "BLN";
BA_ "PacketOrder" SG_ 2158796800 ODII_ODIInd33 34;
BA_ "SignalLongName" SG_ 2158796800 ODII_ODIInd33 "Open Display Interface Indication : Open Display Interface Indication 33";
BA_ "VNSigAllNodes" SG_ 2158796800 ODII_ODIInd33 1;
BA_ "GenSigSendType" SG_ 2158796800 ODII_ODIInd32 10;
BA_ "GenSigSendOnInit" SG_ 2158796800 ODII_ODIInd32 1;
BA_ "VNSigInfotainment" SG_ 2158796800 ODII_ODIInd32 1;
BA_ "SignalType" SG_ 2158796800 ODII_ODIInd32 "BLN";
BA_ "PacketOrder" SG_ 2158796800 ODII_ODIInd32 33;
BA_ "SignalLongName" SG_ 2158796800 ODII_ODIInd32 "Open Display Interface Indication : Open Display Interface Indication 32";
BA_ "VNSigAllNodes" SG_ 2158796800 ODII_ODIInd32 1;
BA_ "GenSigSendType" SG_ 2158796800 ODII_ODIInd31 10;
BA_ "GenSigSendOnInit" SG_ 2158796800 ODII_ODIInd31 1;
BA_ "VNSigInfotainment" SG_ 2158796800 ODII_ODIInd31 1;
BA_ "SignalType" SG_ 2158796800 ODII_ODIInd31 "BLN";
BA_ "PacketOrder" SG_ 2158796800 ODII_ODIInd31 32;
BA_ "SignalLongName" SG_ 2158796800 ODII_ODIInd31 "Open Display Interface Indication : Open Display Interface Indication 31";
BA_ "VNSigAllNodes" SG_ 2158796800 ODII_ODIInd31 1;
BA_ "GenSigSendType" SG_ 2158796800 ODII_ODIInd30 10;
BA_ "GenSigSendOnInit" SG_ 2158796800 ODII_ODIInd30 1;
BA_ "VNSigInfotainment" SG_ 2158796800 ODII_ODIInd30 1;
BA_ "SignalType" SG_ 2158796800 ODII_ODIInd30 "BLN";
BA_ "PacketOrder" SG_ 2158796800 ODII_ODIInd30 31;
BA_ "SignalLongName" SG_ 2158796800 ODII_ODIInd30 "Open Display Interface Indication : Open Display Interface Indication 30";
BA_ "VNSigAllNodes" SG_ 2158796800 ODII_ODIInd30 1;
BA_ "GenSigSendType" SG_ 2158796800 ODII_ODIInd29 10;
BA_ "GenSigSendOnInit" SG_ 2158796800 ODII_ODIInd29 1;
BA_ "VNSigInfotainment" SG_ 2158796800 ODII_ODIInd29 1;
BA_ "SignalType" SG_ 2158796800 ODII_ODIInd29 "BLN";
BA_ "PacketOrder" SG_ 2158796800 ODII_ODIInd29 30;
BA_ "SignalLongName" SG_ 2158796800 ODII_ODIInd29 "Open Display Interface Indication : Open Display Interface Indication 29";
BA_ "VNSigAllNodes" SG_ 2158796800 ODII_ODIInd29 1;
BA_ "GenSigSendType" SG_ 2158796800 ODII_ODIInd28 10;
BA_ "GenSigSendOnInit" SG_ 2158796800 ODII_ODIInd28 1;
BA_ "VNSigInfotainment" SG_ 2158796800 ODII_ODIInd28 1;
BA_ "SignalType" SG_ 2158796800 ODII_ODIInd28 "BLN";
BA_ "PacketOrder" SG_ 2158796800 ODII_ODIInd28 29;
BA_ "SignalLongName" SG_ 2158796800 ODII_ODIInd28 "Open Display Interface Indication : Open Display Interface Indication 28";
BA_ "VNSigAllNodes" SG_ 2158796800 ODII_ODIInd28 1;
BA_ "GenSigSendType" SG_ 2158796800 ODII_FUCID 12;
BA_ "GenSigSendOnInit" SG_ 2158796800 ODII_FUCID 1;
BA_ "VNSigInfotainment" SG_ 2158796800 ODII_FUCID 1;
BA_ "SignalType" SG_ 2158796800 ODII_FUCID "UNM";
BA_ "PacketOrder" SG_ 2158796800 ODII_FUCID 1;
BA_ "SignalLongName" SG_ 2158796800 ODII_FUCID "Open Display Interface Indication : Functional Unit Class ID";
BA_ "VNSigAllNodes" SG_ 2158796800 ODII_FUCID 1;
BA_ "GenSigSendType" SG_ 2158813184 ODIIIPC_ODIInd56 10;
BA_ "GenSigSendOnInit" SG_ 2158813184 ODIIIPC_ODIInd56 1;
BA_ "VNSigInfotainment" SG_ 2158813184 ODIIIPC_ODIInd56 1;
BA_ "SignalType" SG_ 2158813184 ODIIIPC_ODIInd56 "BLN";
BA_ "PacketOrder" SG_ 2158813184 ODIIIPC_ODIInd56 57;
BA_ "SignalLongName" SG_ 2158813184 ODIIIPC_ODIInd56 "Open Display Interface Indication IPC : Open Display Interface Indication 56";
BA_ "VNSigAllNodes" SG_ 2158813184 ODIIIPC_ODIInd56 1;
BA_ "GenSigSendType" SG_ 2158813184 ODIIIPC_ODIInd55 10;
BA_ "GenSigSendOnInit" SG_ 2158813184 ODIIIPC_ODIInd55 1;
BA_ "VNSigInfotainment" SG_ 2158813184 ODIIIPC_ODIInd55 1;
BA_ "SignalType" SG_ 2158813184 ODIIIPC_ODIInd55 "BLN";
BA_ "PacketOrder" SG_ 2158813184 ODIIIPC_ODIInd55 56;
BA_ "SignalLongName" SG_ 2158813184 ODIIIPC_ODIInd55 "Open Display Interface Indication IPC : Open Display Interface Indication 55";
BA_ "VNSigAllNodes" SG_ 2158813184 ODIIIPC_ODIInd55 1;
BA_ "GenSigSendType" SG_ 2158813184 ODIIIPC_ODIInd54 10;
BA_ "GenSigSendOnInit" SG_ 2158813184 ODIIIPC_ODIInd54 1;
BA_ "VNSigInfotainment" SG_ 2158813184 ODIIIPC_ODIInd54 1;
BA_ "SignalType" SG_ 2158813184 ODIIIPC_ODIInd54 "BLN";
BA_ "PacketOrder" SG_ 2158813184 ODIIIPC_ODIInd54 55;
BA_ "SignalLongName" SG_ 2158813184 ODIIIPC_ODIInd54 "Open Display Interface Indication IPC : Open Display Interface Indication 54";
BA_ "VNSigAllNodes" SG_ 2158813184 ODIIIPC_ODIInd54 1;
BA_ "GenSigSendType" SG_ 2158813184 ODIIIPC_ODIInd53 10;
BA_ "GenSigSendOnInit" SG_ 2158813184 ODIIIPC_ODIInd53 1;
BA_ "VNSigInfotainment" SG_ 2158813184 ODIIIPC_ODIInd53 1;
BA_ "SignalType" SG_ 2158813184 ODIIIPC_ODIInd53 "BLN";
BA_ "PacketOrder" SG_ 2158813184 ODIIIPC_ODIInd53 54;
BA_ "SignalLongName" SG_ 2158813184 ODIIIPC_ODIInd53 "Open Display Interface Indication IPC : Open Display Interface Indication 53";
BA_ "VNSigAllNodes" SG_ 2158813184 ODIIIPC_ODIInd53 1;
BA_ "GenSigSendType" SG_ 2158813184 ODIIIPC_ODIInd52 10;
BA_ "GenSigSendOnInit" SG_ 2158813184 ODIIIPC_ODIInd52 1;
BA_ "VNSigInfotainment" SG_ 2158813184 ODIIIPC_ODIInd52 1;
BA_ "SignalType" SG_ 2158813184 ODIIIPC_ODIInd52 "BLN";
BA_ "PacketOrder" SG_ 2158813184 ODIIIPC_ODIInd52 53;
BA_ "SignalLongName" SG_ 2158813184 ODIIIPC_ODIInd52 "Open Display Interface Indication IPC : Open Display Interface Indication 52";
BA_ "VNSigAllNodes" SG_ 2158813184 ODIIIPC_ODIInd52 1;
BA_ "GenSigSendType" SG_ 2158813184 ODIIIPC_ODIInd51 10;
BA_ "GenSigSendOnInit" SG_ 2158813184 ODIIIPC_ODIInd51 1;
BA_ "VNSigInfotainment" SG_ 2158813184 ODIIIPC_ODIInd51 1;
BA_ "SignalType" SG_ 2158813184 ODIIIPC_ODIInd51 "BLN";
BA_ "PacketOrder" SG_ 2158813184 ODIIIPC_ODIInd51 52;
BA_ "SignalLongName" SG_ 2158813184 ODIIIPC_ODIInd51 "Open Display Interface Indication IPC : Open Display Interface Indication 51";
BA_ "VNSigAllNodes" SG_ 2158813184 ODIIIPC_ODIInd51 1;
BA_ "GenSigSendType" SG_ 2158813184 ODIIIPC_ODIInd50 10;
BA_ "GenSigSendOnInit" SG_ 2158813184 ODIIIPC_ODIInd50 1;
BA_ "VNSigInfotainment" SG_ 2158813184 ODIIIPC_ODIInd50 1;
BA_ "SignalType" SG_ 2158813184 ODIIIPC_ODIInd50 "BLN";
BA_ "PacketOrder" SG_ 2158813184 ODIIIPC_ODIInd50 51;
BA_ "SignalLongName" SG_ 2158813184 ODIIIPC_ODIInd50 "Open Display Interface Indication IPC : Open Display Interface Indication 50";
BA_ "VNSigAllNodes" SG_ 2158813184 ODIIIPC_ODIInd50 1;
BA_ "GenSigSendType" SG_ 2158813184 ODIIIPC_ODIInd49 10;
BA_ "GenSigSendOnInit" SG_ 2158813184 ODIIIPC_ODIInd49 1;
BA_ "VNSigInfotainment" SG_ 2158813184 ODIIIPC_ODIInd49 1;
BA_ "SignalType" SG_ 2158813184 ODIIIPC_ODIInd49 "BLN";
BA_ "PacketOrder" SG_ 2158813184 ODIIIPC_ODIInd49 50;
BA_ "SignalLongName" SG_ 2158813184 ODIIIPC_ODIInd49 "Open Display Interface Indication IPC : Open Display Interface Indication 49";
BA_ "VNSigAllNodes" SG_ 2158813184 ODIIIPC_ODIInd49 1;
BA_ "GenSigSendType" SG_ 2158813184 ODIIIPC_ODIInd48 10;
BA_ "GenSigSendOnInit" SG_ 2158813184 ODIIIPC_ODIInd48 1;
BA_ "VNSigInfotainment" SG_ 2158813184 ODIIIPC_ODIInd48 1;
BA_ "SignalType" SG_ 2158813184 ODIIIPC_ODIInd48 "BLN";
BA_ "PacketOrder" SG_ 2158813184 ODIIIPC_ODIInd48 49;
BA_ "SignalLongName" SG_ 2158813184 ODIIIPC_ODIInd48 "Open Display Interface Indication IPC : Open Display Interface Indication 48";
BA_ "VNSigAllNodes" SG_ 2158813184 ODIIIPC_ODIInd48 1;
BA_ "GenSigSendType" SG_ 2158813184 ODIIIPC_ODIInd47 10;
BA_ "GenSigSendOnInit" SG_ 2158813184 ODIIIPC_ODIInd47 1;
BA_ "VNSigInfotainment" SG_ 2158813184 ODIIIPC_ODIInd47 1;
BA_ "SignalType" SG_ 2158813184 ODIIIPC_ODIInd47 "BLN";
BA_ "PacketOrder" SG_ 2158813184 ODIIIPC_ODIInd47 48;
BA_ "SignalLongName" SG_ 2158813184 ODIIIPC_ODIInd47 "Open Display Interface Indication IPC : Open Display Interface Indication 47";
BA_ "VNSigAllNodes" SG_ 2158813184 ODIIIPC_ODIInd47 1;
BA_ "GenSigSendType" SG_ 2158813184 ODIIIPC_ODIInd46 10;
BA_ "GenSigSendOnInit" SG_ 2158813184 ODIIIPC_ODIInd46 1;
BA_ "VNSigInfotainment" SG_ 2158813184 ODIIIPC_ODIInd46 1;
BA_ "SignalType" SG_ 2158813184 ODIIIPC_ODIInd46 "BLN";
BA_ "PacketOrder" SG_ 2158813184 ODIIIPC_ODIInd46 47;
BA_ "SignalLongName" SG_ 2158813184 ODIIIPC_ODIInd46 "Open Display Interface Indication IPC : Open Display Interface Indication 46";
BA_ "VNSigAllNodes" SG_ 2158813184 ODIIIPC_ODIInd46 1;
BA_ "GenSigSendType" SG_ 2158813184 ODIIIPC_ODIInd45 10;
BA_ "GenSigSendOnInit" SG_ 2158813184 ODIIIPC_ODIInd45 1;
BA_ "VNSigInfotainment" SG_ 2158813184 ODIIIPC_ODIInd45 1;
BA_ "SignalType" SG_ 2158813184 ODIIIPC_ODIInd45 "BLN";
BA_ "PacketOrder" SG_ 2158813184 ODIIIPC_ODIInd45 46;
BA_ "SignalLongName" SG_ 2158813184 ODIIIPC_ODIInd45 "Open Display Interface Indication IPC : Open Display Interface Indication 45";
BA_ "VNSigAllNodes" SG_ 2158813184 ODIIIPC_ODIInd45 1;
BA_ "GenSigSendType" SG_ 2158813184 ODIIIPC_ODIInd44 10;
BA_ "GenSigSendOnInit" SG_ 2158813184 ODIIIPC_ODIInd44 1;
BA_ "VNSigInfotainment" SG_ 2158813184 ODIIIPC_ODIInd44 1;
BA_ "SignalType" SG_ 2158813184 ODIIIPC_ODIInd44 "BLN";
BA_ "PacketOrder" SG_ 2158813184 ODIIIPC_ODIInd44 45;
BA_ "SignalLongName" SG_ 2158813184 ODIIIPC_ODIInd44 "Open Display Interface Indication IPC : Open Display Interface Indication 44";
BA_ "VNSigAllNodes" SG_ 2158813184 ODIIIPC_ODIInd44 1;
BA_ "GenSigSendType" SG_ 2158813184 ODIIIPC_ODIInd43 10;
BA_ "GenSigSendOnInit" SG_ 2158813184 ODIIIPC_ODIInd43 1;
BA_ "VNSigInfotainment" SG_ 2158813184 ODIIIPC_ODIInd43 1;
BA_ "SignalType" SG_ 2158813184 ODIIIPC_ODIInd43 "BLN";
BA_ "PacketOrder" SG_ 2158813184 ODIIIPC_ODIInd43 44;
BA_ "SignalLongName" SG_ 2158813184 ODIIIPC_ODIInd43 "Open Display Interface Indication IPC : Open Display Interface Indication 43";
BA_ "VNSigAllNodes" SG_ 2158813184 ODIIIPC_ODIInd43 1;
BA_ "GenSigSendType" SG_ 2158813184 ODIIIPC_ODIInd42 10;
BA_ "GenSigSendOnInit" SG_ 2158813184 ODIIIPC_ODIInd42 1;
BA_ "VNSigInfotainment" SG_ 2158813184 ODIIIPC_ODIInd42 1;
BA_ "SignalType" SG_ 2158813184 ODIIIPC_ODIInd42 "BLN";
BA_ "PacketOrder" SG_ 2158813184 ODIIIPC_ODIInd42 43;
BA_ "SignalLongName" SG_ 2158813184 ODIIIPC_ODIInd42 "Open Display Interface Indication IPC : Open Display Interface Indication 42";
BA_ "VNSigAllNodes" SG_ 2158813184 ODIIIPC_ODIInd42 1;
BA_ "GenSigSendType" SG_ 2158813184 ODIIIPC_ODIInd41 10;
BA_ "GenSigSendOnInit" SG_ 2158813184 ODIIIPC_ODIInd41 1;
BA_ "VNSigInfotainment" SG_ 2158813184 ODIIIPC_ODIInd41 1;
BA_ "SignalType" SG_ 2158813184 ODIIIPC_ODIInd41 "BLN";
BA_ "PacketOrder" SG_ 2158813184 ODIIIPC_ODIInd41 42;
BA_ "SignalLongName" SG_ 2158813184 ODIIIPC_ODIInd41 "Open Display Interface Indication IPC : Open Display Interface Indication 41";
BA_ "VNSigAllNodes" SG_ 2158813184 ODIIIPC_ODIInd41 1;
BA_ "GenSigSendType" SG_ 2158813184 ODIIIPC_ODIInd40 10;
BA_ "GenSigSendOnInit" SG_ 2158813184 ODIIIPC_ODIInd40 1;
BA_ "VNSigInfotainment" SG_ 2158813184 ODIIIPC_ODIInd40 1;
BA_ "SignalType" SG_ 2158813184 ODIIIPC_ODIInd40 "BLN";
BA_ "PacketOrder" SG_ 2158813184 ODIIIPC_ODIInd40 41;
BA_ "SignalLongName" SG_ 2158813184 ODIIIPC_ODIInd40 "Open Display Interface Indication IPC : Open Display Interface Indication 40";
BA_ "VNSigAllNodes" SG_ 2158813184 ODIIIPC_ODIInd40 1;
BA_ "GenSigSendType" SG_ 2158813184 ODIIIPC_ODIInd39 10;
BA_ "GenSigSendOnInit" SG_ 2158813184 ODIIIPC_ODIInd39 1;
BA_ "VNSigInfotainment" SG_ 2158813184 ODIIIPC_ODIInd39 1;
BA_ "SignalType" SG_ 2158813184 ODIIIPC_ODIInd39 "BLN";
BA_ "PacketOrder" SG_ 2158813184 ODIIIPC_ODIInd39 40;
BA_ "SignalLongName" SG_ 2158813184 ODIIIPC_ODIInd39 "Open Display Interface Indication IPC : Open Display Interface Indication 39";
BA_ "VNSigAllNodes" SG_ 2158813184 ODIIIPC_ODIInd39 1;
BA_ "GenSigSendType" SG_ 2158813184 ODIIIPC_ODIInd38 10;
BA_ "GenSigSendOnInit" SG_ 2158813184 ODIIIPC_ODIInd38 1;
BA_ "VNSigInfotainment" SG_ 2158813184 ODIIIPC_ODIInd38 1;
BA_ "SignalType" SG_ 2158813184 ODIIIPC_ODIInd38 "BLN";
BA_ "PacketOrder" SG_ 2158813184 ODIIIPC_ODIInd38 39;
BA_ "SignalLongName" SG_ 2158813184 ODIIIPC_ODIInd38 "Open Display Interface Indication IPC : Open Display Interface Indication 38";
BA_ "VNSigAllNodes" SG_ 2158813184 ODIIIPC_ODIInd38 1;
BA_ "GenSigSendType" SG_ 2158813184 ODIIIPC_ODIInd9 10;
BA_ "GenSigSendOnInit" SG_ 2158813184 ODIIIPC_ODIInd9 1;
BA_ "VNSigInfotainment" SG_ 2158813184 ODIIIPC_ODIInd9 1;
BA_ "SignalType" SG_ 2158813184 ODIIIPC_ODIInd9 "BLN";
BA_ "PacketOrder" SG_ 2158813184 ODIIIPC_ODIInd9 10;
BA_ "SignalLongName" SG_ 2158813184 ODIIIPC_ODIInd9 "Open Display Interface Indication IPC : Open Display Interface Indication 9";
BA_ "VNSigAllNodes" SG_ 2158813184 ODIIIPC_ODIInd9 1;
BA_ "GenSigSendType" SG_ 2158813184 ODIIIPC_ODIInd8 10;
BA_ "GenSigSendOnInit" SG_ 2158813184 ODIIIPC_ODIInd8 1;
BA_ "VNSigInfotainment" SG_ 2158813184 ODIIIPC_ODIInd8 1;
BA_ "SignalType" SG_ 2158813184 ODIIIPC_ODIInd8 "BLN";
BA_ "PacketOrder" SG_ 2158813184 ODIIIPC_ODIInd8 9;
BA_ "SignalLongName" SG_ 2158813184 ODIIIPC_ODIInd8 "Open Display Interface Indication IPC : Open Display Interface Indication 8";
BA_ "VNSigAllNodes" SG_ 2158813184 ODIIIPC_ODIInd8 1;
BA_ "GenSigSendType" SG_ 2158813184 ODIIIPC_ODIInd7 10;
BA_ "GenSigSendOnInit" SG_ 2158813184 ODIIIPC_ODIInd7 1;
BA_ "VNSigInfotainment" SG_ 2158813184 ODIIIPC_ODIInd7 1;
BA_ "SignalType" SG_ 2158813184 ODIIIPC_ODIInd7 "BLN";
BA_ "PacketOrder" SG_ 2158813184 ODIIIPC_ODIInd7 8;
BA_ "SignalLongName" SG_ 2158813184 ODIIIPC_ODIInd7 "Open Display Interface Indication IPC : Open Display Interface Indication 7";
BA_ "VNSigAllNodes" SG_ 2158813184 ODIIIPC_ODIInd7 1;
BA_ "GenSigSendType" SG_ 2158813184 ODIIIPC_ODIInd6 10;
BA_ "GenSigSendOnInit" SG_ 2158813184 ODIIIPC_ODIInd6 1;
BA_ "VNSigInfotainment" SG_ 2158813184 ODIIIPC_ODIInd6 1;
BA_ "SignalType" SG_ 2158813184 ODIIIPC_ODIInd6 "BLN";
BA_ "PacketOrder" SG_ 2158813184 ODIIIPC_ODIInd6 7;
BA_ "SignalLongName" SG_ 2158813184 ODIIIPC_ODIInd6 "Open Display Interface Indication IPC : Open Display Interface Indication 6";
BA_ "VNSigAllNodes" SG_ 2158813184 ODIIIPC_ODIInd6 1;
BA_ "GenSigSendType" SG_ 2158813184 ODIIIPC_ODIInd5 10;
BA_ "GenSigSendOnInit" SG_ 2158813184 ODIIIPC_ODIInd5 1;
BA_ "VNSigInfotainment" SG_ 2158813184 ODIIIPC_ODIInd5 1;
BA_ "SignalType" SG_ 2158813184 ODIIIPC_ODIInd5 "BLN";
BA_ "PacketOrder" SG_ 2158813184 ODIIIPC_ODIInd5 6;
BA_ "SignalLongName" SG_ 2158813184 ODIIIPC_ODIInd5 "Open Display Interface Indication IPC : Open Display Interface Indication 5";
BA_ "VNSigAllNodes" SG_ 2158813184 ODIIIPC_ODIInd5 1;
BA_ "GenSigSendType" SG_ 2158813184 ODIIIPC_ODIInd4 10;
BA_ "GenSigSendOnInit" SG_ 2158813184 ODIIIPC_ODIInd4 1;
BA_ "VNSigInfotainment" SG_ 2158813184 ODIIIPC_ODIInd4 1;
BA_ "SignalType" SG_ 2158813184 ODIIIPC_ODIInd4 "BLN";
BA_ "PacketOrder" SG_ 2158813184 ODIIIPC_ODIInd4 5;
BA_ "SignalLongName" SG_ 2158813184 ODIIIPC_ODIInd4 "Open Display Interface Indication IPC : Open Display Interface Indication 4";
BA_ "VNSigAllNodes" SG_ 2158813184 ODIIIPC_ODIInd4 1;
BA_ "GenSigSendType" SG_ 2158813184 ODIIIPC_ODIInd3 10;
BA_ "GenSigSendOnInit" SG_ 2158813184 ODIIIPC_ODIInd3 1;
BA_ "VNSigInfotainment" SG_ 2158813184 ODIIIPC_ODIInd3 1;
BA_ "SignalType" SG_ 2158813184 ODIIIPC_ODIInd3 "BLN";
BA_ "PacketOrder" SG_ 2158813184 ODIIIPC_ODIInd3 4;
BA_ "SignalLongName" SG_ 2158813184 ODIIIPC_ODIInd3 "Open Display Interface Indication IPC : Open Display Interface Indication 3";
BA_ "VNSigAllNodes" SG_ 2158813184 ODIIIPC_ODIInd3 1;
BA_ "GenSigSendType" SG_ 2158813184 ODIIIPC_ODIInd37 10;
BA_ "GenSigSendOnInit" SG_ 2158813184 ODIIIPC_ODIInd37 1;
BA_ "VNSigInfotainment" SG_ 2158813184 ODIIIPC_ODIInd37 1;
BA_ "SignalType" SG_ 2158813184 ODIIIPC_ODIInd37 "BLN";
BA_ "PacketOrder" SG_ 2158813184 ODIIIPC_ODIInd37 38;
BA_ "SignalLongName" SG_ 2158813184 ODIIIPC_ODIInd37 "Open Display Interface Indication IPC : Open Display Interface Indication 37";
BA_ "VNSigAllNodes" SG_ 2158813184 ODIIIPC_ODIInd37 1;
BA_ "GenSigSendType" SG_ 2158813184 ODIIIPC_ODIInd36 10;
BA_ "GenSigSendOnInit" SG_ 2158813184 ODIIIPC_ODIInd36 1;
BA_ "VNSigInfotainment" SG_ 2158813184 ODIIIPC_ODIInd36 1;
BA_ "SignalType" SG_ 2158813184 ODIIIPC_ODIInd36 "BLN";
BA_ "PacketOrder" SG_ 2158813184 ODIIIPC_ODIInd36 37;
BA_ "SignalLongName" SG_ 2158813184 ODIIIPC_ODIInd36 "Open Display Interface Indication IPC : Open Display Interface Indication 36";
BA_ "VNSigAllNodes" SG_ 2158813184 ODIIIPC_ODIInd36 1;
BA_ "GenSigSendType" SG_ 2158813184 ODIIIPC_ODIInd35 10;
BA_ "GenSigSendOnInit" SG_ 2158813184 ODIIIPC_ODIInd35 1;
BA_ "VNSigInfotainment" SG_ 2158813184 ODIIIPC_ODIInd35 1;
BA_ "SignalType" SG_ 2158813184 ODIIIPC_ODIInd35 "BLN";
BA_ "PacketOrder" SG_ 2158813184 ODIIIPC_ODIInd35 36;
BA_ "SignalLongName" SG_ 2158813184 ODIIIPC_ODIInd35 "Open Display Interface Indication IPC : Open Display Interface Indication 35";
BA_ "VNSigAllNodes" SG_ 2158813184 ODIIIPC_ODIInd35 1;
BA_ "GenSigSendType" SG_ 2158813184 ODIIIPC_ODIInd34 10;
BA_ "GenSigSendOnInit" SG_ 2158813184 ODIIIPC_ODIInd34 1;
BA_ "VNSigInfotainment" SG_ 2158813184 ODIIIPC_ODIInd34 1;
BA_ "SignalType" SG_ 2158813184 ODIIIPC_ODIInd34 "BLN";
BA_ "PacketOrder" SG_ 2158813184 ODIIIPC_ODIInd34 35;
BA_ "SignalLongName" SG_ 2158813184 ODIIIPC_ODIInd34 "Open Display Interface Indication IPC : Open Display Interface Indication 34";
BA_ "VNSigAllNodes" SG_ 2158813184 ODIIIPC_ODIInd34 1;
BA_ "GenSigSendType" SG_ 2158813184 ODIIIPC_ODIInd33 10;
BA_ "GenSigSendOnInit" SG_ 2158813184 ODIIIPC_ODIInd33 1;
BA_ "VNSigInfotainment" SG_ 2158813184 ODIIIPC_ODIInd33 1;
BA_ "SignalType" SG_ 2158813184 ODIIIPC_ODIInd33 "BLN";
BA_ "PacketOrder" SG_ 2158813184 ODIIIPC_ODIInd33 34;
BA_ "SignalLongName" SG_ 2158813184 ODIIIPC_ODIInd33 "Open Display Interface Indication IPC : Open Display Interface Indication 33";
BA_ "VNSigAllNodes" SG_ 2158813184 ODIIIPC_ODIInd33 1;
BA_ "GenSigSendType" SG_ 2158813184 ODIIIPC_ODIInd32 10;
BA_ "GenSigSendOnInit" SG_ 2158813184 ODIIIPC_ODIInd32 1;
BA_ "VNSigInfotainment" SG_ 2158813184 ODIIIPC_ODIInd32 1;
BA_ "SignalType" SG_ 2158813184 ODIIIPC_ODIInd32 "BLN";
BA_ "PacketOrder" SG_ 2158813184 ODIIIPC_ODIInd32 33;
BA_ "SignalLongName" SG_ 2158813184 ODIIIPC_ODIInd32 "Open Display Interface Indication IPC : Open Display Interface Indication 32";
BA_ "VNSigAllNodes" SG_ 2158813184 ODIIIPC_ODIInd32 1;
BA_ "GenSigSendType" SG_ 2158813184 ODIIIPC_ODIInd31 10;
BA_ "GenSigSendOnInit" SG_ 2158813184 ODIIIPC_ODIInd31 1;
BA_ "VNSigInfotainment" SG_ 2158813184 ODIIIPC_ODIInd31 1;
BA_ "SignalType" SG_ 2158813184 ODIIIPC_ODIInd31 "BLN";
BA_ "PacketOrder" SG_ 2158813184 ODIIIPC_ODIInd31 32;
BA_ "SignalLongName" SG_ 2158813184 ODIIIPC_ODIInd31 "Open Display Interface Indication IPC : Open Display Interface Indication 31";
BA_ "VNSigAllNodes" SG_ 2158813184 ODIIIPC_ODIInd31 1;
BA_ "GenSigSendType" SG_ 2158813184 ODIIIPC_ODIInd30 10;
BA_ "GenSigSendOnInit" SG_ 2158813184 ODIIIPC_ODIInd30 1;
BA_ "VNSigInfotainment" SG_ 2158813184 ODIIIPC_ODIInd30 1;
BA_ "SignalType" SG_ 2158813184 ODIIIPC_ODIInd30 "BLN";
BA_ "PacketOrder" SG_ 2158813184 ODIIIPC_ODIInd30 31;
BA_ "SignalLongName" SG_ 2158813184 ODIIIPC_ODIInd30 "Open Display Interface Indication IPC : Open Display Interface Indication 30";
BA_ "VNSigAllNodes" SG_ 2158813184 ODIIIPC_ODIInd30 1;
BA_ "GenSigSendType" SG_ 2158813184 ODIIIPC_ODIInd29 10;
BA_ "GenSigSendOnInit" SG_ 2158813184 ODIIIPC_ODIInd29 1;
BA_ "VNSigInfotainment" SG_ 2158813184 ODIIIPC_ODIInd29 1;
BA_ "SignalType" SG_ 2158813184 ODIIIPC_ODIInd29 "BLN";
BA_ "PacketOrder" SG_ 2158813184 ODIIIPC_ODIInd29 30;
BA_ "SignalLongName" SG_ 2158813184 ODIIIPC_ODIInd29 "Open Display Interface Indication IPC : Open Display Interface Indication 29";
BA_ "VNSigAllNodes" SG_ 2158813184 ODIIIPC_ODIInd29 1;
BA_ "GenSigSendType" SG_ 2158813184 ODIIIPC_ODIInd28 10;
BA_ "GenSigSendOnInit" SG_ 2158813184 ODIIIPC_ODIInd28 1;
BA_ "VNSigInfotainment" SG_ 2158813184 ODIIIPC_ODIInd28 1;
BA_ "SignalType" SG_ 2158813184 ODIIIPC_ODIInd28 "BLN";
BA_ "PacketOrder" SG_ 2158813184 ODIIIPC_ODIInd28 29;
BA_ "SignalLongName" SG_ 2158813184 ODIIIPC_ODIInd28 "Open Display Interface Indication IPC : Open Display Interface Indication 28";
BA_ "VNSigAllNodes" SG_ 2158813184 ODIIIPC_ODIInd28 1;
BA_ "GenSigSendType" SG_ 2158813184 ODIIIPC_ODIInd27 10;
BA_ "GenSigSendOnInit" SG_ 2158813184 ODIIIPC_ODIInd27 1;
BA_ "VNSigInfotainment" SG_ 2158813184 ODIIIPC_ODIInd27 1;
BA_ "SignalType" SG_ 2158813184 ODIIIPC_ODIInd27 "BLN";
BA_ "PacketOrder" SG_ 2158813184 ODIIIPC_ODIInd27 28;
BA_ "SignalLongName" SG_ 2158813184 ODIIIPC_ODIInd27 "Open Display Interface Indication IPC : Open Display Interface Indication 27";
BA_ "VNSigAllNodes" SG_ 2158813184 ODIIIPC_ODIInd27 1;
BA_ "GenSigSendType" SG_ 2158813184 ODIIIPC_ODIInd26 10;
BA_ "GenSigSendOnInit" SG_ 2158813184 ODIIIPC_ODIInd26 1;
BA_ "VNSigInfotainment" SG_ 2158813184 ODIIIPC_ODIInd26 1;
BA_ "SignalType" SG_ 2158813184 ODIIIPC_ODIInd26 "BLN";
BA_ "PacketOrder" SG_ 2158813184 ODIIIPC_ODIInd26 27;
BA_ "SignalLongName" SG_ 2158813184 ODIIIPC_ODIInd26 "Open Display Interface Indication IPC : Open Display Interface Indication 26";
BA_ "VNSigAllNodes" SG_ 2158813184 ODIIIPC_ODIInd26 1;
BA_ "GenSigSendType" SG_ 2158813184 ODIIIPC_ODIInd25 10;
BA_ "GenSigSendOnInit" SG_ 2158813184 ODIIIPC_ODIInd25 1;
BA_ "VNSigInfotainment" SG_ 2158813184 ODIIIPC_ODIInd25 1;
BA_ "SignalType" SG_ 2158813184 ODIIIPC_ODIInd25 "BLN";
BA_ "PacketOrder" SG_ 2158813184 ODIIIPC_ODIInd25 26;
BA_ "SignalLongName" SG_ 2158813184 ODIIIPC_ODIInd25 "Open Display Interface Indication IPC : Open Display Interface Indication 25";
BA_ "VNSigAllNodes" SG_ 2158813184 ODIIIPC_ODIInd25 1;
BA_ "GenSigSendType" SG_ 2158813184 ODIIIPC_ODIInd24 10;
BA_ "GenSigSendOnInit" SG_ 2158813184 ODIIIPC_ODIInd24 1;
BA_ "VNSigInfotainment" SG_ 2158813184 ODIIIPC_ODIInd24 1;
BA_ "SignalType" SG_ 2158813184 ODIIIPC_ODIInd24 "BLN";
BA_ "PacketOrder" SG_ 2158813184 ODIIIPC_ODIInd24 25;
BA_ "SignalLongName" SG_ 2158813184 ODIIIPC_ODIInd24 "Open Display Interface Indication IPC : Open Display Interface Indication 24";
BA_ "VNSigAllNodes" SG_ 2158813184 ODIIIPC_ODIInd24 1;
BA_ "GenSigSendType" SG_ 2158813184 ODIIIPC_ODIInd23 10;
BA_ "GenSigSendOnInit" SG_ 2158813184 ODIIIPC_ODIInd23 1;
BA_ "VNSigInfotainment" SG_ 2158813184 ODIIIPC_ODIInd23 1;
BA_ "SignalType" SG_ 2158813184 ODIIIPC_ODIInd23 "BLN";
BA_ "PacketOrder" SG_ 2158813184 ODIIIPC_ODIInd23 24;
BA_ "SignalLongName" SG_ 2158813184 ODIIIPC_ODIInd23 "Open Display Interface Indication IPC : Open Display Interface Indication 23";
BA_ "VNSigAllNodes" SG_ 2158813184 ODIIIPC_ODIInd23 1;
BA_ "GenSigSendType" SG_ 2158813184 ODIIIPC_ODIInd22 10;
BA_ "GenSigSendOnInit" SG_ 2158813184 ODIIIPC_ODIInd22 1;
BA_ "VNSigInfotainment" SG_ 2158813184 ODIIIPC_ODIInd22 1;
BA_ "SignalType" SG_ 2158813184 ODIIIPC_ODIInd22 "BLN";
BA_ "PacketOrder" SG_ 2158813184 ODIIIPC_ODIInd22 23;
BA_ "SignalLongName" SG_ 2158813184 ODIIIPC_ODIInd22 "Open Display Interface Indication IPC : Open Display Interface Indication 22";
BA_ "VNSigAllNodes" SG_ 2158813184 ODIIIPC_ODIInd22 1;
BA_ "GenSigSendType" SG_ 2158813184 ODIIIPC_ODIInd21 10;
BA_ "GenSigSendOnInit" SG_ 2158813184 ODIIIPC_ODIInd21 1;
BA_ "VNSigInfotainment" SG_ 2158813184 ODIIIPC_ODIInd21 1;
BA_ "SignalType" SG_ 2158813184 ODIIIPC_ODIInd21 "BLN";
BA_ "PacketOrder" SG_ 2158813184 ODIIIPC_ODIInd21 22;
BA_ "SignalLongName" SG_ 2158813184 ODIIIPC_ODIInd21 "Open Display Interface Indication IPC : Open Display Interface Indication 21";
BA_ "VNSigAllNodes" SG_ 2158813184 ODIIIPC_ODIInd21 1;
BA_ "GenSigSendType" SG_ 2158813184 ODIIIPC_ODIInd20 10;
BA_ "GenSigSendOnInit" SG_ 2158813184 ODIIIPC_ODIInd20 1;
BA_ "VNSigInfotainment" SG_ 2158813184 ODIIIPC_ODIInd20 1;
BA_ "SignalType" SG_ 2158813184 ODIIIPC_ODIInd20 "BLN";
BA_ "PacketOrder" SG_ 2158813184 ODIIIPC_ODIInd20 21;
BA_ "SignalLongName" SG_ 2158813184 ODIIIPC_ODIInd20 "Open Display Interface Indication IPC : Open Display Interface Indication 20";
BA_ "VNSigAllNodes" SG_ 2158813184 ODIIIPC_ODIInd20 1;
BA_ "GenSigSendType" SG_ 2158813184 ODIIIPC_ODIInd19 10;
BA_ "GenSigSendOnInit" SG_ 2158813184 ODIIIPC_ODIInd19 1;
BA_ "VNSigInfotainment" SG_ 2158813184 ODIIIPC_ODIInd19 1;
BA_ "SignalType" SG_ 2158813184 ODIIIPC_ODIInd19 "BLN";
BA_ "PacketOrder" SG_ 2158813184 ODIIIPC_ODIInd19 20;
BA_ "SignalLongName" SG_ 2158813184 ODIIIPC_ODIInd19 "Open Display Interface Indication IPC : Open Display Interface Indication 19";
BA_ "VNSigAllNodes" SG_ 2158813184 ODIIIPC_ODIInd19 1;
BA_ "GenSigSendType" SG_ 2158813184 ODIIIPC_ODIInd18 10;
BA_ "GenSigSendOnInit" SG_ 2158813184 ODIIIPC_ODIInd18 1;
BA_ "VNSigInfotainment" SG_ 2158813184 ODIIIPC_ODIInd18 1;
BA_ "SignalType" SG_ 2158813184 ODIIIPC_ODIInd18 "BLN";
BA_ "PacketOrder" SG_ 2158813184 ODIIIPC_ODIInd18 19;
BA_ "SignalLongName" SG_ 2158813184 ODIIIPC_ODIInd18 "Open Display Interface Indication IPC : Open Display Interface Indication 18";
BA_ "VNSigAllNodes" SG_ 2158813184 ODIIIPC_ODIInd18 1;
BA_ "GenSigSendType" SG_ 2158813184 ODIIIPC_ODIInd17 10;
BA_ "GenSigSendOnInit" SG_ 2158813184 ODIIIPC_ODIInd17 1;
BA_ "VNSigInfotainment" SG_ 2158813184 ODIIIPC_ODIInd17 1;
BA_ "SignalType" SG_ 2158813184 ODIIIPC_ODIInd17 "BLN";
BA_ "PacketOrder" SG_ 2158813184 ODIIIPC_ODIInd17 18;
BA_ "SignalLongName" SG_ 2158813184 ODIIIPC_ODIInd17 "Open Display Interface Indication IPC : Open Display Interface Indication 17";
BA_ "VNSigAllNodes" SG_ 2158813184 ODIIIPC_ODIInd17 1;
BA_ "GenSigSendType" SG_ 2158813184 ODIIIPC_ODIInd16 10;
BA_ "GenSigSendOnInit" SG_ 2158813184 ODIIIPC_ODIInd16 1;
BA_ "VNSigInfotainment" SG_ 2158813184 ODIIIPC_ODIInd16 1;
BA_ "SignalType" SG_ 2158813184 ODIIIPC_ODIInd16 "BLN";
BA_ "PacketOrder" SG_ 2158813184 ODIIIPC_ODIInd16 17;
BA_ "SignalLongName" SG_ 2158813184 ODIIIPC_ODIInd16 "Open Display Interface Indication IPC : Open Display Interface Indication 16";
BA_ "VNSigAllNodes" SG_ 2158813184 ODIIIPC_ODIInd16 1;
BA_ "GenSigSendType" SG_ 2158813184 ODIIIPC_ODIInd15 10;
BA_ "GenSigSendOnInit" SG_ 2158813184 ODIIIPC_ODIInd15 1;
BA_ "VNSigInfotainment" SG_ 2158813184 ODIIIPC_ODIInd15 1;
BA_ "SignalType" SG_ 2158813184 ODIIIPC_ODIInd15 "BLN";
BA_ "PacketOrder" SG_ 2158813184 ODIIIPC_ODIInd15 16;
BA_ "SignalLongName" SG_ 2158813184 ODIIIPC_ODIInd15 "Open Display Interface Indication IPC : Open Display Interface Indication 15";
BA_ "VNSigAllNodes" SG_ 2158813184 ODIIIPC_ODIInd15 1;
BA_ "GenSigSendType" SG_ 2158813184 ODIIIPC_ODIInd14 10;
BA_ "GenSigSendOnInit" SG_ 2158813184 ODIIIPC_ODIInd14 1;
BA_ "VNSigInfotainment" SG_ 2158813184 ODIIIPC_ODIInd14 1;
BA_ "SignalType" SG_ 2158813184 ODIIIPC_ODIInd14 "BLN";
BA_ "PacketOrder" SG_ 2158813184 ODIIIPC_ODIInd14 15;
BA_ "SignalLongName" SG_ 2158813184 ODIIIPC_ODIInd14 "Open Display Interface Indication IPC : Open Display Interface Indication 14";
BA_ "VNSigAllNodes" SG_ 2158813184 ODIIIPC_ODIInd14 1;
BA_ "GenSigSendType" SG_ 2158813184 ODIIIPC_ODIInd13 10;
BA_ "GenSigSendOnInit" SG_ 2158813184 ODIIIPC_ODIInd13 1;
BA_ "VNSigInfotainment" SG_ 2158813184 ODIIIPC_ODIInd13 1;
BA_ "SignalType" SG_ 2158813184 ODIIIPC_ODIInd13 "BLN";
BA_ "PacketOrder" SG_ 2158813184 ODIIIPC_ODIInd13 14;
BA_ "SignalLongName" SG_ 2158813184 ODIIIPC_ODIInd13 "Open Display Interface Indication IPC : Open Display Interface Indication 13";
BA_ "VNSigAllNodes" SG_ 2158813184 ODIIIPC_ODIInd13 1;
BA_ "GenSigSendType" SG_ 2158813184 ODIIIPC_ODIInd12 10;
BA_ "GenSigSendOnInit" SG_ 2158813184 ODIIIPC_ODIInd12 1;
BA_ "VNSigInfotainment" SG_ 2158813184 ODIIIPC_ODIInd12 1;
BA_ "SignalType" SG_ 2158813184 ODIIIPC_ODIInd12 "BLN";
BA_ "PacketOrder" SG_ 2158813184 ODIIIPC_ODIInd12 13;
BA_ "SignalLongName" SG_ 2158813184 ODIIIPC_ODIInd12 "Open Display Interface Indication IPC : Open Display Interface Indication 12";
BA_ "VNSigAllNodes" SG_ 2158813184 ODIIIPC_ODIInd12 1;
BA_ "GenSigSendType" SG_ 2158813184 ODIIIPC_ODIInd11 10;
BA_ "GenSigSendOnInit" SG_ 2158813184 ODIIIPC_ODIInd11 1;
BA_ "VNSigInfotainment" SG_ 2158813184 ODIIIPC_ODIInd11 1;
BA_ "SignalType" SG_ 2158813184 ODIIIPC_ODIInd11 "BLN";
BA_ "PacketOrder" SG_ 2158813184 ODIIIPC_ODIInd11 12;
BA_ "SignalLongName" SG_ 2158813184 ODIIIPC_ODIInd11 "Open Display Interface Indication IPC : Open Display Interface Indication 11";
BA_ "VNSigAllNodes" SG_ 2158813184 ODIIIPC_ODIInd11 1;
BA_ "GenSigSendType" SG_ 2158813184 ODIIIPC_ODIInd10 10;
BA_ "GenSigSendOnInit" SG_ 2158813184 ODIIIPC_ODIInd10 1;
BA_ "VNSigInfotainment" SG_ 2158813184 ODIIIPC_ODIInd10 1;
BA_ "SignalType" SG_ 2158813184 ODIIIPC_ODIInd10 "BLN";
BA_ "PacketOrder" SG_ 2158813184 ODIIIPC_ODIInd10 11;
BA_ "SignalLongName" SG_ 2158813184 ODIIIPC_ODIInd10 "Open Display Interface Indication IPC : Open Display Interface Indication 10";
BA_ "VNSigAllNodes" SG_ 2158813184 ODIIIPC_ODIInd10 1;
BA_ "GenSigSendType" SG_ 2158813184 ODIIIPC_ODIInd2 10;
BA_ "GenSigSendOnInit" SG_ 2158813184 ODIIIPC_ODIInd2 1;
BA_ "VNSigInfotainment" SG_ 2158813184 ODIIIPC_ODIInd2 1;
BA_ "SignalType" SG_ 2158813184 ODIIIPC_ODIInd2 "BLN";
BA_ "PacketOrder" SG_ 2158813184 ODIIIPC_ODIInd2 3;
BA_ "SignalLongName" SG_ 2158813184 ODIIIPC_ODIInd2 "Open Display Interface Indication IPC : Open Display Interface Indication 2";
BA_ "VNSigAllNodes" SG_ 2158813184 ODIIIPC_ODIInd2 1;
BA_ "GenSigSendType" SG_ 2158813184 ODIIIPC_ODIInd1 10;
BA_ "GenSigSendOnInit" SG_ 2158813184 ODIIIPC_ODIInd1 1;
BA_ "VNSigInfotainment" SG_ 2158813184 ODIIIPC_ODIInd1 1;
BA_ "SignalType" SG_ 2158813184 ODIIIPC_ODIInd1 "BLN";
BA_ "PacketOrder" SG_ 2158813184 ODIIIPC_ODIInd1 2;
BA_ "SignalLongName" SG_ 2158813184 ODIIIPC_ODIInd1 "Open Display Interface Indication IPC : Open Display Interface Indication 1";
BA_ "VNSigAllNodes" SG_ 2158813184 ODIIIPC_ODIInd1 1;
BA_ "GenSigDeltaValue" SG_ 2158813184 ODIIIPC_FUCID 1;
BA_ "GenSigSendType" SG_ 2158813184 ODIIIPC_FUCID 12;
BA_ "GenSigSendOnInit" SG_ 2158813184 ODIIIPC_FUCID 1;
BA_ "VNSigInfotainment" SG_ 2158813184 ODIIIPC_FUCID 1;
BA_ "SignalType" SG_ 2158813184 ODIIIPC_FUCID "UNM";
BA_ "PacketOrder" SG_ 2158813184 ODIIIPC_FUCID 1;
BA_ "SignalLongName" SG_ 2158813184 ODIIIPC_FUCID "Open Display Interface Indication IPC : Functional Unit Class ID";
BA_ "VNSigAllNodes" SG_ 2158813184 ODIIIPC_FUCID 1;
BA_REL_ "GenSigSuprvResp" BU_SG_REL_ ICS_LE SG_ 2154962944 PassHCSMInd3 1;
BA_REL_ "GenSigSuprvResp" BU_SG_REL_ ICS_LE SG_ 2154962944 PassHCSMInd2 1;
BA_REL_ "GenSigSuprvResp" BU_SG_REL_ ICS_LE SG_ 2154962944 PassHCSMInd1 1;
BA_REL_ "GenSigSuprvResp" BU_SG_REL_ ICS_LE SG_ 2154962944 PassHCSMIndReq 1;
BA_REL_ "GenSigSuprvResp" BU_SG_REL_ VCU_LE SG_ 2154962944 PassHCSLSeatLev5 1;
BA_REL_ "GenSigSuprvResp" BU_SG_REL_ IPC_LE SG_ 2154962944 PassHCSLSeatLev5 1;
BA_REL_ "GenSigSuprvResp" BU_SG_REL_ ICS_LE SG_ 2154962944 PassHCSLSeatLev5 1;
BA_REL_ "GenSigSuprvResp" BU_SG_REL_ VCU_LE SG_ 2154962944 PassHCSLSeatLev4 1;
BA_REL_ "GenSigSuprvResp" BU_SG_REL_ IPC_LE SG_ 2154962944 PassHCSLSeatLev4 1;
BA_REL_ "GenSigSuprvResp" BU_SG_REL_ ICS_LE SG_ 2154962944 PassHCSLSeatLev4 1;
BA_REL_ "GenSigSuprvResp" BU_SG_REL_ VCU_LE SG_ 2154962944 PassHCSLSeatLev3 1;
BA_REL_ "GenSigSuprvResp" BU_SG_REL_ IPC_LE SG_ 2154962944 PassHCSLSeatLev3 1;
BA_REL_ "GenSigSuprvResp" BU_SG_REL_ ICS_LE SG_ 2154962944 PassHCSLSeatLev3 1;
BA_REL_ "GenSigSuprvResp" BU_SG_REL_ VCU_LE SG_ 2154962944 PassHCSLSeatLev2 1;
BA_REL_ "GenSigSuprvResp" BU_SG_REL_ IPC_LE SG_ 2154962944 PassHCSLSeatLev2 1;
BA_REL_ "GenSigSuprvResp" BU_SG_REL_ ICS_LE SG_ 2154962944 PassHCSLSeatLev2 1;
BA_REL_ "GenSigSuprvResp" BU_SG_REL_ VCU_LE SG_ 2154962944 PassHCSLSeatLev1 1;
BA_REL_ "GenSigSuprvResp" BU_SG_REL_ IPC_LE SG_ 2154962944 PassHCSLSeatLev1 1;
BA_REL_ "GenSigSuprvResp" BU_SG_REL_ ICS_LE SG_ 2154962944 PassHCSLSeatLev1 1;
BA_REL_ "GenSigSuprvResp" BU_SG_REL_ VCU_LE SG_ 2154962944 PassHCSLIndReq 1;
BA_REL_ "GenSigSuprvResp" BU_SG_REL_ IPC_LE SG_ 2154962944 PassHCSLIndReq 1;
BA_REL_ "GenSigSuprvResp" BU_SG_REL_ ICS_LE SG_ 2154962944 PassHCSLIndReq 1;
BA_REL_ "GenSigSuprvResp" BU_SG_REL_ ICS_LE SG_ 2154962944 DrvHCSMInd1 1;
BA_REL_ "GenSigSuprvResp" BU_SG_REL_ ICS_LE SG_ 2154962944 DrvHCSMIndReq 1;
BA_REL_ "GenSigSuprvResp" BU_SG_REL_ ICS_LE SG_ 2154962944 DrvHCSMInd3 1;
BA_REL_ "GenSigSuprvResp" BU_SG_REL_ ICS_LE SG_ 2154962944 DrvHCSMInd2 1;
BA_REL_ "GenSigSuprvResp" BU_SG_REL_ VCU_LE SG_ 2154962944 DrvHCSLSeatLev5 1;
BA_REL_ "GenSigSuprvResp" BU_SG_REL_ IPC_LE SG_ 2154962944 DrvHCSLSeatLev5 1;
BA_REL_ "GenSigSuprvResp" BU_SG_REL_ ICS_LE SG_ 2154962944 DrvHCSLSeatLev5 1;
BA_REL_ "GenSigSuprvResp" BU_SG_REL_ VCU_LE SG_ 2154962944 DrvHCSLSeatLev4 1;
BA_REL_ "GenSigSuprvResp" BU_SG_REL_ IPC_LE SG_ 2154962944 DrvHCSLSeatLev4 1;
BA_REL_ "GenSigSuprvResp" BU_SG_REL_ ICS_LE SG_ 2154962944 DrvHCSLSeatLev4 1;
BA_REL_ "GenSigSuprvResp" BU_SG_REL_ VCU_LE SG_ 2154962944 DrvHCSLSeatLev3 1;
BA_REL_ "GenSigSuprvResp" BU_SG_REL_ IPC_LE SG_ 2154962944 DrvHCSLSeatLev3 1;
BA_REL_ "GenSigSuprvResp" BU_SG_REL_ ICS_LE SG_ 2154962944 DrvHCSLSeatLev3 1;
BA_REL_ "GenSigSuprvResp" BU_SG_REL_ VCU_LE SG_ 2154962944 DrvHCSLSeatLev2 1;
BA_REL_ "GenSigSuprvResp" BU_SG_REL_ IPC_LE SG_ 2154962944 DrvHCSLSeatLev2 1;
BA_REL_ "GenSigSuprvResp" BU_SG_REL_ ICS_LE SG_ 2154962944 DrvHCSLSeatLev2 1;
BA_REL_ "GenSigSuprvResp" BU_SG_REL_ VCU_LE SG_ 2154962944 DrvHCSLSeatLev1 1;
BA_REL_ "GenSigSuprvResp" BU_SG_REL_ IPC_LE SG_ 2154962944 DrvHCSLSeatLev1 1;
BA_REL_ "GenSigSuprvResp" BU_SG_REL_ ICS_LE SG_ 2154962944 DrvHCSLSeatLev1 1;
BA_REL_ "GenSigSuprvResp" BU_SG_REL_ VCU_LE SG_ 2154962944 DrvHCSLIndReq 1;
BA_REL_ "GenSigSuprvResp" BU_SG_REL_ IPC_LE SG_ 2154962944 DrvHCSLIndReq 1;
BA_REL_ "GenSigSuprvResp" BU_SG_REL_ ICS_LE SG_ 2154962944 DrvHCSLIndReq 1;
BA_REL_ "GenSigSuprvResp" BU_SG_REL_ ICS_LE SG_ 2151825408 OtsAirTmp 1;
BA_REL_ "GenSigSuprvResp" BU_SG_REL_ RadioHead_LE SG_ 2151825408 OtsAirTmpCrVal 1;
BA_REL_ "GenSigSuprvResp" BU_SG_REL_ RadioHead_LE SG_ 2151825408 OtsAirTmpCrVal 1;
BA_REL_ "GenSigSuprvResp" BU_SG_REL_ VCU_LE SG_ 2151825408 OtsAirTmpCrVal 1;
BA_REL_ "GenSigSuprvResp" BU_SG_REL_ VCU_LE SG_ 2151825408 OtsAirTmpCrVal 1;
BA_REL_ "GenSigSuprvResp" BU_SG_REL_ VCU_LE SG_ 2151825408 OtsAirTmpCrVal 1;
BA_REL_ "GenSigSuprvResp" BU_SG_REL_ IPC_LE SG_ 2151825408 OtsAirTmpCrVal 1;
BA_REL_ "GenSigSuprvResp" BU_SG_REL_ VPM_LE SG_ 2150760448 NotEventStat 1;
BA_REL_ "GenSigSuprvResp" BU_SG_REL_ V2V_LE SG_ 2150760448 SIRDpl 1;
BA_REL_ "GenSigSuprvResp" BU_SG_REL_ TCP_LE SG_ 2150760448 SIRDpl 1;
BA_REL_ "GenSigSuprvResp" BU_SG_REL_ ONSTAR_LE SG_ 2150760448 SIRDpl 1;
BA_REL_ "GenSigSuprvResp" BU_SG_REL_ VCU_LE SG_ 2150760448 SIRDpl 1;
BA_REL_ "GenSigSuprvResp" BU_SG_REL_ RadioHead_LE SG_ 2150760448 SIRDpl 1;
BA_REL_ "GenSigSuprvResp" BU_SG_REL_ ICS_LE SG_ 2150760448 SIRDpl 1;
BA_REL_ "GenSigSuprvResp" BU_SG_REL_ CSM_LE SG_ 2150227968 PhnSpRcgnApSt 1;
BA_REL_ "GenSigSuprvResp" BU_SG_REL_ OTIM_LE SG_ 2150227968 PhnSpRcgnApSt 1;
BA_REL_ "GenSigSuprvResp" BU_SG_REL_ VCU_LE SG_ 2150227968 PhnSpRcgnApSt 1;
BA_REL_ "GenSigSuprvResp" BU_SG_REL_ RadioHead_LE SG_ 2150227968 PhnSpRcgnApSt 1;
BA_REL_ "GenSigSuprvResp" BU_SG_REL_ RSC_LE SG_ 2155249664 RRHCSMInd3 1;
BA_REL_ "GenSigSuprvResp" BU_SG_REL_ RSA_LE SG_ 2155249664 RRHCSMInd3 1;
BA_REL_ "GenSigSuprvResp" BU_SG_REL_ RSC_LE SG_ 2155249664 RRHCSMInd2 1;
BA_REL_ "GenSigSuprvResp" BU_SG_REL_ RSA_LE SG_ 2155249664 RRHCSMInd2 1;
BA_REL_ "GenSigSuprvResp" BU_SG_REL_ RSC_LE SG_ 2155249664 RRHCSMInd1 1;
BA_REL_ "GenSigSuprvResp" BU_SG_REL_ RSA_LE SG_ 2155249664 RRHCSMInd1 1;
BA_REL_ "GenSigSuprvResp" BU_SG_REL_ RSC_LE SG_ 2155249664 RRHCSMIndReq 1;
BA_REL_ "GenSigSuprvResp" BU_SG_REL_ RSA_LE SG_ 2155249664 RRHCSMIndReq 1;
BA_REL_ "GenSigSuprvResp" BU_SG_REL_ VCU_LE SG_ 2155249664 RRHCSLSeatLev5 1;
BA_REL_ "GenSigSuprvResp" BU_SG_REL_ IPC_LE SG_ 2155249664 RRHCSLSeatLev5 1;
BA_REL_ "GenSigSuprvResp" BU_SG_REL_ RSC_LE SG_ 2155249664 RRHCSLSeatLev5 1;
BA_REL_ "GenSigSuprvResp" BU_SG_REL_ RSA_LE SG_ 2155249664 RRHCSLSeatLev5 1;
BA_REL_ "GenSigSuprvResp" BU_SG_REL_ VCU_LE SG_ 2155249664 RRHCSLSeatLev4 1;
BA_REL_ "GenSigSuprvResp" BU_SG_REL_ IPC_LE SG_ 2155249664 RRHCSLSeatLev4 1;
BA_REL_ "GenSigSuprvResp" BU_SG_REL_ RSC_LE SG_ 2155249664 RRHCSLSeatLev4 1;
BA_REL_ "GenSigSuprvResp" BU_SG_REL_ RSA_LE SG_ 2155249664 RRHCSLSeatLev4 1;
BA_REL_ "GenSigSuprvResp" BU_SG_REL_ VCU_LE SG_ 2155249664 RRHCSLSeatLev3 1;
BA_REL_ "GenSigSuprvResp" BU_SG_REL_ IPC_LE SG_ 2155249664 RRHCSLSeatLev3 1;
BA_REL_ "GenSigSuprvResp" BU_SG_REL_ RSC_LE SG_ 2155249664 RRHCSLSeatLev3 1;
BA_REL_ "GenSigSuprvResp" BU_SG_REL_ RSA_LE SG_ 2155249664 RRHCSLSeatLev3 1;
BA_REL_ "GenSigSuprvResp" BU_SG_REL_ VCU_LE SG_ 2155249664 RRHCSLSeatLev2 1;
BA_REL_ "GenSigSuprvResp" BU_SG_REL_ IPC_LE SG_ 2155249664 RRHCSLSeatLev2 1;
BA_REL_ "GenSigSuprvResp" BU_SG_REL_ RSC_LE SG_ 2155249664 RRHCSLSeatLev2 1;
BA_REL_ "GenSigSuprvResp" BU_SG_REL_ RSA_LE SG_ 2155249664 RRHCSLSeatLev2 1;
BA_REL_ "GenSigSuprvResp" BU_SG_REL_ VCU_LE SG_ 2155249664 RRHCSLSeatLev1 1;
BA_REL_ "GenSigSuprvResp" BU_SG_REL_ IPC_LE SG_ 2155249664 RRHCSLSeatLev1 1;
BA_REL_ "GenSigSuprvResp" BU_SG_REL_ RSC_LE SG_ 2155249664 RRHCSLSeatLev1 1;
BA_REL_ "GenSigSuprvResp" BU_SG_REL_ RSA_LE SG_ 2155249664 RRHCSLSeatLev1 1;
BA_REL_ "GenSigSuprvResp" BU_SG_REL_ VCU_LE SG_ 2155249664 RRHCSLIndReq 1;
BA_REL_ "GenSigSuprvResp" BU_SG_REL_ IPC_LE SG_ 2155249664 RRHCSLIndReq 1;
BA_REL_ "GenSigSuprvResp" BU_SG_REL_ RSC_LE SG_ 2155249664 RRHCSLIndReq 1;
BA_REL_ "GenSigSuprvResp" BU_SG_REL_ RSA_LE SG_ 2155249664 RRHCSLIndReq 1;
BA_REL_ "GenSigSuprvResp" BU_SG_REL_ RSC_LE SG_ 2155249664 RLHCSMInd3 1;
BA_REL_ "GenSigSuprvResp" BU_SG_REL_ RSA_LE SG_ 2155249664 RLHCSMInd3 1;
BA_REL_ "GenSigSuprvResp" BU_SG_REL_ RSC_LE SG_ 2155249664 RLHCSMInd2 1;
BA_REL_ "GenSigSuprvResp" BU_SG_REL_ RSA_LE SG_ 2155249664 RLHCSMInd2 1;
BA_REL_ "GenSigSuprvResp" BU_SG_REL_ RSC_LE SG_ 2155249664 RLHCSMInd1 1;
BA_REL_ "GenSigSuprvResp" BU_SG_REL_ RSA_LE SG_ 2155249664 RLHCSMInd1 1;
BA_REL_ "GenSigSuprvResp" BU_SG_REL_ RSC_LE SG_ 2155249664 RLHCSMIndReq 1;
BA_REL_ "GenSigSuprvResp" BU_SG_REL_ RSA_LE SG_ 2155249664 RLHCSMIndReq 1;
BA_REL_ "GenSigSuprvResp" BU_SG_REL_ VCU_LE SG_ 2155249664 RLHCSLSeatLev5 1;
BA_REL_ "GenSigSuprvResp" BU_SG_REL_ IPC_LE SG_ 2155249664 RLHCSLSeatLev5 1;
BA_REL_ "GenSigSuprvResp" BU_SG_REL_ RSC_LE SG_ 2155249664 RLHCSLSeatLev5 1;
BA_REL_ "GenSigSuprvResp" BU_SG_REL_ RSA_LE SG_ 2155249664 RLHCSLSeatLev5 1;
BA_REL_ "GenSigSuprvResp" BU_SG_REL_ VCU_LE SG_ 2155249664 RLHCSLSeatLev4 1;
BA_REL_ "GenSigSuprvResp" BU_SG_REL_ IPC_LE SG_ 2155249664 RLHCSLSeatLev4 1;
BA_REL_ "GenSigSuprvResp" BU_SG_REL_ RSC_LE SG_ 2155249664 RLHCSLSeatLev4 1;
BA_REL_ "GenSigSuprvResp" BU_SG_REL_ RSA_LE SG_ 2155249664 RLHCSLSeatLev4 1;
BA_REL_ "GenSigSuprvResp" BU_SG_REL_ VCU_LE SG_ 2155249664 RLHCSLSeatLev3 1;
BA_REL_ "GenSigSuprvResp" BU_SG_REL_ IPC_LE SG_ 2155249664 RLHCSLSeatLev3 1;
BA_REL_ "GenSigSuprvResp" BU_SG_REL_ RSC_LE SG_ 2155249664 RLHCSLSeatLev3 1;
BA_REL_ "GenSigSuprvResp" BU_SG_REL_ RSA_LE SG_ 2155249664 RLHCSLSeatLev3 1;
BA_REL_ "GenSigSuprvResp" BU_SG_REL_ VCU_LE SG_ 2155249664 RLHCSLSeatLev2 1;
BA_REL_ "GenSigSuprvResp" BU_SG_REL_ IPC_LE SG_ 2155249664 RLHCSLSeatLev2 1;
BA_REL_ "GenSigSuprvResp" BU_SG_REL_ RSC_LE SG_ 2155249664 RLHCSLSeatLev2 1;
BA_REL_ "GenSigSuprvResp" BU_SG_REL_ RSA_LE SG_ 2155249664 RLHCSLSeatLev2 1;
BA_REL_ "GenSigSuprvResp" BU_SG_REL_ VCU_LE SG_ 2155249664 RLHCSLSeatLev1 1;
BA_REL_ "GenSigSuprvResp" BU_SG_REL_ IPC_LE SG_ 2155249664 RLHCSLSeatLev1 1;
BA_REL_ "GenSigSuprvResp" BU_SG_REL_ RSC_LE SG_ 2155249664 RLHCSLSeatLev1 1;
BA_REL_ "GenSigSuprvResp" BU_SG_REL_ RSA_LE SG_ 2155249664 RLHCSLSeatLev1 1;
BA_REL_ "GenSigSuprvResp" BU_SG_REL_ VCU_LE SG_ 2155249664 RLHCSLIndReq 1;
BA_REL_ "GenSigSuprvResp" BU_SG_REL_ IPC_LE SG_ 2155249664 RLHCSLIndReq 1;
BA_REL_ "GenSigSuprvResp" BU_SG_REL_ RSC_LE SG_ 2155249664 RLHCSLIndReq 1;
BA_REL_ "GenSigSuprvResp" BU_SG_REL_ RSA_LE SG_ 2155249664 RLHCSLIndReq 1;
BA_REL_ "GenSigSuprvResp" BU_SG_REL_ VCU_LE SG_ 2154741760 RSAPrsnt 1;
BA_REL_ "GenSigSuprvResp" BU_SG_REL_ VCU_LE SG_ 2154741760 RSAPrsnt 1;
BA_REL_ "GenSigSuprvResp" BU_SG_REL_ RadioHead_LE SG_ 2154741760 RSAPrsnt 1;
BA_REL_ "GenSigSuprvResp" BU_SG_REL_ RadioHead_LE SG_ 2154741760 RSAPrsnt 1;
VAL_ 2154971136 PassHCSeatSw3Act 1 "true" 0 "false" ;
VAL_ 2154971136 PassHCSeatSw2Act 1 "true" 0 "false" ;
VAL_ 2154971136 PassHCSeatSw1Act 1 "true" 0 "false" ;
VAL_ 2154971136 DrvHCSeatSw3Act 1 "true" 0 "false" ;
VAL_ 2154971136 DrvHCSeatSw2Act 1 "true" 0 "false" ;
VAL_ 2154971136 DrvHCSeatSw1Act 1 "true" 0 "false" ;
VAL_ 2154962944 PassHCSMInd3 1 "true" 0 "false" ;
VAL_ 2154962944 PassHCSMInd2 1 "true" 0 "false" ;
VAL_ 2154962944 PassHCSMInd1 1 "true" 0 "false" ;
VAL_ 2154962944 PassHCSMIndReq 3 "Flash Rate #2 Indication" 2 "Flash Rate #1 Indication" 1 "Continuous Indication" 0 "Off" ;
VAL_ 2154962944 PassHCSLSeatLev5 1 "true" 0 "false" ;
VAL_ 2154962944 PassHCSLSeatLev4 1 "true" 0 "false" ;
VAL_ 2154962944 PassHCSLSeatLev3 1 "true" 0 "false" ;
VAL_ 2154962944 PassHCSLSeatLev2 1 "true" 0 "false" ;
VAL_ 2154962944 PassHCSLSeatLev1 1 "true" 0 "false" ;
VAL_ 2154962944 PassHCSLIndReq 3 "Flash Rate #2 Indication" 2 "Flash Rate #1 Indication" 1 "Continuous Indication" 0 "Off" ;
VAL_ 2154962944 DrvHCSMInd1 1 "true" 0 "false" ;
VAL_ 2154962944 DrvHCSMIndReq 3 "Flash Rate #2 Indication" 2 "Flash Rate #1 Indication" 1 "Continuous Indication" 0 "Off" ;
VAL_ 2154962944 DrvHCSMInd3 1 "true" 0 "false" ;
VAL_ 2154962944 DrvHCSMInd2 1 "true" 0 "false" ;
VAL_ 2154962944 DrvHCSLSeatLev5 1 "true" 0 "false" ;
VAL_ 2154962944 DrvHCSLSeatLev4 1 "true" 0 "false" ;
VAL_ 2154962944 DrvHCSLSeatLev3 1 "true" 0 "false" ;
VAL_ 2154962944 DrvHCSLSeatLev2 1 "true" 0 "false" ;
VAL_ 2154962944 DrvHCSLSeatLev1 1 "true" 0 "false" ;
VAL_ 2154962944 DrvHCSLIndReq 3 "Flash Rate #2 Indication" 2 "Flash Rate #1 Indication" 1 "Continuous Indication" 0 "Off" ;
VAL_ 2151825408 OtsAirTmpV 1 "Invalid" 0 "Valid" ;
VAL_ 2151825408 OtsAirTmpCrValV 1 "Invalid" 0 "Valid" ;
VAL_ 2151825408 OtsAirTmpCrValMsk 0 "Don't Use Data" 1 "Use Data" ;
VAL_ 2150760448 NotSndRwRtSeatStat 0 "Unknown" 1 "Unfastened" 2 "Fastened" ;
VAL_ 2150760448 NotSndRwMdlSeatStat 0 "Unknown" 1 "Unfastened" 2 "Fastened" ;
VAL_ 2150760448 NotSndRwLtSeatStat 0 "Unknown" 1 "Unfastened" 2 "Fastened" ;
VAL_ 2150760448 NotPsSeatStat 0 "Unknown" 1 "Unfastened" 2 "Fastened" ;
VAL_ 2150760448 NotDrvSeatStat 0 "Unknown" 1 "Unfastened" 2 "Fastened" ;
VAL_ 2150760448 NotSecRowRtSeaOccStat 2 "Occupied" 1 "Empty" 0 "Unknown" ;
VAL_ 2150760448 NotSecRowLeSeaOccStat 2 "Occupied" 1 "Empty" 0 "Unknown" ;
VAL_ 2150760448 NotSecRowCtSeaOccStat 2 "Occupied" 1 "Empty" 0 "Unknown" ;
VAL_ 2150760448 NotiFrntPasSeatOccSta 5 "OccupiedLarge" 4 "OccupiedSmall" 3 "OccupiedChildseat" 2 "OccupiedUnknown" 1 "Empty" 0 "Unknown" ;
VAL_ 2150760448 NotEventStat 2 "Pretensioner Deployment Event" 1 "Near Deployment Event" 0 "No Event" 3 "Airbag Deployment Event" ;
VAL_ 2150760448 NESSRoSevSt 1 "true" 0 "false" ;
VAL_ 2150760448 NESSRiSiSevSt 1 "true" 0 "false" ;
VAL_ 2150760448 NESSReImpSevSt 1 "true" 0 "false" ;
VAL_ 2150760448 NESSLeSiSevSt 1 "true" 0 "false" ;
VAL_ 2150760448 NESSFrImpSt2SevSt 1 "true" 0 "false" ;
VAL_ 2150760448 NESSFrImpSt1SevSt 1 "true" 0 "false" ;
VAL_ 2150760448 NESSFrImpPreSevSt 1 "true" 0 "false" ;
VAL_ 2150760448 NEDLSRtSdArbgDld 1 "true" 0 "false" ;
VAL_ 2150760448 NEDLSLtSdArbgDld 1 "true" 0 "false" ;
VAL_ 2150760448 NEDLSSdCrtnArbgDpld 1 "true" 0 "false" ;
VAL_ 2150760448 NEDLSPaFrSt2De 1 "true" 0 "false" ;
VAL_ 2150760448 NEDLSPaFrSt1De 1 "true" 0 "false" ;
VAL_ 2150760448 NEDLSDrFrSt2De 1 "true" 0 "false" ;
VAL_ 2150760448 NEDLSDrFrSt1De 1 "true" 0 "false" ;
VAL_ 2150760448 SIRDpl 1 "true" 0 "false" ;
VAL_ 2150227968 PhnSpRcgnApSt 3 "Unused" 2 "Audio Prompt Active" 1 "Speech Rec Active" 0 "Inactive" ;
VAL_ 2150219776 PhnSpRcgnRq 3 "Stop" 2 "Move On / Skip" 1 "Start" 0 "No Action" ;
VAL_ 2150219776 VcRecVcFdbckSt 1 "Active" 0 "Inactive" ;
VAL_ 2155266048 RRHCSeatSw3Act 1 "true" 0 "false" ;
VAL_ 2155266048 RRHCSeatSw2Act 1 "true" 0 "false" ;
VAL_ 2155266048 RRHCSeatSw1Act 1 "true" 0 "false" ;
VAL_ 2155266048 RLHCSeatSw3Act 1 "true" 0 "false" ;
VAL_ 2155266048 RLHCSeatSw2Act 1 "true" 0 "false" ;
VAL_ 2155266048 RLHCSeatSw1Act 1 "true" 0 "false" ;
VAL_ 2155249664 RRHCSMInd3 1 "true" 0 "false" ;
VAL_ 2155249664 RRHCSMInd2 1 "true" 0 "false" ;
VAL_ 2155249664 RRHCSMInd1 1 "true" 0 "false" ;
VAL_ 2155249664 RRHCSMIndReq 3 "Flash Rate #2 Indication" 2 "Flash Rate #1 Indication" 1 "Continuous Indication" 0 "Off" ;
VAL_ 2155249664 RRHCSLSeatLev5 1 "true" 0 "false" ;
VAL_ 2155249664 RRHCSLSeatLev4 1 "true" 0 "false" ;
VAL_ 2155249664 RRHCSLSeatLev3 1 "true" 0 "false" ;
VAL_ 2155249664 RRHCSLSeatLev2 1 "true" 0 "false" ;
VAL_ 2155249664 RRHCSLSeatLev1 1 "true" 0 "false" ;
VAL_ 2155249664 RRHCSLIndReq 3 "Flash Rate #2 Indication" 2 "Flash Rate #1 Indication" 1 "Continuous Indication" 0 "Off" ;
VAL_ 2155249664 RLHCSMInd3 1 "true" 0 "false" ;
VAL_ 2155249664 RLHCSMInd2 1 "true" 0 "false" ;
VAL_ 2155249664 RLHCSMInd1 1 "true" 0 "false" ;
VAL_ 2155249664 RLHCSMIndReq 3 "Flash Rate #2 Indication" 2 "Flash Rate #1 Indication" 1 "Continuous Indication" 0 "Off" ;
VAL_ 2155249664 RLHCSLSeatLev5 1 "true" 0 "false" ;
VAL_ 2155249664 RLHCSLSeatLev4 1 "true" 0 "false" ;
VAL_ 2155249664 RLHCSLSeatLev3 1 "true" 0 "false" ;
VAL_ 2155249664 RLHCSLSeatLev2 1 "true" 0 "false" ;
VAL_ 2155249664 RLHCSLSeatLev1 1 "true" 0 "false" ;
VAL_ 2155249664 RLHCSLIndReq 3 "Flash Rate #2 Indication" 2 "Flash Rate #1 Indication" 1 "Continuous Indication" 0 "Off" ;
VAL_ 2154741760 RSAPrsnt 1 "true" 0 "false" ;
VAL_ 2159132672 ODIAR_DspMID 128 "Reserved" 64 "Reserved" 32 "OTIM" 16 "RearDisplayTwo" 8 "RearDisplayOne" 4 "AuxIP" 2 "CenterStack" 1 "IPC" ;
VAL_ 2159132672 ODIAR_DaTy 21 "Bitmap" 20 "DecimalShort" 19 "HoursOfDay" 18 "Character" 17 "Fuel Consumption Inverted" 16 "Fuel Consumption" 15 "Pressure" 14 "Temperature" 13 "Volume" 12 "DistanceShort" 11 "DistanceLong" 10 "BitmapId" 9 "TextId" 8 "Pictogram" 7 "List " 6 "Date" 5 "Time " 4 "Decimal" 3 "EnumerationValue" 2 "Integer" 1 "String" 0 "Speed" ;
VAL_ 2158952448 ODDMR_ReqType 0 "Subscribe: FU sends DynData back and then on change) " 1 "Unsubscribe: cancel previous Subscribe" ;
VAL_ 2158952448 ODDMR_DispMID 128 "Reserved" 64 "Reserved" 32 "OTIM" 16 "RearDisplayTwo" 8 "RearDisplayOne" 4 "AuxIP" 2 "CenterStack" 1 "IPC" ;
VAL_ 2158952448 ODDMR_DataID2Vld 1 "true" 0 "false" ;
VAL_ 2158952448 ODDMR_DataID3Vld 1 "true" 0 "false" ;
VAL_ 2158952448 ODDMR_DataID4Vld 1 "true" 0 "false" ;
VAL_ 2158952448 ODDMR_DataID5Vld 1 "true" 0 "false" ;
VAL_ 2158944256 ODDLR_WrpArnd 1 "true" 0 "false" ;
VAL_ 2158944256 ODDLR_ReqType 0 "Subscribe: FU sends DynData back and then on change) " 1 "Unsubscribe: cancel previous Subscribe" ;
VAL_ 2158944256 ODDLR_ReqDir 1 "true" 0 "false" ;
VAL_ 2158944256 ODDLR_DspMID 128 "Reserved" 64 "Reserved" 32 "OTIM" 16 "RearDisplayTwo" 8 "RearDisplayOne" 4 "AuxIP" 2 "CenterStack" 1 "IPC" ;
VAL_ 2158944256 ODDLR_BckgndFlag 1 "Background response" 0 "Immediate response required" ;
VAL_ 2158903296 ODDMA_ReqType 0 "Subscribe: FU sends DynData back and then on change) " 1 "Unsubscribe: cancel previous Subscribe" ;
VAL_ 2158903296 ODDMA_DispMID 128 "Reserved" 64 "Reserved" 32 "OTIM" 16 "RearDisplayTwo" 8 "RearDisplayOne" 4 "AuxIP" 2 "CenterStack" 1 "IPC" ;
VAL_ 2158903296 ODDMA_DataID2Vld 1 "true" 0 "false" ;
VAL_ 2158903296 ODDMA_DataID3Vld 1 "true" 0 "false" ;
VAL_ 2158903296 ODDMA_DataID4Vld 1 "true" 0 "false" ;
VAL_ 2158903296 ODDMA_DataID5Vld 1 "true" 0 "false" ;
VAL_ 2158870528 ODDLA_WrpArnd 1 "true" 0 "false" ;
VAL_ 2158870528 ODDLA_ReqType 0 "Subscribe: FU sends DynData back and then on change) " 1 "Unsubscribe: cancel previous Subscribe" ;
VAL_ 2158870528 ODDLA_ReqDir 1 "true" 0 "false" ;
VAL_ 2158870528 ODDLA_DspMID 128 "Reserved" 64 "Reserved" 32 "OTIM" 16 "RearDisplayTwo" 8 "RearDisplayOne" 4 "AuxIP" 2 "CenterStack" 1 "IPC" ;
VAL_ 2158870528 ODDLA_BckgndFlag 1 "Background response" 0 "Immediate response required" ;
VAL_ 2158837760 ODIAA_DspMID 128 "Reserved" 64 "Reserved" 32 "OTIM" 16 "RearDisplayTwo" 8 "RearDisplayOne" 4 "AuxIP" 2 "CenterStack" 1 "IPC" ;
VAL_ 2158837760 ODIAA_DaTy 21 "Bitmap" 20 "DecimalShort" 19 "HoursOfDay" 18 "Character" 17 "Fuel Consumption Inverted" 16 "Fuel Consumption" 15 "Pressure" 14 "Temperature" 13 "Volume" 12 "DistanceShort" 11 "DistanceLong" 10 "BitmapId" 9 "TextId" 8 "Pictogram" 7 "List " 6 "Date" 5 "Time " 4 "Decimal" 3 "EnumerationValue" 2 "Integer" 1 "String" 0 "Speed" ;
VAL_ 2158796800 ODII_ODIInd55 1 "true" 0 "false" ;
VAL_ 2158796800 ODII_ODIInd54 1 "true" 0 "false" ;
VAL_ 2158796800 ODII_ODIInd53 1 "true" 0 "false" ;
VAL_ 2158796800 ODII_ODIInd52 1 "true" 0 "false" ;
VAL_ 2158796800 ODII_ODIInd51 1 "true" 0 "false" ;
VAL_ 2158796800 ODII_ODIInd50 1 "true" 0 "false" ;
VAL_ 2158796800 ODII_ODIInd27 1 "true" 0 "false" ;
VAL_ 2158796800 ODII_ODIInd26 1 "true" 0 "false" ;
VAL_ 2158796800 ODII_ODIInd25 1 "true" 0 "false" ;
VAL_ 2158796800 ODII_ODIInd24 1 "true" 0 "false" ;
VAL_ 2158796800 ODII_ODIInd23 1 "true" 0 "false" ;
VAL_ 2158796800 ODII_ODIInd22 1 "true" 0 "false" ;
VAL_ 2158796800 ODII_ODIInd21 1 "true" 0 "false" ;
VAL_ 2158796800 ODII_ODIInd20 1 "true" 0 "false" ;
VAL_ 2158796800 ODII_ODIInd19 1 "true" 0 "false" ;
VAL_ 2158796800 ODII_ODIInd18 1 "true" 0 "false" ;
VAL_ 2158796800 ODII_ODIInd17 1 "true" 0 "false" ;
VAL_ 2158796800 ODII_ODIInd16 1 "true" 0 "false" ;
VAL_ 2158796800 ODII_ODIInd15 1 "true" 0 "false" ;
VAL_ 2158796800 ODII_ODIInd14 1 "true" 0 "false" ;
VAL_ 2158796800 ODII_ODIInd13 1 "true" 0 "false" ;
VAL_ 2158796800 ODII_ODIInd12 1 "true" 0 "false" ;
VAL_ 2158796800 ODII_ODIInd11 1 "true" 0 "false" ;
VAL_ 2158796800 ODII_ODIInd10 1 "true" 0 "false" ;
VAL_ 2158796800 ODII_ODIInd9 1 "true" 0 "false" ;
VAL_ 2158796800 ODII_ODIInd8 1 "true" 0 "false" ;
VAL_ 2158796800 ODII_ODIInd7 1 "true" 0 "false" ;
VAL_ 2158796800 ODII_ODIInd6 1 "true" 0 "false" ;
VAL_ 2158796800 ODII_ODIInd5 1 "true" 0 "false" ;
VAL_ 2158796800 ODII_ODIInd4 1 "true" 0 "false" ;
VAL_ 2158796800 ODII_ODIInd3 1 "true" 0 "false" ;
VAL_ 2158796800 ODII_ODIInd2 1 "true" 0 "false" ;
VAL_ 2158796800 ODII_ODIInd1 1 "true" 0 "false" ;
VAL_ 2158796800 ODII_ODIInd56 1 "true" 0 "false" ;
VAL_ 2158796800 ODII_ODIInd49 1 "true" 0 "false" ;
VAL_ 2158796800 ODII_ODIInd48 1 "true" 0 "false" ;
VAL_ 2158796800 ODII_ODIInd47 1 "true" 0 "false" ;
VAL_ 2158796800 ODII_ODIInd46 1 "true" 0 "false" ;
VAL_ 2158796800 ODII_ODIInd45 1 "true" 0 "false" ;
VAL_ 2158796800 ODII_ODIInd44 1 "true" 0 "false" ;
VAL_ 2158796800 ODII_ODIInd43 1 "true" 0 "false" ;
VAL_ 2158796800 ODII_ODIInd42 1 "true" 0 "false" ;
VAL_ 2158796800 ODII_ODIInd41 1 "true" 0 "false" ;
VAL_ 2158796800 ODII_ODIInd40 1 "true" 0 "false" ;
VAL_ 2158796800 ODII_ODIInd39 1 "true" 0 "false" ;
VAL_ 2158796800 ODII_ODIInd38 1 "true" 0 "false" ;
VAL_ 2158796800 ODII_ODIInd37 1 "true" 0 "false" ;
VAL_ 2158796800 ODII_ODIInd36 1 "true" 0 "false" ;
VAL_ 2158796800 ODII_ODIInd35 1 "true" 0 "false" ;
VAL_ 2158796800 ODII_ODIInd34 1 "true" 0 "false" ;
VAL_ 2158796800 ODII_ODIInd33 1 "true" 0 "false" ;
VAL_ 2158796800 ODII_ODIInd32 1 "true" 0 "false" ;
VAL_ 2158796800 ODII_ODIInd31 1 "true" 0 "false" ;
VAL_ 2158796800 ODII_ODIInd30 1 "true" 0 "false" ;
VAL_ 2158796800 ODII_ODIInd29 1 "true" 0 "false" ;
VAL_ 2158796800 ODII_ODIInd28 1 "true" 0 "false" ;
VAL_ 2158813184 ODIIIPC_ODIInd56 1 "true" 0 "false" ;
VAL_ 2158813184 ODIIIPC_ODIInd55 1 "true" 0 "false" ;
VAL_ 2158813184 ODIIIPC_ODIInd54 1 "true" 0 "false" ;
VAL_ 2158813184 ODIIIPC_ODIInd53 1 "true" 0 "false" ;
VAL_ 2158813184 ODIIIPC_ODIInd52 1 "true" 0 "false" ;
VAL_ 2158813184 ODIIIPC_ODIInd51 1 "true" 0 "false" ;
VAL_ 2158813184 ODIIIPC_ODIInd50 1 "true" 0 "false" ;
VAL_ 2158813184 ODIIIPC_ODIInd49 1 "true" 0 "false" ;
VAL_ 2158813184 ODIIIPC_ODIInd48 1 "true" 0 "false" ;
VAL_ 2158813184 ODIIIPC_ODIInd47 1 "true" 0 "false" ;
VAL_ 2158813184 ODIIIPC_ODIInd46 1 "true" 0 "false" ;
VAL_ 2158813184 ODIIIPC_ODIInd45 1 "true" 0 "false" ;
VAL_ 2158813184 ODIIIPC_ODIInd44 1 "true" 0 "false" ;
VAL_ 2158813184 ODIIIPC_ODIInd43 1 "true" 0 "false" ;
VAL_ 2158813184 ODIIIPC_ODIInd42 1 "true" 0 "false" ;
VAL_ 2158813184 ODIIIPC_ODIInd41 1 "true" 0 "false" ;
VAL_ 2158813184 ODIIIPC_ODIInd40 1 "true" 0 "false" ;
VAL_ 2158813184 ODIIIPC_ODIInd39 1 "true" 0 "false" ;
VAL_ 2158813184 ODIIIPC_ODIInd38 1 "true" 0 "false" ;
VAL_ 2158813184 ODIIIPC_ODIInd9 1 "true" 0 "false" ;
VAL_ 2158813184 ODIIIPC_ODIInd8 1 "true" 0 "false" ;
VAL_ 2158813184 ODIIIPC_ODIInd7 1 "true" 0 "false" ;
VAL_ 2158813184 ODIIIPC_ODIInd6 1 "true" 0 "false" ;
VAL_ 2158813184 ODIIIPC_ODIInd5 1 "true" 0 "false" ;
VAL_ 2158813184 ODIIIPC_ODIInd4 1 "true" 0 "false" ;
VAL_ 2158813184 ODIIIPC_ODIInd3 1 "true" 0 "false" ;
VAL_ 2158813184 ODIIIPC_ODIInd37 1 "true" 0 "false" ;
VAL_ 2158813184 ODIIIPC_ODIInd36 1 "true" 0 "false" ;
VAL_ 2158813184 ODIIIPC_ODIInd35 1 "true" 0 "false" ;
VAL_ 2158813184 ODIIIPC_ODIInd34 1 "true" 0 "false" ;
VAL_ 2158813184 ODIIIPC_ODIInd33 1 "true" 0 "false" ;
VAL_ 2158813184 ODIIIPC_ODIInd32 1 "true" 0 "false" ;
VAL_ 2158813184 ODIIIPC_ODIInd31 1 "true" 0 "false" ;
VAL_ 2158813184 ODIIIPC_ODIInd30 1 "true" 0 "false" ;
VAL_ 2158813184 ODIIIPC_ODIInd29 1 "true" 0 "false" ;
VAL_ 2158813184 ODIIIPC_ODIInd28 1 "true" 0 "false" ;
VAL_ 2158813184 ODIIIPC_ODIInd27 1 "true" 0 "false" ;
VAL_ 2158813184 ODIIIPC_ODIInd26 1 "true" 0 "false" ;
VAL_ 2158813184 ODIIIPC_ODIInd25 1 "true" 0 "false" ;
VAL_ 2158813184 ODIIIPC_ODIInd24 1 "true" 0 "false" ;
VAL_ 2158813184 ODIIIPC_ODIInd23 1 "true" 0 "false" ;
VAL_ 2158813184 ODIIIPC_ODIInd22 1 "true" 0 "false" ;
VAL_ 2158813184 ODIIIPC_ODIInd21 1 "true" 0 "false" ;
VAL_ 2158813184 ODIIIPC_ODIInd20 1 "true" 0 "false" ;
VAL_ 2158813184 ODIIIPC_ODIInd19 1 "true" 0 "false" ;
VAL_ 2158813184 ODIIIPC_ODIInd18 1 "true" 0 "false" ;
VAL_ 2158813184 ODIIIPC_ODIInd17 1 "true" 0 "false" ;
VAL_ 2158813184 ODIIIPC_ODIInd16 1 "true" 0 "false" ;
VAL_ 2158813184 ODIIIPC_ODIInd15 1 "true" 0 "false" ;
VAL_ 2158813184 ODIIIPC_ODIInd14 1 "true" 0 "false" ;
VAL_ 2158813184 ODIIIPC_ODIInd13 1 "true" 0 "false" ;
VAL_ 2158813184 ODIIIPC_ODIInd12 1 "true" 0 "false" ;
VAL_ 2158813184 ODIIIPC_ODIInd11 1 "true" 0 "false" ;
VAL_ 2158813184 ODIIIPC_ODIInd10 1 "true" 0 "false" ;
VAL_ 2158813184 ODIIIPC_ODIInd2 1 "true" 0 "false" ;
VAL_ 2158813184 ODIIIPC_ODIInd1 1 "true" 0 "false" ;
SIG_GROUP_ 2154962944 PassHCSModeIndCtrl 1 : PassHCSMInd3 PassHCSMInd2 PassHCSMInd1 PassHCSMIndReq;
SIG_GROUP_ 2154962944 PassHCSeatLevIndCtrl 1 : PassHCSLSeatLev5 PassHCSLSeatLev4 PassHCSLSeatLev3 PassHCSLSeatLev2 PassHCSLSeatLev1 PassHCSLIndReq;
SIG_GROUP_ 2154962944 DrvHCSModeIndCtrl 1 : DrvHCSMInd1 DrvHCSMIndReq DrvHCSMInd3 DrvHCSMInd2;
SIG_GROUP_ 2154962944 DrvHCSLevIndCtrl 1 : DrvHCSLSeatLev5 DrvHCSLSeatLev4 DrvHCSLSeatLev3 DrvHCSLSeatLev2 DrvHCSLSeatLev1 DrvHCSLIndReq;
SIG_GROUP_ 2150760448 NoEvSevSt 1 : NESSRoSevSt NESSRiSiSevSt NESSReImpSevSt NESSLeSiSevSt NESSFrImpSt2SevSt NESSFrImpSt1SevSt NESSFrImpPreSevSt;
SIG_GROUP_ 2150760448 NoEvDeLoSt 1 : NEDLSRtSdArbgDld NEDLSLtSdArbgDld NEDLSSdCrtnArbgDpld NEDLSPaFrSt2De NEDLSPaFrSt1De NEDLSDrFrSt2De NEDLSDrFrSt1De;
SIG_GROUP_ 2155249664 RRHCSModeIndCtrl 1 : RRHCSMInd3 RRHCSMInd2 RRHCSMInd1 RRHCSMIndReq;
SIG_GROUP_ 2155249664 RRHCSeatLevIndCtrl 1 : RRHCSLSeatLev5 RRHCSLSeatLev4 RRHCSLSeatLev3 RRHCSLSeatLev2 RRHCSLSeatLev1 RRHCSLIndReq;
SIG_GROUP_ 2155249664 RLHCSModeIndCtrl 1 : RLHCSMInd3 RLHCSMInd2 RLHCSMInd1 RLHCSMIndReq;
SIG_GROUP_ 2155249664 RLHCSeatLevIndCtrl 1 : RLHCSLSeatLev5 RLHCSLSeatLev4 RLHCSLSeatLev3 RLHCSLSeatLev2 RLHCSLSeatLev1 RLHCSLIndReq;
SIG_GROUP_ 2159132672 ODIActn_RSD 1 : ODIAR_FUCID ODIAR_DspMID ODIAR_DaTy ODIAR_ActnVal ODIAR_ActnID;
SIG_GROUP_ 2158952448 ODIDynDataMltRq_RSD 1 : ODDMR_ReqType ODDMR_FUCID ODDMR_DispMID ODDMR_DataID2Vld ODDMR_DataID2 ODDMR_DataID3Vld ODDMR_DataID3 ODDMR_DataID1 ODDMR_DataID4Vld ODDMR_DataID4 ODDMR_DataID5Vld ODDMR_DataID5;
SIG_GROUP_ 2158944256 ODIDynDataLstRq_RSD 1 : ODDLR_SubIdReqM ODDLR_WrpArnd ODDLR_ReqType ODDLR_ReqDir ODDLR_NmEntries ODDLR_Idx ODDLR_FUCID ODDLR_DspMID ODDLR_DataId ODDLR_BckgndFlag;
SIG_GROUP_ 2158903296 ODIDynDataMltRq_AuxIP 1 : ODDMA_ReqType ODDMA_FUCID ODDMA_DispMID ODDMA_DataID2Vld ODDMA_DataID2 ODDMA_DataID3Vld ODDMA_DataID3 ODDMA_DataID1 ODDMA_DataID4Vld ODDMA_DataID4 ODDMA_DataID5Vld ODDMA_DataID5;
SIG_GROUP_ 2158870528 ODIDynDataLstRq_AxIP 1 : ODDLA_SubIdReqM ODDLA_WrpArnd ODDLA_ReqType ODDLA_ReqDir ODDLA_NmEntries ODDLA_Idx ODDLA_FUCID ODDLA_DspMID ODDLA_DataId ODDLA_BckgndFlag;
SIG_GROUP_ 2158837760 ODIActn_AxIP 1 : ODIAA_FUCID ODIAA_DspMID ODIAA_ActnVal ODIAA_ActnID ODIAA_DaTy;
SIG_GROUP_ 2158796800 ODIInd 1 : ODII_ODIInd55 ODII_ODIInd54 ODII_ODIInd53 ODII_ODIInd52 ODII_ODIInd51 ODII_ODIInd50 ODII_ODIInd27 ODII_ODIInd26 ODII_ODIInd25 ODII_ODIInd24 ODII_ODIInd23 ODII_ODIInd22 ODII_ODIInd21 ODII_ODIInd20 ODII_ODIInd19 ODII_ODIInd18 ODII_ODIInd17 ODII_ODIInd16 ODII_ODIInd15 ODII_ODIInd14 ODII_ODIInd13 ODII_ODIInd12 ODII_ODIInd11 ODII_ODIInd10 ODII_ODIInd9 ODII_ODIInd8 ODII_ODIInd7 ODII_ODIInd6 ODII_ODIInd5 ODII_ODIInd4 ODII_ODIInd3 ODII_ODIInd2 ODII_ODIInd1 ODII_ODIInd56 ODII_ODIInd49 ODII_ODIInd48 ODII_ODIInd47 ODII_ODIInd46 ODII_ODIInd45 ODII_ODIInd44 ODII_ODIInd43 ODII_ODIInd42 ODII_ODIInd41 ODII_ODIInd40 ODII_ODIInd39 ODII_ODIInd38 ODII_ODIInd37 ODII_ODIInd36 ODII_ODIInd35 ODII_ODIInd34 ODII_ODIInd33 ODII_ODIInd32 ODII_ODIInd31 ODII_ODIInd30 ODII_ODIInd29 ODII_ODIInd28 ODII_FUCID;
SIG_GROUP_ 2158813184 ODIInd_IPC 1 : ODIIIPC_ODIInd56 ODIIIPC_ODIInd55 ODIIIPC_ODIInd54 ODIIIPC_ODIInd53 ODIIIPC_ODIInd52 ODIIIPC_ODIInd51 ODIIIPC_ODIInd50 ODIIIPC_ODIInd49 ODIIIPC_ODIInd48 ODIIIPC_ODIInd47 ODIIIPC_ODIInd46 ODIIIPC_ODIInd45 ODIIIPC_ODIInd44 ODIIIPC_ODIInd43 ODIIIPC_ODIInd42 ODIIIPC_ODIInd41 ODIIIPC_ODIInd40 ODIIIPC_ODIInd39 ODIIIPC_ODIInd38 ODIIIPC_ODIInd9 ODIIIPC_ODIInd8 ODIIIPC_ODIInd7 ODIIIPC_ODIInd6 ODIIIPC_ODIInd5 ODIIIPC_ODIInd4 ODIIIPC_ODIInd3 ODIIIPC_ODIInd37 ODIIIPC_ODIInd36 ODIIIPC_ODIInd35 ODIIIPC_ODIInd34 ODIIIPC_ODIInd33 ODIIIPC_ODIInd32 ODIIIPC_ODIInd31 ODIIIPC_ODIInd30 ODIIIPC_ODIInd29 ODIIIPC_ODIInd28 ODIIIPC_ODIInd27 ODIIIPC_ODIInd26 ODIIIPC_ODIInd25 ODIIIPC_ODIInd24 ODIIIPC_ODIInd23 ODIIIPC_ODIInd22 ODIIIPC_ODIInd21 ODIIIPC_ODIInd20 ODIIIPC_ODIInd19 ODIIIPC_ODIInd18 ODIIIPC_ODIInd17 ODIIIPC_ODIInd16 ODIIIPC_ODIInd15 ODIIIPC_ODIInd14 ODIIIPC_ODIInd13 ODIIIPC_ODIInd12 ODIIIPC_ODIInd11 ODIIIPC_ODIInd10 ODIIIPC_ODIInd2 ODIIIPC_ODIInd1 ODIIIPC_FUCID;
